VERSION "HNNBNNNYNNNNNNNNNNNNNNNNNNNNNNNNNNNNNNNNNN/4/%%%/4/'%**4NNN///"

NS_ :

BS_:

BU_: BAP_Tester BedienDisp_vo BedienSG_hi CGS DDA Gateway Gateway_PAG GurtMikrofon OTA_FC ZR_High ZR_LIMU ZR_MIB_TOP_ab_Gen3 ZR_Standard

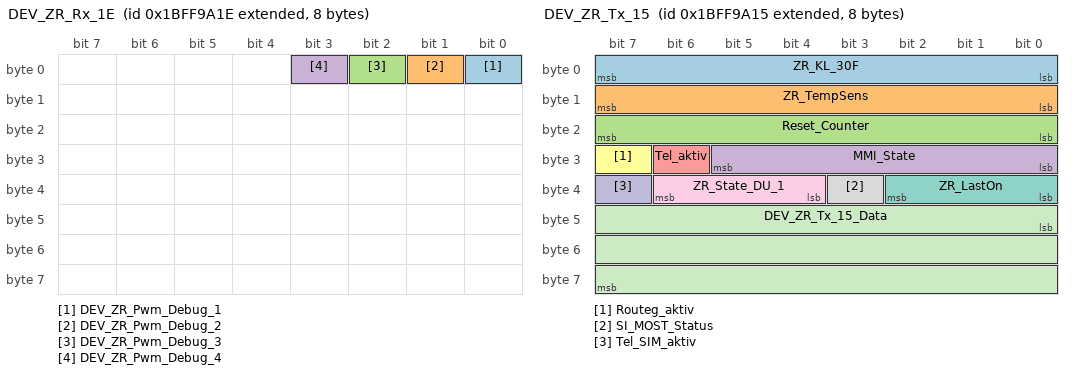
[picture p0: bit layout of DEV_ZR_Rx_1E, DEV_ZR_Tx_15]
BO_ 2617219614 DEV_ZR_Rx_1E: 8 Vector__XXX
 SG_ DEV_ZR_Pwm_Debug_1 : 0|1@1+ (1.0,0.0) [0.0|1] ""  ZR_High,ZR_MIB_TOP_ab_Gen3,ZR_Standard
 SG_ DEV_ZR_Pwm_Debug_2 : 1|1@1+ (1.0,0.0) [0.0|1] ""  ZR_High,ZR_MIB_TOP_ab_Gen3,ZR_Standard
 SG_ DEV_ZR_Pwm_Debug_3 : 2|1@1+ (1.0,0.0) [0.0|1] ""  ZR_High,ZR_MIB_TOP_ab_Gen3,ZR_Standard
 SG_ DEV_ZR_Pwm_Debug_4 : 3|1@1+ (1.0,0.0) [0.0|1] ""  ZR_High,ZR_MIB_TOP_ab_Gen3,ZR_Standard

BO_ 2617219604 DEV_ZR_Tx_14: 8 ZR_High
 SG_ DEV_ZR_Tx_14_Data : 0|64@1+ (1,0) [0|1] ""  Vector__XXX

BO_ 2617219605 DEV_ZR_Tx_15: 8 ZR_High
 SG_ ZR_KL_30F : 0|8@1+ (0.1,0) [0.0|25.3] "Unit_Volt"  Vector__XXX
 SG_ ZR_TempSens : 8|8@1+ (1,-55) [-55|127] "Unit_DegreCelsi"  Vector__XXX
 SG_ Reset_Counter : 16|8@1+ (1,0) [0|253] ""  Vector__XXX
 SG_ MMI_State : 24|6@1+ (1.0,0.0) [0.0|63] ""  Vector__XXX
 SG_ Tel_aktiv : 30|1@1+ (1.0,0.0) [0.0|1] ""  Vector__XXX
 SG_ Routeg_aktiv : 31|1@1+ (1.0,0.0) [0.0|1] ""  Vector__XXX
 SG_ ZR_LastOn : 32|3@1+ (1,0) [0|6] ""  Vector__XXX
 SG_ SI_MOST_Status : 35|1@1+ (1.0,0.0) [0.0|1] ""  Vector__XXX
 SG_ ZR_State_DU_1 : 36|3@1+ (1.0,0.0) [0.0|7] ""  Vector__XXX
 SG_ Tel_SIM_aktiv : 39|1@1+ (1.0,0.0) [0.0|1] ""  Vector__XXX
 SG_ DEV_ZR_Tx_15_Data : 40|24@1+ (1,0) [0|1] ""  Vector__XXX

BO_ 2549880610 DIA_SCON1_Req: 8 Gateway
 SG_ DIA_SCON1_Req_Data : 0|64@1+ (1.0,0.0) [0.0|18446744073709551615] ""  ZR_High,ZR_MIB_TOP_ab_Gen3

BO_ 2550011682 DIA_SCON1_Resp: 8 ZR_High
 SG_ DIA_SCON1_Resp_Data : 0|64@1+ (1.0,0.0) [0.0|18446744073709551615] ""  Gateway,Gateway_PAG

BO_ 2549880611 DIA_SCON2_Req: 8 Gateway
 SG_ DIA_SCON2_Req_Data : 0|64@1+ (1.0,0.0) [0.0|18446744073709551615] ""  ZR_High,ZR_MIB_TOP_ab_Gen3

BO_ 2550011683 DIA_SCON2_Resp: 8 ZR_High
 SG_ DIA_SCON2_Resp_Data : 0|64@1+ (1.0,0.0) [0.0|18446744073709551615] ""  Gateway,Gateway_PAG

BO_ 2549880473 DIA_SD3_Req: 8 Gateway
 SG_ DIA_SD3_Req_Data : 0|64@1+ (1.0,0.0) [0.0|18446744073709551615] ""  ZR_High,ZR_MIB_TOP_ab_Gen3

BO_ 2550011545 DIA_SD3_Resp: 8 ZR_High
 SG_ DIA_SD3_Resp_Data : 0|64@1+ (1.0,0.0) [0.0|18446744073709551615] ""  Gateway,Gateway_PAG

BO_ 2549880474 DIA_SD4_Req: 8 Gateway
 SG_ DIA_SD4_Req_Data : 0|64@1+ (1.0,0.0) [0.0|18446744073709551615] ""  ZR_High,ZR_MIB_TOP_ab_Gen3

BO_ 2550011546 DIA_SD4_Resp: 8 ZR_High
 SG_ DIA_SD4_Resp_Data : 0|64@1+ (1.0,0.0) [0.0|18446744073709551615] ""  Gateway,Gateway_PAG

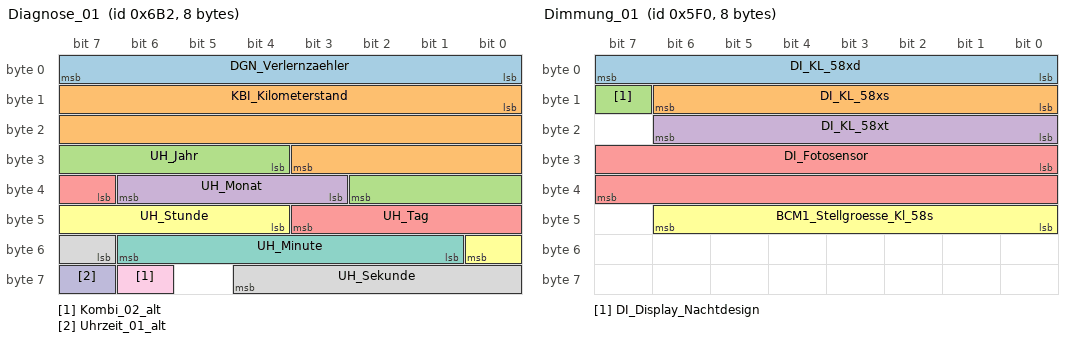
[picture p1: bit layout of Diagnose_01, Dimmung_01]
BO_ 1714 Diagnose_01: 8 Gateway
 SG_ DGN_Verlernzaehler : 0|8@1+ (1,0) [0|254] ""  BedienDisp_vo,BedienSG_hi,DDA,GurtMikrofon,OTA_FC,ZR_High,ZR_LIMU,ZR_MIB_TOP_ab_Gen3,ZR_Standard
 SG_ KBI_Kilometerstand : 8|20@1+ (1,0) [0|1048573] "Unit_KiloMeter"  BedienDisp_vo,BedienSG_hi,DDA,GurtMikrofon,OTA_FC,ZR_High,ZR_LIMU,ZR_MIB_TOP_ab_Gen3,ZR_Standard
 SG_ UH_Jahr : 28|7@1+ (1,2000) [2000|2127] "Unit_Year"  BedienDisp_vo,BedienSG_hi,DDA,GurtMikrofon,OTA_FC,ZR_High,ZR_LIMU,ZR_MIB_TOP_ab_Gen3,ZR_Standard
 SG_ UH_Monat : 35|4@1+ (1,0) [1|12] "Unit_Month"  BedienDisp_vo,BedienSG_hi,DDA,GurtMikrofon,OTA_FC,ZR_High,ZR_LIMU,ZR_MIB_TOP_ab_Gen3,ZR_Standard
 SG_ UH_Tag : 39|5@1+ (1,0) [1|31] "Unit_Day"  BedienDisp_vo,BedienSG_hi,DDA,GurtMikrofon,OTA_FC,ZR_High,ZR_LIMU,ZR_MIB_TOP_ab_Gen3,ZR_Standard
 SG_ UH_Stunde : 44|5@1+ (1,0) [0|23] "Unit_Hours"  BedienDisp_vo,BedienSG_hi,DDA,GurtMikrofon,OTA_FC,ZR_High,ZR_LIMU,ZR_MIB_TOP_ab_Gen3,ZR_Standard
 SG_ UH_Minute : 49|6@1+ (1,0) [0|59] "Unit_Minut"  BedienDisp_vo,BedienSG_hi,DDA,GurtMikrofon,OTA_FC,ZR_High,ZR_LIMU,ZR_MIB_TOP_ab_Gen3,ZR_Standard
 SG_ UH_Sekunde : 55|6@1+ (1,0) [0|59] "Unit_Secon"  BedienDisp_vo,BedienSG_hi,DDA,GurtMikrofon,OTA_FC,ZR_High,ZR_LIMU,ZR_MIB_TOP_ab_Gen3,ZR_Standard
 SG_ Kombi_02_alt : 62|1@1+ (1.0,0.0) [0.0|1] ""  OTA_FC,ZR_High,ZR_LIMU,ZR_MIB_TOP_ab_Gen3
 SG_ Uhrzeit_01_alt : 63|1@1+ (1.0,0.0) [0.0|1] ""  BedienDisp_vo,OTA_FC,ZR_High,ZR_LIMU,ZR_MIB_TOP_ab_Gen3

BO_ 1520 Dimmung_01: 8 Gateway
 SG_ DI_KL_58xd : 0|8@1+ (1,0) [0|253] ""  BedienDisp_vo,BedienSG_hi,ZR_High,ZR_LIMU,ZR_MIB_TOP_ab_Gen3,ZR_Standard
 SG_ DI_KL_58xs : 8|7@1+ (1,0) [0|100] "Unit_PerCent"  BedienDisp_vo,BedienSG_hi,ZR_High,ZR_LIMU,ZR_MIB_TOP_ab_Gen3,ZR_Standard
 SG_ DI_Display_Nachtdesign : 15|1@1+ (1.0,0.0) [0.0|1] ""  BedienSG_hi,ZR_High,ZR_LIMU,ZR_MIB_TOP_ab_Gen3,ZR_Standard
 SG_ DI_KL_58xt : 16|7@1+ (1,0) [0|100] "Unit_PerCent"  BedienDisp_vo,BedienSG_hi,ZR_High,ZR_LIMU,ZR_MIB_TOP_ab_Gen3,ZR_Standard
 SG_ DI_Fotosensor : 24|16@1+ (1,0) [0|65535] ""  BedienSG_hi,ZR_High,ZR_LIMU,ZR_MIB_TOP_ab_Gen3,ZR_Standard
 SG_ BCM1_Stellgroesse_Kl_58s : 40|7@1+ (1,0) [0|100] ""  ZR_High,ZR_LIMU,ZR_MIB_TOP_ab_Gen3,ZR_Standard

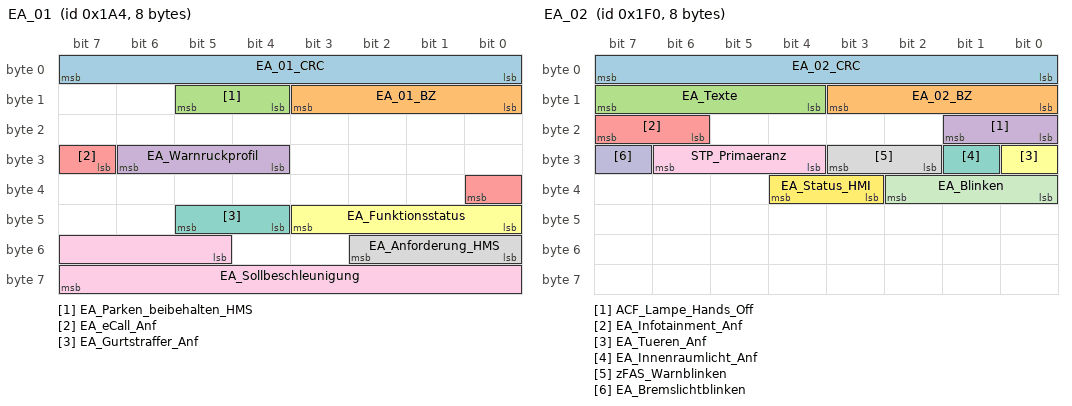
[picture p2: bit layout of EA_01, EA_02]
BO_ 420 EA_01: 8 Gateway
 SG_ EA_01_CRC : 0|8@1+ (1,0) [0|255] ""  Vector__XXX
 SG_ EA_01_BZ : 8|4@1+ (1,0) [0|15] ""  Vector__XXX
 SG_ EA_Parken_beibehalten_HMS : 12|2@1+ (1.0,0.0) [0.0|3] ""  Vector__XXX
 SG_ EA_Warnruckprofil : 28|3@1+ (1.0,0.0) [0.0|7] ""  Vector__XXX
 SG_ EA_eCall_Anf : 31|2@1+ (1.0,0.0) [0.0|3] ""  ZR_High
 SG_ EA_Funktionsstatus : 40|4@1+ (1.0,0.0) [0.0|15] ""  ZR_High
 SG_ EA_Gurtstraffer_Anf : 44|2@1+ (1.0,0.0) [0.0|3] ""  Vector__XXX
 SG_ EA_Anforderung_HMS : 48|3@1+ (1.0,0.0) [0.0|7] ""  Vector__XXX
 SG_ EA_Sollbeschleunigung : 53|11@1+ (0.005,-7.22) [-7.220|3.005] "Unit_MeterPerSeconSquar"  Vector__XXX

BO_ 496 EA_02: 8 Gateway
 SG_ EA_02_CRC : 0|8@1+ (1,0) [0|255] ""  Vector__XXX
 SG_ EA_02_BZ : 8|4@1+ (1,0) [0|15] ""  Vector__XXX
 SG_ EA_Texte : 12|4@1+ (1.0,0.0) [0.0|15] ""  ZR_High
 SG_ ACF_Lampe_Hands_Off : 16|2@1+ (1.0,0.0) [0.0|3] ""  Vector__XXX
 SG_ EA_Infotainment_Anf : 22|2@1+ (1.0,0.0) [0.0|3] ""  ZR_High,ZR_LIMU,ZR_MIB_TOP_ab_Gen3,ZR_Standard
 SG_ EA_Tueren_Anf : 24|1@1+ (1.0,0.0) [0.0|1] ""  ZR_High
 SG_ EA_Innenraumlicht_Anf : 25|1@1+ (1.0,0.0) [0.0|1] ""  ZR_High
 SG_ zFAS_Warnblinken : 26|2@1+ (1.0,0.0) [0.0|3] ""  ZR_High
 SG_ STP_Primaeranz : 28|3@1+ (1.0,0.0) [0.0|7] ""  Vector__XXX
 SG_ EA_Bremslichtblinken : 31|1@1+ (1.0,0.0) [0.0|1] ""  Vector__XXX
 SG_ EA_Blinken : 32|3@1+ (1.0,0.0) [0.0|7] ""  Vector__XXX
 SG_ EA_Status_HMI : 35|2@1+ (1.0,0.0) [0.0|3] ""  Vector__XXX

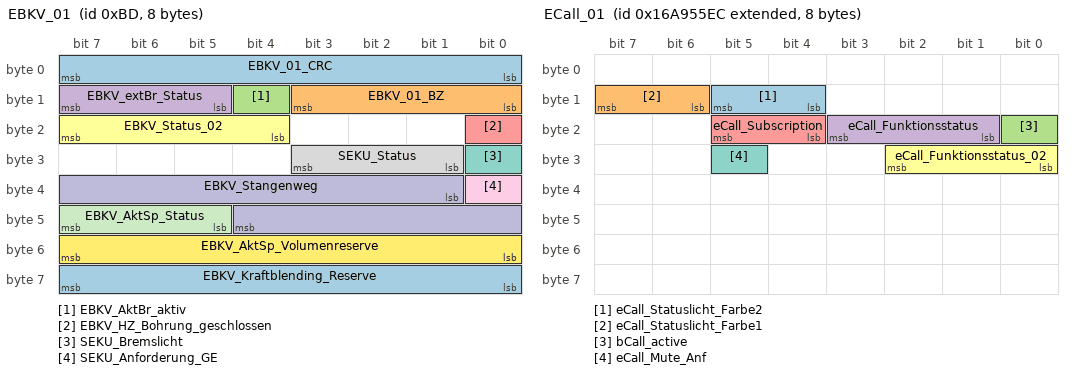
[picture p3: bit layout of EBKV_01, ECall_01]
BO_ 189 EBKV_01: 8 Gateway
 SG_ EBKV_01_CRC : 0|8@1+ (1,0) [0|255] ""  Vector__XXX
 SG_ EBKV_01_BZ : 8|4@1+ (1,0) [0|15] ""  Vector__XXX
 SG_ EBKV_AktBr_aktiv : 12|1@1+ (1.0,0.0) [0.0|1] ""  Vector__XXX
 SG_ EBKV_extBr_Status : 13|3@1+ (1.0,0.0) [0.0|7] ""  Vector__XXX
 SG_ EBKV_HZ_Bohrung_geschlossen : 16|1@1+ (1.0,0.0) [0.0|1] ""  Vector__XXX
 SG_ EBKV_Status_02 : 20|4@1+ (1.0,0.0) [0.0|15] ""  Vector__XXX
 SG_ SEKU_Bremslicht : 24|1@1+ (1.0,0.0) [0.0|1] ""  Vector__XXX
 SG_ SEKU_Status : 25|3@1+ (1.0,0.0) [0.0|7] ""  Vector__XXX
 SG_ SEKU_Anforderung_GE : 32|1@1+ (1.0,0.0) [0.0|1] ""  Vector__XXX
 SG_ EBKV_Stangenweg : 33|12@1+ (0.015625,-5) [-5.000000|47.000000] "Unit_MilliMeter"  ZR_MIB_TOP_ab_Gen3
 SG_ EBKV_AktSp_Status : 45|3@1+ (1.0,0.0) [0.0|7] ""  Vector__XXX
 SG_ EBKV_AktSp_Volumenreserve : 48|8@1+ (0.02,0) [0.00|5.00] "Unit_MilliLiter"  Vector__XXX
 SG_ EBKV_Kraftblending_Reserve : 56|8@1+ (0.5,0) [0.0|125.0] "Unit_Bar"  Vector__XXX

BO_ 2527679980 ECall_01: 8 Gateway
 SG_ eCall_Statuslicht_Farbe2 : 12|2@1+ (1.0,0.0) [0.0|3] ""  ZR_High
 SG_ eCall_Statuslicht_Farbe1 : 14|2@1+ (1.0,0.0) [0.0|3] ""  ZR_High
 SG_ bCall_active : 16|1@1+ (1.0,0.0) [0.0|1] ""  OTA_FC,ZR_High
 SG_ eCall_Funktionsstatus : 17|3@1+ (1.0,0.0) [0.0|7] ""  ZR_High
 SG_ eCall_Subscription : 20|2@1+ (1.0,0.0) [0.0|3] ""  Vector__XXX
 SG_ eCall_Funktionsstatus_02 : 24|3@1+ (1.0,0.0) [0.0|7] ""  ZR_High
 SG_ eCall_Mute_Anf : 29|1@1+ (1.0,0.0) [0.0|1] ""  Vector__XXX

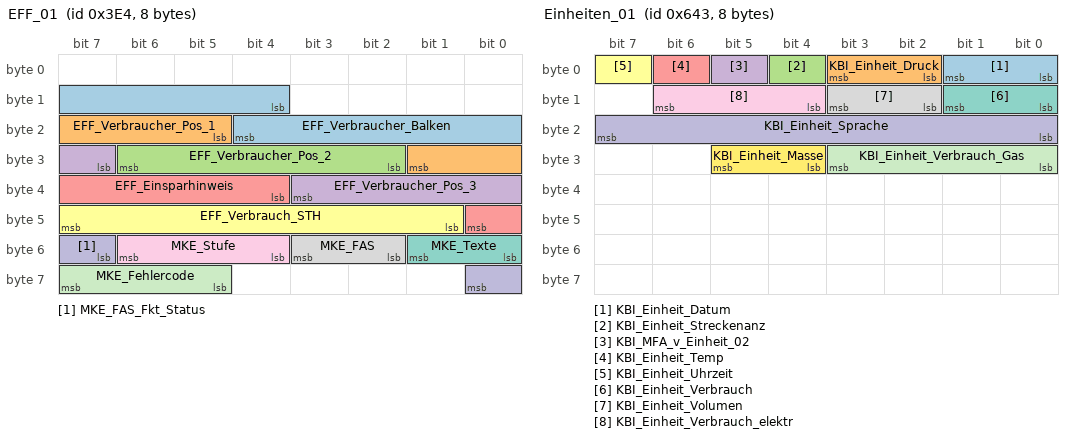
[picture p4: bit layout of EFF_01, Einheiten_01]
BO_ 996 EFF_01: 8 Gateway
 SG_ EFF_Verbraucher_Balken : 12|9@1+ (0.01,0) [0.00|5.09] "Unit_LiterPerHour"  Vector__XXX
 SG_ EFF_Verbraucher_Pos_1 : 21|5@1+ (1.0,0.0) [0.0|31] ""  Vector__XXX
 SG_ EFF_Verbraucher_Pos_2 : 26|5@1+ (1.0,0.0) [0.0|31] ""  Vector__XXX
 SG_ EFF_Verbraucher_Pos_3 : 31|5@1+ (1.0,0.0) [0.0|31] ""  Vector__XXX
 SG_ EFF_Einsparhinweis : 36|5@1+ (1.0,0.0) [0.0|31] ""  Vector__XXX
 SG_ EFF_Verbrauch_STH : 41|7@1+ (0.01,0) [0.00|1.26] "Unit_LiterPerHour"  ZR_High
 SG_ MKE_Texte : 48|2@1+ (1.0,0.0) [0.0|3] ""  ZR_High
 SG_ MKE_FAS : 50|2@1+ (1.0,0.0) [0.0|3] ""  ZR_High
 SG_ MKE_Stufe : 52|3@1+ (1.0,0.0) [0.0|7] ""  ZR_High
 SG_ MKE_FAS_Fkt_Status : 55|2@1+ (1.0,0.0) [0.0|3] ""  ZR_High
 SG_ MKE_Fehlercode : 61|3@1+ (1.0,0.0) [0.0|7] ""  Vector__XXX

BO_ 1603 Einheiten_01: 8 Gateway
 SG_ KBI_Einheit_Datum : 0|2@1+ (1.0,0.0) [0.0|3] ""  BedienSG_hi,OTA_FC,ZR_High,ZR_Standard
 SG_ KBI_Einheit_Druck : 2|2@1+ (1.0,0.0) [0.0|3] ""  BedienSG_hi,OTA_FC,ZR_High,ZR_Standard
 SG_ KBI_Einheit_Streckenanz : 4|1@1+ (1.0,0.0) [0.0|1] ""  BedienSG_hi,OTA_FC,ZR_High,ZR_Standard
 SG_ KBI_MFA_v_Einheit_02 : 5|1@1+ (1.0,0.0) [0.0|1] ""  OTA_FC,ZR_High,ZR_Standard
 SG_ KBI_Einheit_Temp : 6|1@1+ (1.0,0.0) [0.0|1] ""  BedienDisp_vo,BedienSG_hi,OTA_FC,ZR_High,ZR_Standard
 SG_ KBI_Einheit_Uhrzeit : 7|1@1+ (1.0,0.0) [0.0|1] ""  BedienSG_hi,OTA_FC,ZR_High,ZR_Standard
 SG_ KBI_Einheit_Verbrauch : 8|2@1+ (1.0,0.0) [0.0|3] ""  BedienSG_hi,OTA_FC,ZR_High,ZR_Standard
 SG_ KBI_Einheit_Volumen : 10|2@1+ (1.0,0.0) [0.0|3] ""  BedienSG_hi,OTA_FC,ZR_High,ZR_Standard
 SG_ KBI_Einheit_Verbrauch_elektr : 12|3@1+ (1.0,0.0) [0.0|7] ""  OTA_FC
 SG_ KBI_Einheit_Sprache : 16|8@1+ (1,0) [0|255] ""  BedienSG_hi,OTA_FC,ZR_High,ZR_Standard
 SG_ KBI_Einheit_Verbrauch_Gas : 24|4@1+ (1.0,0.0) [0.0|15] ""  Vector__XXX
 SG_ KBI_Einheit_Masse : 28|2@1+ (1.0,0.0) [0.0|3] ""  OTA_FC

BO_ 1622 ELV_01: 8 Gateway
 SG_ ELV_01_CRC : 0|8@1+ (1,0) [0|255] ""  Vector__XXX
 SG_ ELV_01_BZ : 8|4@1+ (1,0) [0|15] ""  Vector__XXX
 SG_ ELV_Anf_Klemme_S : 12|1@1+ (1.0,0.0) [0.0|1] ""  Vector__XXX
 SG_ ELV_Anf_Klemme_15 : 13|1@1+ (1.0,0.0) [0.0|1] ""  Vector__XXX
 SG_ ELV_Anf_Klemme_50 : 14|1@1+ (1.0,0.0) [0.0|1] ""  Vector__XXX
 SG_ ELV_01_Sendestatus : 15|1@1+ (1.0,0.0) [0.0|1] ""  Vector__XXX
 SG_ ELV_Verriegelt : 16|1@1+ (1.0,0.0) [0.0|1] ""  ZR_High
 SG_ ELV_Entriegelt : 17|1@1+ (1.0,0.0) [0.0|1] ""  ZR_High
 SG_ ELV_ZAT_betaetigt : 18|1@1+ (1.0,0.0) [0.0|1] ""  Vector__XXX
 SG_ ELV_Lebenszustand : 19|1@1+ (1.0,0.0) [0.0|1] ""  Vector__XXX
 SG_ ELV_Anlernmodus : 20|1@1+ (1.0,0.0) [0.0|1] ""  Vector__XXX
 SG_ ELV_Klemmenfreigabe : 22|1@1+ (1.0,0.0) [0.0|1] ""  Vector__XXX
 SG_ ELV_Abbruch_Anf_Klemmenfreigabe : 23|1@1+ (1.0,0.0) [0.0|1] ""  Vector__XXX
 SG_ ELV_LED_Rot : 24|1@1+ (1.0,0.0) [0.0|1] ""  ZR_High
 SG_ ELV_LED_Gelb : 25|1@1+ (1.0,0.0) [0.0|1] ""  Vector__XXX
 SG_ ELV_Txt_Panikabschaltung : 27|1@1+ (1.0,0.0) [0.0|1] ""  Vector__XXX
 SG_ ELV_Txt_Lkg_Bewegen : 28|1@1+ (1.0,0.0) [0.0|1] ""  ZR_High
 SG_ ELV_Txt_Werkstatt : 29|1@1+ (1.0,0.0) [0.0|1] ""  ZR_High
 SG_ ELV_Txt_Defekt : 30|1@1+ (1.0,0.0) [0.0|1] ""  ZR_High
 SG_ ELV_Txt_P_Gang : 31|1@1+ (1.0,0.0) [0.0|1] ""  Vector__XXX
 SG_ ELV_Txt_PN_Gang : 32|1@1+ (1.0,0.0) [0.0|1] ""  Vector__XXX
 SG_ ELV_Txt_Kupplung : 33|1@1+ (1.0,0.0) [0.0|1] ""  Vector__XXX
 SG_ ELV_Txt_Bremse : 34|1@1+ (1.0,0.0) [0.0|1] ""  Vector__XXX
 SG_ ELV_P_verriegelt : 35|1@1+ (1.0,0.0) [0.0|1] ""  Vector__XXX

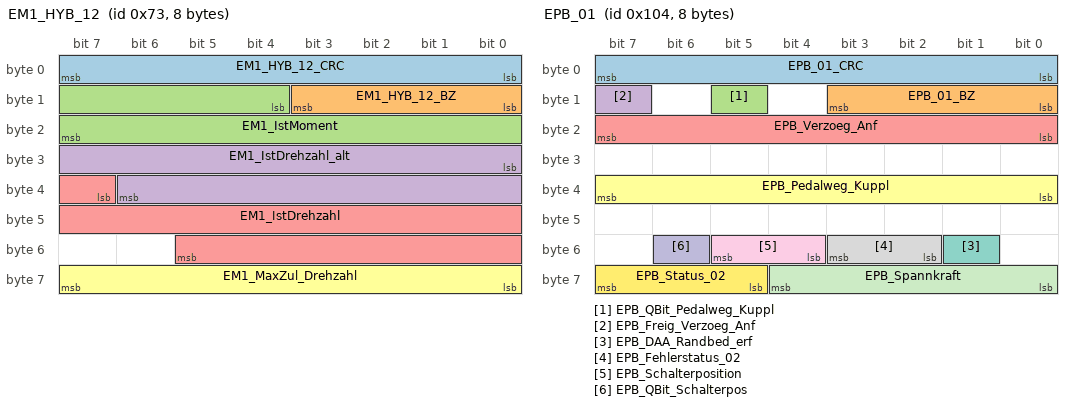
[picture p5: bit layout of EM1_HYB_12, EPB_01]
BO_ 115 EM1_HYB_12: 8 Gateway
 SG_ EM1_HYB_12_CRC : 0|8@1+ (1,0) [0|255] ""  Vector__XXX
 SG_ EM1_HYB_12_BZ : 8|4@1+ (1,0) [0|15] ""  Vector__XXX
 SG_ EM1_IstMoment : 12|12@1+ (0.5,-1023) [-1023.0|1023.5] "Unit_NewtoMeter"  ZR_MIB_TOP_ab_Gen3
 SG_ EM1_IstDrehzahl_alt : 24|15@1+ (1,-10000) [-10000|22765] "Unit_MinutInver"  Vector__XXX
 SG_ EM1_IstDrehzahl : 39|15@1+ (1,-10000) [-10000|22765] "Unit_MinutInver"  ZR_MIB_TOP_ab_Gen3
 SG_ EM1_MaxZul_Drehzahl : 56|8@1+ (80,0) [0|20240] "Unit_RevPerMinute"  Vector__XXX

BO_ 260 EPB_01: 8 Gateway
 SG_ EPB_01_CRC : 0|8@1+ (1,0) [0|255] ""  Vector__XXX
 SG_ EPB_01_BZ : 8|4@1+ (1,0) [0|15] ""  Vector__XXX
 SG_ EPB_QBit_Pedalweg_Kuppl : 13|1@1+ (1.0,0.0) [0.0|1] ""  Vector__XXX
 SG_ EPB_Freig_Verzoeg_Anf : 15|1@1+ (1.0,0.0) [0.0|1] ""  Vector__XXX
 SG_ EPB_Verzoeg_Anf : 16|8@1+ (0.048,-7.968) [-7.968|4.224] "Unit_MeterPerSeconSquar"  Vector__XXX
 SG_ EPB_Pedalweg_Kuppl : 32|8@1+ (0.4,0) [8.0|92.0] "Unit_PerCent"  Vector__XXX
 SG_ EPB_DAA_Randbed_erf : 49|1@1+ (1.0,0.0) [0.0|1] ""  Vector__XXX
 SG_ EPB_Fehlerstatus_02 : 50|2@1+ (1.0,0.0) [0.0|3] ""  Vector__XXX
 SG_ EPB_Schalterposition : 52|2@1+ (1.0,0.0) [0.0|3] ""  OTA_FC
 SG_ EPB_QBit_Schalterpos : 54|1@1+ (1.0,0.0) [0.0|1] ""  Vector__XXX
 SG_ EPB_Spannkraft : 56|5@1+ (1,0) [0|29] "Unit_KiloNewto"  Vector__XXX
 SG_ EPB_Status_02 : 61|3@1+ (1.0,0.0) [0.0|7] ""  OTA_FC,ZR_High,ZR_LIMU,ZR_MIB_TOP_ab_Gen3,ZR_Standard

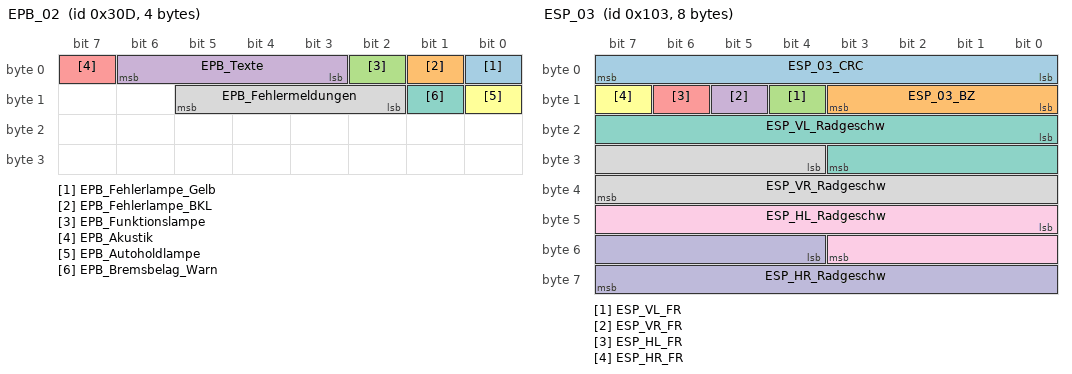
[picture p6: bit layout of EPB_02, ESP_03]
BO_ 781 EPB_02: 4 Gateway
 SG_ EPB_Fehlerlampe_Gelb : 0|1@1+ (1.0,0.0) [0.0|1] ""  Vector__XXX
 SG_ EPB_Fehlerlampe_BKL : 1|1@1+ (1.0,0.0) [0.0|1] ""  Vector__XXX
 SG_ EPB_Funktionslampe : 2|1@1+ (1.0,0.0) [0.0|1] ""  ZR_High
 SG_ EPB_Texte : 3|4@1+ (1.0,0.0) [0.0|15] ""  ZR_High
 SG_ EPB_Akustik : 7|1@1+ (1.0,0.0) [0.0|1] ""  Vector__XXX
 SG_ EPB_Autoholdlampe : 8|1@1+ (1.0,0.0) [0.0|1] ""  ZR_High
 SG_ EPB_Bremsbelag_Warn : 9|1@1+ (1.0,0.0) [0.0|1] ""  Vector__XXX
 SG_ EPB_Fehlermeldungen : 10|4@1+ (1.0,0.0) [0.0|15] ""  ZR_High

BO_ 259 ESP_03: 8 Gateway
 SG_ ESP_03_CRC : 0|8@1+ (1,0) [0|255] ""  Vector__XXX
 SG_ ESP_03_BZ : 8|4@1+ (1,0) [0|15] ""  Vector__XXX
 SG_ ESP_VL_FR : 12|1@1+ (1.0,0.0) [0.0|1] ""  OTA_FC
 SG_ ESP_VR_FR : 13|1@1+ (1.0,0.0) [0.0|1] ""  OTA_FC
 SG_ ESP_HL_FR : 14|1@1+ (1.0,0.0) [0.0|1] ""  OTA_FC
 SG_ ESP_HR_FR : 15|1@1+ (1.0,0.0) [0.0|1] ""  OTA_FC
 SG_ ESP_VL_Radgeschw : 16|12@1+ (0.1,0) [0.0|409.2] "Unit_KiloMeterPerHour"  OTA_FC,ZR_High,ZR_LIMU,ZR_MIB_TOP_ab_Gen3
 SG_ ESP_VR_Radgeschw : 28|12@1+ (0.1,0) [0.0|409.2] "Unit_KiloMeterPerHour"  OTA_FC,ZR_High,ZR_LIMU,ZR_MIB_TOP_ab_Gen3
 SG_ ESP_HL_Radgeschw : 40|12@1+ (0.1,0) [0.0|409.2] "Unit_KiloMeterPerHour"  OTA_FC,ZR_High,ZR_LIMU,ZR_MIB_TOP_ab_Gen3
 SG_ ESP_HR_Radgeschw : 52|12@1+ (0.1,0) [0.0|409.2] "Unit_KiloMeterPerHour"  OTA_FC,ZR_High,ZR_LIMU,ZR_MIB_TOP_ab_Gen3

BO_ 262 ESP_05: 8 Gateway
 SG_ ESP_05_CRC : 0|8@1+ (1,0) [0|255] ""  Vector__XXX
 SG_ ESP_05_BZ : 8|4@1+ (1,0) [0|15] ""  Vector__XXX
 SG_ ESP_QBit_Bremsdruck : 12|1@1+ (1.0,0.0) [0.0|1] ""  ZR_High,ZR_LIMU,ZR_MIB_TOP_ab_Gen3,ZR_Standard
 SG_ ESP_QBit_Fahrer_bremst : 13|1@1+ (1.0,0.0) [0.0|1] ""  Vector__XXX
 SG_ ESP_Schwelle_Unterdruck : 14|2@1+ (1.0,0.0) [0.0|3] ""  Vector__XXX
 SG_ ESP_Bremsdruck : 16|10@1+ (0.3,-30) [-30.0|276.6] "Unit_Bar"  OTA_FC,ZR_High,ZR_LIMU,ZR_MIB_TOP_ab_Gen3,ZR_Standard
 SG_ ESP_Fahrer_bremst : 26|1@1+ (1.0,0.0) [0.0|1] ""  Vector__XXX
 SG_ ESP_Lenkeingriff_ADS : 28|1@1+ (1.0,0.0) [0.0|1] ""  ZR_High
 SG_ ECD_Fehler : 32|1@1+ (1.0,0.0) [0.0|1] ""  Vector__XXX
 SG_ ECD_nicht_verfuegbar : 33|1@1+ (1.0,0.0) [0.0|1] ""  Vector__XXX
 SG_ ESP_Status_Bremsentemp : 34|1@1+ (1.0,0.0) [0.0|1] ""  Vector__XXX
 SG_ ESP_Autohold_Standby : 35|1@1+ (1.0,0.0) [0.0|1] ""  Vector__XXX
 SG_ ESP_HDC_Standby : 36|1@1+ (1.0,0.0) [0.0|1] ""  Vector__XXX
 SG_ ESP_HBA_aktiv : 37|1@1+ (1.0,0.0) [0.0|1] ""  Vector__XXX
 SG_ ESP_Prefill_ausgeloest : 38|1@1+ (1.0,0.0) [0.0|1] ""  Vector__XXX
 SG_ ESP_Rueckwaertsfahrt_erkannt : 39|1@1+ (1.0,0.0) [0.0|1] ""  Vector__XXX
 SG_ ESP_Status_Anfahrhilfe : 40|1@1+ (1.0,0.0) [0.0|1] ""  ZR_High
 SG_ ESP_HDC_aktiv : 41|1@1+ (1.0,0.0) [0.0|1] ""  ZR_High
 SG_ ESP_StartStopp_Info : 42|2@1+ (1.0,0.0) [0.0|3] ""  Vector__XXX
 SG_ ESP_Eingr_HL : 44|1@1+ (1.0,0.0) [0.0|1] ""  ZR_High,ZR_LIMU,ZR_MIB_TOP_ab_Gen3
 SG_ ESP_Eingr_HR : 45|1@1+ (1.0,0.0) [0.0|1] ""  ZR_High,ZR_LIMU,ZR_MIB_TOP_ab_Gen3
 SG_ ESP_Eingr_VL : 46|1@1+ (1.0,0.0) [0.0|1] ""  ZR_High,ZR_LIMU,ZR_MIB_TOP_ab_Gen3
 SG_ ESP_Eingr_VR : 47|1@1+ (1.0,0.0) [0.0|1] ""  ZR_High,ZR_LIMU,ZR_MIB_TOP_ab_Gen3
 SG_ ESP_BKV_Unterdruck : 48|8@1+ (4,0) [4|1012] "Unit_MilliBar"  Vector__XXX
 SG_ ESP_Autohold_aktiv : 56|1@1+ (1.0,0.0) [0.0|1] ""  ZR_High
 SG_ ESP_FStatus_Anfahrhilfe : 57|1@1+ (1.0,0.0) [0.0|1] ""  Vector__XXX
 SG_ ESP_Verz_EPB_aktiv : 58|1@1+ (1.0,0.0) [0.0|1] ""  Vector__XXX
 SG_ ESC_Bremslicht : 59|1@1+ (1.0,0.0) [0.0|1] ""  Vector__XXX
 SG_ ESP_Verzoeg_EPB_verf : 60|1@1+ (1.0,0.0) [0.0|1] ""  Vector__XXX
 SG_ ESP_Status_Bremsdruck : 61|1@1+ (1.0,0.0) [0.0|1] ""  Vector__XXX
 SG_ ESP_Anforderung_EPB : 62|2@1+ (1.0,0.0) [0.0|3] ""  Vector__XXX

BO_ 914 ESP_07: 8 Gateway
 SG_ ESP_07_CRC : 0|8@1+ (1,0) [0|255] ""  Vector__XXX
 SG_ ESP_07_BZ : 8|4@1+ (1,0) [0|15] ""  Vector__XXX
 SG_ ESP_Allrad_Antrieb : 13|1@1+ (1.0,0.0) [0.0|1] ""  Vector__XXX
 SG_ ESP_Codierung_ADS : 14|2@1+ (1.0,0.0) [0.0|3] ""  Vector__XXX
 SG_ ESP_RTA_HL : 16|8@1+ (0.048828125,-6.20117) [-6.201170000|6.152345625] "Unit_PerCent"  Vector__XXX
 SG_ ESP_RTA_HR : 24|8@1+ (0.048828125,-6.20117) [-6.201170000|6.152345625] "Unit_PerCent"  Vector__XXX
 SG_ ESP_RTA_VR : 32|8@1+ (0.048828125,-6.20117) [-6.201170000|6.152345625] "Unit_PerCent"  Vector__XXX
 SG_ OBD_Fehler_Radsensor_HL : 40|4@1+ (1.0,0.0) [0.0|15] ""  Vector__XXX
 SG_ OBD_Fehler_Radsensor_HR : 44|4@1+ (1.0,0.0) [0.0|15] ""  Vector__XXX
 SG_ OBD_Fehler_Radsensor_VL : 48|4@1+ (1.0,0.0) [0.0|15] ""  Vector__XXX
 SG_ OBD_Fehler_Radsensor_VR : 52|4@1+ (1.0,0.0) [0.0|15] ""  Vector__XXX
 SG_ ESP_Qualifizierung_Antriebsart : 56|1@1+ (1.0,0.0) [0.0|1] ""  Vector__XXX
 SG_ ESP_Offroad_Modus : 57|1@1+ (1.0,0.0) [0.0|1] ""  Vector__XXX
 SG_ ESP_MKB_ausloesbar : 58|1@1+ (1.0,0.0) [0.0|1] ""  Vector__XXX
 SG_ ESP_Stat_FallBack_eBKV : 59|1@1+ (1.0,0.0) [0.0|1] ""  Vector__XXX
 SG_ ESC_cAQP_Trigger : 60|1@1+ (1.0,0.0) [0.0|1] ""  Vector__XXX
 SG_ ESP_OBD_Status : 61|1@1+ (1.0,0.0) [0.0|1] ""  Vector__XXX
 SG_ ESP_Rollenmodus_Deaktivieren : 62|1@1+ (1.0,0.0) [0.0|1] ""  ZR_High,ZR_LIMU,ZR_MIB_TOP_ab_Gen3
 SG_ ESP_nachtr_Stopp_Anf : 63|1@1+ (1.0,0.0) [0.0|1] ""  Vector__XXX

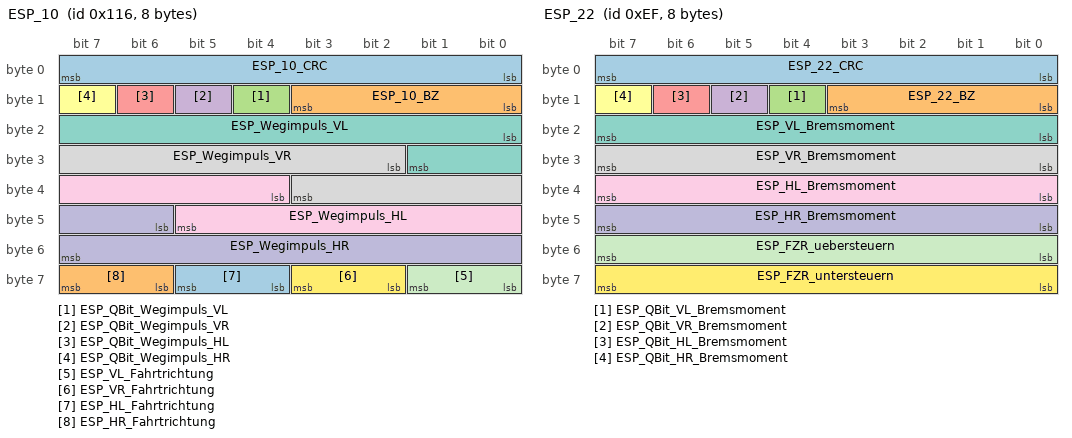
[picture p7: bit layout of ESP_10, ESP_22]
BO_ 278 ESP_10: 8 Gateway
 SG_ ESP_10_CRC : 0|8@1+ (1,0) [0|255] ""  Vector__XXX
 SG_ ESP_10_BZ : 8|4@1+ (1,0) [0|15] ""  Vector__XXX
 SG_ ESP_QBit_Wegimpuls_VL : 12|1@1+ (1.0,0.0) [0.0|1] ""  ZR_High,ZR_LIMU,ZR_MIB_TOP_ab_Gen3,ZR_Standard
 SG_ ESP_QBit_Wegimpuls_VR : 13|1@1+ (1.0,0.0) [0.0|1] ""  ZR_High,ZR_LIMU,ZR_MIB_TOP_ab_Gen3,ZR_Standard
 SG_ ESP_QBit_Wegimpuls_HL : 14|1@1+ (1.0,0.0) [0.0|1] ""  ZR_High,ZR_LIMU,ZR_MIB_TOP_ab_Gen3,ZR_Standard
 SG_ ESP_QBit_Wegimpuls_HR : 15|1@1+ (1.0,0.0) [0.0|1] ""  ZR_High,ZR_LIMU,ZR_MIB_TOP_ab_Gen3,ZR_Standard
 SG_ ESP_Wegimpuls_VL : 16|10@1+ (1,0) [0|1000] ""  ZR_High,ZR_LIMU,ZR_MIB_TOP_ab_Gen3,ZR_Standard
 SG_ ESP_Wegimpuls_VR : 26|10@1+ (1,0) [0|1000] ""  ZR_High,ZR_LIMU,ZR_MIB_TOP_ab_Gen3,ZR_Standard
 SG_ ESP_Wegimpuls_HL : 36|10@1+ (1,0) [0|1000] ""  ZR_High,ZR_LIMU,ZR_MIB_TOP_ab_Gen3,ZR_Standard
 SG_ ESP_Wegimpuls_HR : 46|10@1+ (1,0) [0|1000] ""  ZR_High,ZR_LIMU,ZR_MIB_TOP_ab_Gen3,ZR_Standard
 SG_ ESP_VL_Fahrtrichtung : 56|2@1+ (1.0,0.0) [0.0|3] ""  OTA_FC,ZR_High,ZR_LIMU,ZR_MIB_TOP_ab_Gen3,ZR_Standard
 SG_ ESP_VR_Fahrtrichtung : 58|2@1+ (1.0,0.0) [0.0|3] ""  OTA_FC,ZR_High,ZR_LIMU,ZR_MIB_TOP_ab_Gen3,ZR_Standard
 SG_ ESP_HL_Fahrtrichtung : 60|2@1+ (1.0,0.0) [0.0|3] ""  OTA_FC,ZR_High,ZR_LIMU,ZR_MIB_TOP_ab_Gen3,ZR_Standard
 SG_ ESP_HR_Fahrtrichtung : 62|2@1+ (1.0,0.0) [0.0|3] ""  OTA_FC,ZR_High,ZR_LIMU,ZR_MIB_TOP_ab_Gen3,ZR_Standard

BO_ 418 ESP_15: 8 Gateway
 SG_ ESP_15_CRC : 0|8@1+ (1,0) [0|255] ""  Vector__XXX
 SG_ ESP_15_BZ : 8|4@1+ (1,0) [0|15] ""  Vector__XXX
 SG_ HMS_P_beibehalten_GE : 12|2@1+ (1.0,0.0) [0.0|3] ""  Vector__XXX
 SG_ HMS_Konsistenz_GE : 14|1@1+ (1.0,0.0) [0.0|1] ""  Vector__XXX
 SG_ HMS_Konsistenz_IPA : 15|1@1+ (1.0,0.0) [0.0|1] ""  Vector__XXX
 SG_ HMS_Konsistenz_STA : 18|1@1+ (1.0,0.0) [0.0|1] ""  Vector__XXX
 SG_ HMS_Konsistenz_MO : 19|1@1+ (1.0,0.0) [0.0|1] ""  Vector__XXX
 SG_ HMS_halten_nicht_verfuegbar : 20|1@1+ (1.0,0.0) [0.0|1] ""  Vector__XXX
 SG_ NL_PRIM_STP_01_Status : 21|3@1+ (1.0,0.0) [0.0|7] ""  Vector__XXX
 SG_ VMM_Warnblinken : 24|1@1+ (1.0,0.0) [0.0|1] ""  Vector__XXX
 SG_ VZM_Status : 26|3@1+ (1.0,0.0) [0.0|7] ""  Vector__XXX
 SG_ HMS_Notstopp_Status : 29|3@1+ (1.0,0.0) [0.0|7] ""  Vector__XXX
 SG_ HMS_parken_nicht_verfuegbar : 32|1@1+ (1.0,0.0) [0.0|1] ""  Vector__XXX
 SG_ HMS_Anforderung_GE : 33|3@1+ (1.0,0.0) [0.0|7] ""  Vector__XXX
 SG_ HMS_Systemstatus : 36|4@1+ (1.0,0.0) [0.0|15] ""  DDA,ZR_High
 SG_ HMS_Stillstand : 40|3@1+ (1.0,0.0) [0.0|7] ""  Vector__XXX
 SG_ HMS_aktives_System : 43|5@1+ (1.0,0.0) [0.0|31] ""  Vector__XXX
 SG_ HMS_Konsistenz_HVLM : 48|1@1+ (1.0,0.0) [0.0|1] ""  Vector__XXX
 SG_ HMS_Konsistenz_ACC : 49|1@1+ (1.0,0.0) [0.0|1] ""  Vector__XXX
 SG_ HMS_Fehlerstatus : 50|3@1+ (1.0,0.0) [0.0|7] ""  Vector__XXX
 SG_ ESP_Index_Haltemoment : 53|1@1+ (1.0,0.0) [0.0|1] ""  Vector__XXX
 SG_ ESP_Haltemoment : 54|10@1+ (10,0) [0|10210] "Unit_NewtoMeter"  Vector__XXX

BO_ 1629 ESP_20: 8 Gateway
 SG_ ESP_20_CRC : 0|8@1+ (1,0) [0|255] ""  Vector__XXX
 SG_ ESP_20_BZ : 8|4@1+ (1,0) [0|15] ""  Vector__XXX
 SG_ BR_Systemart : 12|2@1+ (1.0,0.0) [0.0|3] ""  Vector__XXX
 SG_ ESP_SpannungsAnf_02 : 14|2@1+ (1.0,0.0) [0.0|3] ""  Vector__XXX
 SG_ ESP_Zaehnezahl : 16|8@1+ (1,0) [0|255] ""  ZR_High,ZR_LIMU,ZR_MIB_TOP_ab_Gen3,ZR_Standard
 SG_ ESP_Charisma_FahrPr : 24|4@1+ (1.0,0.0) [0.0|15] ""  Vector__XXX
 SG_ ESP_Charisma_Status : 28|2@1+ (1.0,0.0) [0.0|3] ""  Vector__XXX
 SG_ ESP_Wiederstart_Anz_01 : 30|1@1+ (1.0,0.0) [0.0|1] ""  ZR_High
 SG_ ESP_Wiederstart_Anz_02 : 31|1@1+ (1.0,0.0) [0.0|1] ""  Vector__XXX
 SG_ ESP_Wiederstart_Anz_03 : 32|1@1+ (1.0,0.0) [0.0|1] ""  Vector__XXX
 SG_ ESP_Wiederstart_Anz_04 : 33|1@1+ (1.0,0.0) [0.0|1] ""  ZR_High
 SG_ ESP_Stoppverbot_Anz_01 : 34|1@1+ (1.0,0.0) [0.0|1] ""  ZR_High
 SG_ ESP_Stoppverbot_Anz_02 : 35|1@1+ (1.0,0.0) [0.0|1] ""  Vector__XXX
 SG_ ESP_Stoppverbot_Anz_03 : 36|1@1+ (1.0,0.0) [0.0|1] ""  Vector__XXX
 SG_ ESP_Stoppverbot_Anz_04 : 37|1@1+ (1.0,0.0) [0.0|1] ""  Vector__XXX
 SG_ ESP_Stoppverbot_Anz_05 : 38|1@1+ (1.0,0.0) [0.0|1] ""  ZR_High
 SG_ ESP_Stoppverbot_Anz_06 : 39|1@1+ (1.0,0.0) [0.0|1] ""  ZR_High
 SG_ ESP_Stoppverbot_Anz_07 : 40|1@1+ (1.0,0.0) [0.0|1] ""  Vector__XXX
 SG_ ESP_Stoppverbot_Anz_Std : 41|1@1+ (1.0,0.0) [0.0|1] ""  Vector__XXX
 SG_ ESP_Dachrelingsensor : 42|2@1+ (1.0,0.0) [0.0|3] ""  ZR_High
 SG_ ESP_Stoppverbot_Anz_08 : 44|1@1+ (1.0,0.0) [0.0|1] ""  Vector__XXX
 SG_ HDC_Charisma_FahrPr : 45|4@1+ (1.0,0.0) [0.0|15] ""  Vector__XXX
 SG_ HDC_Charisma_Status : 49|2@1+ (1.0,0.0) [0.0|3] ""  Vector__XXX
 SG_ BR_QBit_Reifenumfang : 51|1@1+ (1.0,0.0) [0.0|1] ""  ZR_High
 SG_ BR_Reifenumfang : 52|12@1+ (1,0) [0|4095] "Unit_MilliMeter"  ZR_High

BO_ 253 ESP_21: 8 Gateway
 SG_ ESP_21_CRC : 0|8@1+ (1,0) [0|255] ""  Vector__XXX
 SG_ ESP_21_BZ : 8|4@1+ (1,0) [0|15] ""  Vector__XXX
 SG_ BR_Eingriffsmoment : 12|10@1+ (1,-509) [-509|509] ""  Vector__XXX
 SG_ MSR_verfuegbar : 22|1@1+ (1.0,0.0) [0.0|1] ""  Vector__XXX
 SG_ ESP_Diagnose : 23|1@1+ (1.0,0.0) [0.0|1] ""  ZR_High
 SG_ ESC_v_Signal_Qualifier_High_Low : 24|3@1+ (1.0,0.0) [0.0|7] ""  Vector__XXX
 SG_ ESP_Vorsteuerung : 28|1@1+ (1.0,0.0) [0.0|1] ""  OTA_FC
 SG_ OBD_Schlechtweg : 30|1@1+ (1.0,0.0) [0.0|1] ""  ZR_High
 SG_ OBD_QBit_Schlechtweg : 31|1@1+ (1.0,0.0) [0.0|1] ""  ZR_High
 SG_ ESP_v_Signal : 32|16@1+ (0.01,0) [0.00|655.32] "Unit_KiloMeterPerHour"  BedienSG_hi,DDA,OTA_FC,ZR_High,ZR_LIMU,ZR_MIB_TOP_ab_Gen3,ZR_Standard
 SG_ ASR_Tastung_passiv : 48|1@1+ (1.0,0.0) [0.0|1] ""  OTA_FC
 SG_ ESP_Tastung_passiv : 49|1@1+ (1.0,0.0) [0.0|1] ""  OTA_FC,ZR_High,ZR_LIMU,ZR_MIB_TOP_ab_Gen3
 SG_ ESP_Systemstatus : 50|1@1+ (1.0,0.0) [0.0|1] ""  OTA_FC
 SG_ ASR_Schalteingriff : 51|2@1+ (1.0,0.0) [0.0|3] ""  Vector__XXX
 SG_ ESP_QBit_v_Signal : 55|1@1+ (1.0,0.0) [0.0|1] ""  ZR_High,ZR_LIMU,ZR_MIB_TOP_ab_Gen3,ZR_Standard
 SG_ ABS_Bremsung : 56|1@1+ (1.0,0.0) [0.0|1] ""  OTA_FC,ZR_High,ZR_LIMU,ZR_MIB_TOP_ab_Gen3
 SG_ ASR_Anf : 57|1@1+ (1.0,0.0) [0.0|1] ""  ZR_High,ZR_MIB_TOP_ab_Gen3
 SG_ MSR_Anf : 58|1@1+ (1.0,0.0) [0.0|1] ""  OTA_FC,ZR_High
 SG_ EBV_Eingriff : 59|1@1+ (1.0,0.0) [0.0|1] ""  OTA_FC
 SG_ EDS_Eingriff : 60|1@1+ (1.0,0.0) [0.0|1] ""  OTA_FC
 SG_ ESP_Eingriff : 61|1@1+ (1.0,0.0) [0.0|1] ""  OTA_FC,ZR_High
 SG_ ESP_ASP : 62|1@1+ (1.0,0.0) [0.0|1] ""  ZR_High
 SG_ ESC_Neutralschaltung : 63|1@1+ (1.0,0.0) [0.0|1] ""  Vector__XXX

BO_ 239 ESP_22: 8 Gateway
 SG_ ESP_22_CRC : 0|8@1+ (1,0) [0|255] ""  Vector__XXX
 SG_ ESP_22_BZ : 8|4@1+ (1,0) [0|15] ""  Vector__XXX
 SG_ ESP_QBit_VL_Bremsmoment : 12|1@1+ (1.0,0.0) [0.0|1] ""  Vector__XXX
 SG_ ESP_QBit_VR_Bremsmoment : 13|1@1+ (1.0,0.0) [0.0|1] ""  Vector__XXX
 SG_ ESP_QBit_HL_Bremsmoment : 14|1@1+ (1.0,0.0) [0.0|1] ""  Vector__XXX
 SG_ ESP_QBit_HR_Bremsmoment : 15|1@1+ (1.0,0.0) [0.0|1] ""  Vector__XXX
 SG_ ESP_VL_Bremsmoment : 16|8@1+ (40,0) [0|10120] "Unit_NewtoMeter"  OTA_FC,ZR_MIB_TOP_ab_Gen3
 SG_ ESP_VR_Bremsmoment : 24|8@1+ (40,0) [0|10120] "Unit_NewtoMeter"  OTA_FC,ZR_MIB_TOP_ab_Gen3
 SG_ ESP_HL_Bremsmoment : 32|8@1+ (20,0) [0|5060] "Unit_NewtoMeter"  OTA_FC,ZR_MIB_TOP_ab_Gen3
 SG_ ESP_HR_Bremsmoment : 40|8@1+ (20,0) [0|5060] "Unit_NewtoMeter"  OTA_FC,ZR_MIB_TOP_ab_Gen3
 SG_ ESP_FZR_uebersteuern : 48|8@1+ (0.004,0) [0.000|1.000] ""  OTA_FC,ZR_High,ZR_LIMU,ZR_MIB_TOP_ab_Gen3
 SG_ ESP_FZR_untersteuern : 56|8@1+ (0.004,0) [0.000|1.000] ""  OTA_FC,ZR_High,ZR_LIMU,ZR_MIB_TOP_ab_Gen3

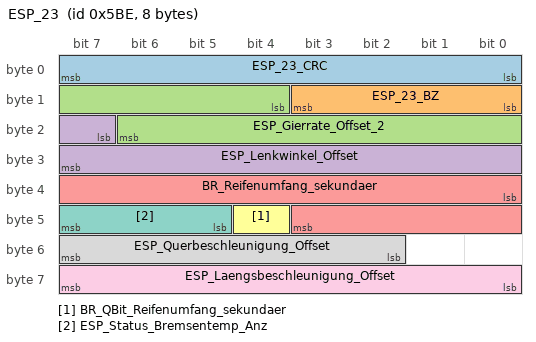
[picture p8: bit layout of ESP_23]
BO_ 1470 ESP_23: 8 Gateway
 SG_ ESP_23_CRC : 0|8@1+ (1,0) [0|255] ""  Vector__XXX
 SG_ ESP_23_BZ : 8|4@1+ (1,0) [0|15] ""  Vector__XXX
 SG_ ESP_Gierrate_Offset_2 : 12|11@1+ (0.01,-10.23) [-10.23|10.22] "Unit_DegreOfArcPerSecon"  Vector__XXX
 SG_ ESP_Lenkwinkel_Offset : 23|9@1+ (0.1,-25.5) [-25.5|25.4] "Unit_DegreOfArc"  Vector__XXX
 SG_ BR_Reifenumfang_sekundaer : 32|12@1+ (1,0) [0|4095] "Unit_MilliMeter"  Vector__XXX
 SG_ BR_QBit_Reifenumfang_sekundaer : 44|1@1+ (1.0,0.0) [0.0|1] ""  Vector__XXX
 SG_ ESP_Status_Bremsentemp_Anz : 45|3@1+ (1.0,0.0) [0.0|7] ""  ZR_High,ZR_LIMU,ZR_MIB_TOP_ab_Gen3
 SG_ ESP_Querbeschleunigung_Offset : 50|6@1+ (0.01,-0.3) [-0.30|0.31] "Unit_ForceOfGravi"  ZR_High
 SG_ ESP_Laengsbeschleunigung_Offset : 56|8@1+ (0.03125,-3.9375) [-3.93750|3.93750] "Unit_MeterPerSeconSquar"  ZR_High

BO_TX_BU_ 2617219604 :ZR_High,ZR_MIB_TOP_ab_Gen3,ZR_Standard;
BO_TX_BU_ 2617219605 :ZR_High,ZR_MIB_TOP_ab_Gen3,ZR_Standard;
BO_TX_BU_ 2549880610 :Gateway,Gateway_PAG;
BO_TX_BU_ 2550011682 :ZR_High,ZR_MIB_TOP_ab_Gen3;
BO_TX_BU_ 2549880611 :Gateway,Gateway_PAG;
BO_TX_BU_ 2550011683 :ZR_High,ZR_MIB_TOP_ab_Gen3;
BO_TX_BU_ 2549880473 :Gateway,Gateway_PAG;
BO_TX_BU_ 2550011545 :ZR_High,ZR_MIB_TOP_ab_Gen3;
BO_TX_BU_ 2549880474 :Gateway,Gateway_PAG;
BO_TX_BU_ 2550011546 :ZR_High,ZR_MIB_TOP_ab_Gen3;
BO_TX_BU_ 1714 :Gateway,Gateway_PAG;
BO_TX_BU_ 1520 :Gateway,Gateway_PAG;
BO_TX_BU_ 420 :Gateway,Gateway_PAG;
BO_TX_BU_ 496 :Gateway,Gateway_PAG;
BO_TX_BU_ 189 :Gateway,Gateway_PAG;
BO_TX_BU_ 2527679980 :Gateway,Gateway_PAG;
BO_TX_BU_ 996 :Gateway,Gateway_PAG;
BO_TX_BU_ 1603 :Gateway,Gateway_PAG;
BO_TX_BU_ 1622 :Gateway,Gateway_PAG;
BO_TX_BU_ 115 :Gateway,Gateway_PAG;
BO_TX_BU_ 260 :Gateway,Gateway_PAG;
BO_TX_BU_ 781 :Gateway,Gateway_PAG;
BO_TX_BU_ 259 :Gateway,Gateway_PAG;
BO_TX_BU_ 262 :Gateway,Gateway_PAG;
BO_TX_BU_ 914 :Gateway,Gateway_PAG;
BO_TX_BU_ 278 :Gateway,Gateway_PAG;
BO_TX_BU_ 418 :Gateway,Gateway_PAG;
BO_TX_BU_ 1629 :Gateway,Gateway_PAG;
BO_TX_BU_ 253 :Gateway,Gateway_PAG;
BO_TX_BU_ 239 :Gateway,Gateway_PAG;
BO_TX_BU_ 1470 :Gateway,Gateway_PAG;
CM_ BO_ 2549880610 "Drahtloses Bedienteil 1 für Multimediasystem Request Channel";
CM_ BO_ 2550011682 "Drahtloses Bedienteil 1 für Multimediasystem Response Channel";
CM_ BO_ 2549880611 "Drahtloses Bedienteil 2 für Multimediasystem Request Channel";
CM_ BO_ 2550011683 "Drahtloses Bedienteil 2 für Multimediasystem Response Channel";
CM_ BO_ 2549880473 "Anzeingeeinheit 3 für Multimediasystem Request Channel";
CM_ BO_ 2550011545 "Anzeingeeinheit 3 für Multimediasystem Response Channel";
CM_ BO_ 2549880474 "Anzeingeeinheit 4 für Multimediasystem Request Channel";
CM_ BO_ 2550011546 "Anzeingeeinheit 4 für Multimediasystem Response Channel";
CM_ BO_ 1520 "ab MQB nach abgestimmten FLH Dimmung";
CM_ BO_ 1603 "ab MQB mit 8 Byte";
CM_ BO_ 260 "ab MQB mit CRC-8";
CM_ BO_ 259 "MLBevo - CRC-Absicherung";
CM_ BO_ 418 "MLBevo verlangsamte 100ms-Botschaft";
CM_ BO_ 1629 "neu im MQB";
CM_ BO_ 253 "Neue Momente im MQB
Struktur ab MQB mit CRC8 entstanden aus ESP_01";
CM_ BO_ 1470 "MSS (AU724/5, LBxxx) Botschaft zur Offsetkompentation";

CM_ SG_ 2617219614 DEV_ZR_Pwm_Debug_1 "Powermanagement Debug 1 aktivieren";
CM_ SG_ 2617219614 DEV_ZR_Pwm_Debug_2 "Powermanagement Debug 1 aktivieren";
CM_ SG_ 2617219614 DEV_ZR_Pwm_Debug_3 "Powermanagement Debug 1 aktivieren";
CM_ SG_ 2617219614 DEV_ZR_Pwm_Debug_4 "Powermanagement Debug 1 aktivieren";

CM_ SG_ 2617219605 MMI_State "Powerstate des Zentralrechners. MMI_Off wird im Zustand dead mode gesendet.";
CM_ SG_ 2617219605 Routeg_aktiv "Routenführung aktiv
";
CM_ SG_ 2617219605 SI_MOST_Status "Das Signal gibt den Zustand des MOST wieder.";
CM_ SG_ 2617219605 Tel_aktiv "Aktives Telefonat oder mute pin aktiv
";
CM_ SG_ 2617219605 Tel_SIM_aktiv "SimKarte eingelegt

";
CM_ SG_ 2617219605 ZR_KL_30F "Gemessene Versorgungsspannung des Zentralrechners.
";
CM_ SG_ 2617219605 ZR_LastOn "LastOn state des Zentralrechners";
CM_ SG_ 2617219605 ZR_State_DU_1 "Kontrollbit für Display, Hintergrundbeleuchtung aus, Hintergrundbeleuchtung an, Energiesparmodus.
";
CM_ SG_ 2617219605 ZR_TempSens "Aktueller Temperaturwert des Zentralrechners";

CM_ SG_ 1714 DGN_Verlernzaehler "wrap around 254 --> 0";
CM_ SG_ 1714 KBI_Kilometerstand "Fehler wird ausgegeben, falls Kilometerstand nicht restaurierbar
";
CM_ SG_ 1714 UH_Minute "0x3C- 0x3f = Werte ungültig";
CM_ SG_ 1714 UH_Monat "0x0D, 0xF =  Werte ungültig
0x0E = Relatives Datum (nur VW)";
CM_ SG_ 1714 UH_Sekunde "0x3C- 0x3f = Werte ungültig";
CM_ SG_ 1714 UH_Stunde "0x18 - 0x1F = Werte ungültig";
CM_ SG_ 1714 UH_Tag "0x0: reserviert bei VW";
CM_ SG_ 1714 Uhrzeit_01_alt "
";

CM_ SG_ 1520 BCM1_Stellgroesse_Kl_58s "Rohwert Dimmpoti";
CM_ SG_ 1520 DI_Display_Nachtdesign "Für Displays sind oft  automatische Umschaltungen von Tag-/Nachtdesign vorgesehen.
Es gibt jedoch Zustände, an denen auch tagsüber das Abblendlicht eingeschaltet ist.
z.B. Dauerfahrlicht, Geschwindigkeitsabhängiges 'Licht-An-Bei-Autobahn', 'Regenlicht',";
CM_ SG_ 1520 DI_Fotosensor "Helligkeitswert Fotosensor
Für die Dimmung relevanter Wert zur Sensierung der Umgebungshelligkeit
Im Detail beschrieben im 'Funktionslastenheft Dimmung MQB'.";
CM_ SG_ 1520 DI_KL_58xd "Klemme 58xd Display- und Funktionsbeleuchtung
Mit der Klemme 58xd wird die Helligkeit der Display- und der Funktionsbeleuchtungen der Schalter gesteuert.
Im Detail beschrieben im 'Funktionslastenheft Dimmung MQB'.";
CM_ SG_ 1520 DI_KL_58xs "Suchbeleuchtung Schalter
EIN-AUS-Schaltalgorithmus der allgemeinen Schaltersuchbeleuchtung. 
Im Detail beschrieben im 'Funktionslastenheft Dimmung MQB'.
";
CM_ SG_ 1520 DI_KL_58xt "Timergesteuerte Suchbeleuchtung
Der EIN-AUS-Schaltalgorithmus für die vor- und nachlaufende Schaltersuchbeleuchtungen beim Ein- & Aussteigen; z.B.: Start/Stop-Taster.
Im Detail beschrieben im 'Funktionslastenheft Dimmung MQB'.";

CM_ SG_ 420 EA_01_BZ "EA Botschaftszähler
Botschaft asynchron geroutet. Zählerwert kann springen.";
CM_ SG_ 420 EA_01_CRC "Ab MQB und MLBevo:
'Berechnung siehe Lastenheft 'End-to-End Kommunikationsabsicherung''";
CM_ SG_ 420 EA_Anforderung_HMS "Emergency Assist Anforderung an HMS";
CM_ SG_ 420 EA_eCall_Anf "Emergency Assist Anforderung eCall";
CM_ SG_ 420 EA_Funktionsstatus "Emergency Assist Funktionsstatus";
CM_ SG_ 420 EA_Gurtstraffer_Anf "Emergency Assist Anforderung reversibler Gurtstraffer";
CM_ SG_ 420 EA_Parken_beibehalten_HMS "Anforderung um automatisches lösen der Parkbremse zu verhindern";
CM_ SG_ 420 EA_Sollbeschleunigung "Emergency Assist Beschleunigungsanforderung";
CM_ SG_ 420 EA_Warnruckprofil "Emergency Assist Anforderung an ESP, welcher Ruck verwendet werden soll.";

CM_ SG_ 496 ACF_Lampe_Hands_Off "Anzeige, ob der Fahrer die Hände am Lenkrad hat.";
CM_ SG_ 496 EA_02_BZ "Botschaftszähler
Botschaft asynchron geroutet. Zählerwert kann springen.";
CM_ SG_ 496 EA_02_CRC "Für MLB:
'Berechnung siehe Lastenheft 'Kommunikationsabsicherung für Flexray und CAN''

Ab MQB und MLBevo:
'Berechnung siehe Lastenheft 'End-to-End Kommunikationsabsicherung'

Endwerte siehe Begleitdokument 'S-PDU Kennungsfolge'";
CM_ SG_ 496 EA_Blinken "Emergency Assist Anforderung Blinker";
CM_ SG_ 496 EA_Bremslichtblinken "Die Funktion Emergency Alert fordert ein Blinken der Bremsleuchten an.";
CM_ SG_ 496 EA_Infotainment_Anf "Emergency Assist Anforderung Absenkung Infotainment-Funktionen";
CM_ SG_ 496 EA_Innenraumlicht_Anf "Anforderung Innenraumbeleuchtung durch den Emergency Assist";
CM_ SG_ 496 EA_Status_HMI "Anzeige Emergency Assist-Statusleuchte im Fahrerinformationsdisplay";
CM_ SG_ 496 EA_Texte "Anzeige der EA Texte";
CM_ SG_ 496 EA_Tueren_Anf "Emergency Assist Anforderung Türen entriegeln";
CM_ SG_ 496 STP_Primaeranz "Primäranzeige des Staupiloten";
CM_ SG_ 496 zFAS_Warnblinken "Anforderung Warnblinken durch zFAS Funktionen.";

CM_ SG_ 189 EBKV_01_BZ "Botschaftszaehler
Botschaft asynchron geroutet. Zählerwert kann springen.";
CM_ SG_ 189 EBKV_01_CRC "Für MLB:
'Berechnung siehe Lastenheft 'Kommunikationsabsicherung für FlexRay und CAN''

Ab MQB und MLBevo:
'Berechnung siehe Lastenheft 'End-to-End Kommunikationsabsicherung''

Endwerte siehe Begleitdokument 'S-PDU Kennungsfolgen'";
CM_ SG_ 189 EBKV_AktBr_aktiv "Fahreranteil an Aktivbremsung";
CM_ SG_ 189 EBKV_AktSp_Status "Status des SmAct";
CM_ SG_ 189 EBKV_AktSp_Volumenreserve "Volumenmenge, die vom SmAct noch aufgenommen werden kann";
CM_ SG_ 189 EBKV_extBr_Status "beschreibt den eBKV-seitigen Status zur Realisierung einer externen Druckanforderung, gestellt durch das ESC";
CM_ SG_ 189 EBKV_HZ_Bohrung_geschlossen "Zustand der HZ-Schnüffelbohrung:
0: Kolben hat Schnüffelbohrung nicht überfahren - offen
1: Kolben hat Schnüffelbohrung überfahren - geschlossen ";
CM_ SG_ 189 EBKV_Kraftblending_Reserve "Maximale Druckdifferenz, die durch Pedalkraftblending noch simuliert werden kann";
CM_ SG_ 189 EBKV_Stangenweg "Ausgangsstangenweg des eBKV";
CM_ SG_ 189 EBKV_Status_02 "eBKV Status Signal für 2 und 3 Box Systeme";
CM_ SG_ 189 SEKU_Anforderung_GE "Das Sekundärbremssystem realisiert mit dieser Schnittstelle ein Sichern des Fahrzeugs. Nach einer Bremsung in den Stillstand über die direkte Verzögerungsschnittstelle wird hierüber die Getriebesperre angefordert.";
CM_ SG_ 189 SEKU_Bremslicht "Die Bremslichtansteuerung durch das Sekundärbremssystem erfolgt, wenn bei Ausfall des Primärbremssystems die Ist_Verzögerung für eine Dauer von  (ca.100 ms) die bewertete Verzögerungsschwelle unterschreitet (Einschaltschwelle Bremslicht).";
CM_ SG_ 189 SEKU_Status "Das Sekundärbremssystem übermittelt seinen Systemstatus an die PiloFa-Funktion sowie das Primärbremssystem.";

CM_ SG_ 2527679980 bCall_active "1: Breakdown call is active
0: BreakdownCall is inactive";
CM_ SG_ 2527679980 eCall_Funktionsstatus "HMI-Aufruf im Kombi (Broadcast)
Fehlerfälle die im Kombi angezeigt werden können";
CM_ SG_ 2527679980 eCall_Funktionsstatus_02 "Erweiterung des Funktionsstatus für andere Funktionen
ACN aktiv, MEC aktiv
MEC = manual emergency call = maueller Notruf
ACN = automatic emergency call = automatischer Notruf";
CM_ SG_ 2527679980 eCall_Mute_Anf "Signalisiert die Aufforderungen alle Soundquellen im Fahrzeug während eines aktiven Notrufs zu muten";
CM_ SG_ 2527679980 eCall_Statuslicht_Farbe1 "Steuerung Statuslicht (Farbe1) für Funktionsrückmeldungen Emergency Call / SOS Hilferuf,
z.B. LED-Anzeige im Dachmodul.";
CM_ SG_ 2527679980 eCall_Statuslicht_Farbe2 "Steuerung Statuslicht (Farbe2) für Funktionsrückmeldungen Emergency Call / SOS Hilferuf,
z.B. LED-Anzeige im Dachmodul.";
CM_ SG_ 2527679980 eCall_Subscription "Anzeige 'Service Unsubscribed' im Kombi - Aktualisierte Namensgebung";

CM_ SG_ 996 EFF_Einsparhinweis "Anforderung der Anzeige von veschiedenen Life-Tipps";
CM_ SG_ 996 EFF_Verbrauch_STH "Verbrauchsanteil der Standheizung im Komfortverbrauch (siehe EFF_Verbraucher_Balken)";
CM_ SG_ 996 EFF_Verbraucher_Balken "Anzeige der Zusatzverbraucher (Anzeige 0-5,09 l/h in 0,01 l/h - Schritten) für BCmE (Bordcomputer mit Effizienzprogramm)";
CM_ SG_ 996 EFF_Verbraucher_Pos_1 "Name des Zusatzverbraucher an Listenposition '1' der Top-Verbraucher für die Balkenanzeige 'Zusatzverbraucher'";
CM_ SG_ 996 EFF_Verbraucher_Pos_2 "Name des Zusatzverbraucher an Listenposition '2' der Top-Verbraucher für die Balkenanzeige 'Zusatzverbraucher'";
CM_ SG_ 996 EFF_Verbraucher_Pos_3 "Name des Zusatzverbraucher an Listenposition '3' der Top-Verbraucher für die Balkenanzeige 'Zusatzverbraucher'";
CM_ SG_ 996 MKE_FAS "Sicherheitshinweis für FAS.";
CM_ SG_ 996 MKE_FAS_Fkt_Status "Statussignal für FAS-Profilemaster.";
CM_ SG_ 996 MKE_Fehlercode "Fehlercode der Funktion Müdigkeitserkennung.";
CM_ SG_ 996 MKE_Stufe "Das Signal bildet die Müdigkeitsstufe im Kombi ab:
0 - deaktiviert
1 - nicht_verfügbar
2 - Stufe_1
3 - Stufe_2
4 - Stufe_3
5 - Stufe_4
6 - reserviert
7 - reserviert";
CM_ SG_ 996 MKE_Texte "Systemhinweis und Sicherheitshinweis für Anzeige im Kombi";

CM_ SG_ 1603 KBI_Einheit_Datum "Anzeigevariante des Datums";
CM_ SG_ 1603 KBI_Einheit_Druck "Einheit des Druckes";
CM_ SG_ 1603 KBI_Einheit_Masse "Einheit der Masse (Verwendung z.B. ASTA)";
CM_ SG_ 1603 KBI_Einheit_Sprache "Siehe BAP-Datenfestlegung UnitMaster";
CM_ SG_ 1603 KBI_Einheit_Streckenanz "Einheit der Streckenanzeige";
CM_ SG_ 1603 KBI_Einheit_Temp "Einheit der Temperatur";
CM_ SG_ 1603 KBI_Einheit_Uhrzeit "Anzeigevariante der Uhrzeit";
CM_ SG_ 1603 KBI_Einheit_Verbrauch "Einheit der Verbrauchs";
CM_ SG_ 1603 KBI_Einheit_Verbrauch_elektr "Einheit elektrischer Verbrauch";
CM_ SG_ 1603 KBI_Einheit_Verbrauch_Gas "Unterscheidung zwischen M3/h und kg/h für Komfortverbrauchsberechnung.";
CM_ SG_ 1603 KBI_Einheit_Volumen "Einheit des Volumens";
CM_ SG_ 1603 KBI_MFA_v_Einheit_02 "Einheit der Geschwindigkeit, die vom Fahrer im Car-Menü gewählt wurde. Veränderliche Grösse, im Gegensatz zur Einheit des Tachokranzes.

Redundant in der Einheiten_01 Botschaft definiert, um Konsistenz zur BAP-Festlegung zu haben.";

CM_ SG_ 1622 ELV_01_BZ "4bit Botschaftszaehler, wird mit jeder Sendebotschaft inkrementiert";
CM_ SG_ 1622 ELV_01_CRC "Ab MQB und MLBevo:
'Berechnung siehe Lastenheft 'End-to-End Kommunikationsabsicherung''

Endwerte siehe Begleitdokument 'S-PDU Kennungsfolgen'";
CM_ SG_ 1622 ELV_01_Sendestatus "Zeigt an, ob die ELV für einen begrenzten Zeitraum mit verkürzter Zykluszeit (50ms) sendet. Das ist bis zur KL15ein notwendig, um eine Motorstartverzögerung zu vermeiden.";
CM_ SG_ 1622 ELV_Abbruch_Anf_Klemmenfreigabe "Klemmenanforderung des Kessy-SG wird von der ELV verworfen und muss vom Kessy zurückgenommen werden.";
CM_ SG_ 1622 ELV_Anf_Klemme_15 "Signal wird zur Plausibilisierung parrallel zum Klemmensignal auf dem CAN übertragen
Anforderung Klemme_15";
CM_ SG_ 1622 ELV_Anf_Klemme_50 "Signal wird zur Plausibilisierung parrallel zum Klemmensignal auf dem CAN übertragen
Anforderung Klemme_50";
CM_ SG_ 1622 ELV_Anf_Klemme_S "Signal wird zur Plausibilisierung parallel zum Klemmensignal auf dem CAN übertragen
Anforderung Klemme_S";
CM_ SG_ 1622 ELV_Anlernmodus "Im Anlernmodus (1) ist zum Einschalten der KLS u.KL15 keine Authentifizierung der WFS notwendig. KL50 ist nicht einschaltbar.
Auslieferungszustand ist (1)";
CM_ SG_ 1622 ELV_Entriegelt "ELV im Zustand entriegelt
";
CM_ SG_ 1622 ELV_Klemmenfreigabe "Freigabe/Quittierung der ELV für das Einschalten der Klemme 15 und Klemme S";
CM_ SG_ 1622 ELV_Lebenszustand "Auslieferungszustand ist (0)
Lebenszustand";
CM_ SG_ 1622 ELV_LED_Gelb "Warnlampe Gelb";
CM_ SG_ 1622 ELV_LED_Rot "Warnlampe Rot";
CM_ SG_ 1622 ELV_P_verriegelt "Position P-verriegelt vom Gangwahlhebel";
CM_ SG_ 1622 ELV_Txt_Bremse "Text: 'Bremspedal betätigen!'";
CM_ SG_ 1622 ELV_Txt_Defekt "Text: 'Lenkungsverriegelung defekt!'";
CM_ SG_ 1622 ELV_Txt_Kupplung "Text: 'Kupplungspedal betätigen!'";
CM_ SG_ 1622 ELV_Txt_Lkg_Bewegen "Text: 'Lenkrad bewegen!'";
CM_ SG_ 1622 ELV_Txt_P_Gang "Text: 'Wählhebel in Position P bringen!'";
CM_ SG_ 1622 ELV_Txt_Panikabschaltung "Text: 'Notabschaltung''";
CM_ SG_ 1622 ELV_Txt_PN_Gang "Text: 'Wählhebel in Position P/N bringen!'";
CM_ SG_ 1622 ELV_Txt_Werkstatt "Text: 'Lenkungsverriegelung! Werkstatt!'";
CM_ SG_ 1622 ELV_Verriegelt "ELV im Zustand verriegelt
";
CM_ SG_ 1622 ELV_ZAT_betaetigt "Zündanlass-Taster (ZAT) betätigt";

CM_ SG_ 115 EM1_HYB_12_BZ "Botschaft asynchron geroutet. Zählerwert kann springen.";
CM_ SG_ 115 EM1_HYB_12_CRC "Für MLB:
'Berechnung siehe Lastenheft 'Kommunikationsabsicherung für FlexRay und CAN''

Ab MQB und MLBevo:
'Berechnung siehe Lastenheft 'End-to-End Kommunikationsabsicherung''

Endwerte siehe Begleitdokument 'S-PDU Kennungsfolgen'";
CM_ SG_ 115 EM1_IstDrehzahl "Momentanwert: E-Maschinen Drehzahl";
CM_ SG_ 115 EM1_IstDrehzahl_alt "Momentanwert: E-Maschinen Drehzahl vor 2,5ms zur Aussetzerdiagnose";
CM_ SG_ 115 EM1_IstMoment "Momentanwert: E-Maschinen Moment";
CM_ SG_ 115 EM1_MaxZul_Drehzahl "EM1_MaxZul_Drehzahl stellt die maximale Drehzahlgrenze für LE bzw. EM dar die im Freilauf zulässig ist. Für Drehzahlen größer dieser Grenze wird die LE zum Komponentenschutz unabhängig von der Kommandierung in den AKS umschalten.";

CM_ SG_ 260 EPB_01_BZ "Botschaft asynchron geroutet. Zählerwert kann springen.";
CM_ SG_ 260 EPB_01_CRC "Für MLB:
'Berechnung siehe Lastenheft 'Kommunikationsabsicherung für FlexRay und CAN''

Ab MQB und MLBevo:
'Berechnung siehe Lastenheft 'End-to-End Kommunikationsabsicherung''

Endwerte siehe Begleitdokument 'S-PDU Kennungsfolgen'";
CM_ SG_ 260 EPB_DAA_Randbed_erf "Die Randbedingungen zum automatischen Öffnen der EPB (Funktion DAA) sind erfüllt und ein Betätigen des Fahrpedals führt zum Öffnen der EPB.";
CM_ SG_ 260 EPB_Fehlerstatus_02 "Anpassung der Texte an die  aktuellen Zustände für weitergehende Funktionen (Stillstandsmanager)";
CM_ SG_ 260 EPB_Freig_Verzoeg_Anf "Verzögerungsanforderung	";
CM_ SG_ 260 EPB_Pedalweg_Kuppl "Signal entspricht Tastverhältnis des PWM. Gesamtweg Kupplungspedal 10% bis 90%, damit zu erwartende Werte 25 bis 225. 25 bei Kupplungspedal nicht getreten, 225 bei Kupplungspedal voll durchgetreten.
2% Toleranz wird im Wertebereich ermöglicht (8%-92%).
";
CM_ SG_ 260 EPB_Schalterposition "Spiegelt die Schalterstellung wieder.

0x3 = Schalterfehler ";
CM_ SG_ 260 EPB_Spannkraft "Erzeugte Spannkraft. Bezieht sich auf die Aktuatoren.

MQB: Spannkraftwerte entsprechen nicht den tatsächlichen Spannkräften. Genauere Informationen bitte in der Fachabteilung erfragen! ";
CM_ SG_ 260 EPB_Status_02 "Erweiterung der Zustände um ein genaueres Bild des aktuellen Zustandes zu erhalten für weitergehende Funktionen ( Stillstandsmanager)
";
CM_ SG_ 260 EPB_Verzoeg_Anf "Steuerungsanforderung an andere Systeme (z.B. ESP), um während der Fahrt, durch den Handbremsschalter ausgelöst, zu bremsen (ECD-Funktion)";

CM_ SG_ 781 EPB_Akustik "Bit wird gesetzt, wenn bei v > 0 eine Fahreran-forderung schließen vorhanden ist (ECD angefordert). PQ46-Kombi sendet Warnton (600Hz) solange dieses Bit gesetzt ist.
Anzeige eines Warntextes
";
CM_ SG_ 781 EPB_Autoholdlampe "Autoholdlampe im Kombi, grünes P
";
CM_ SG_ 781 EPB_Bremsbelag_Warn "Mindestens ein Bremsbelag an der Hinterachse am Fahrzeug ist unter Minimum";
CM_ SG_ 781 EPB_Fehlerlampe_BKL "Die BKL dient als rote Fehlerlampe für die EPB. Sie wird vom EPB-SG aktiv ausgeschaltet.";
CM_ SG_ 781 EPB_Fehlerlampe_Gelb "Fehlerlampe für nicht liegenbleiberreleavante Fehler";
CM_ SG_ 781 EPB_Fehlermeldungen "Über das Signal werden bestimmte Fehlertexte und -lampen im Kombi angefordert.";
CM_ SG_ 781 EPB_Funktionslampe "Bit wird nur gesetzt, wenn volle Spannkraft auf beiden Seiten erreicht. PQ46: Bit wird gesetzt, wenn BKL direkt vom EPB-SG als Funktionslampe angesteuert wird.

Bei Audi: Rote Lampe (rotes P) im Kombiinstrument
";
CM_ SG_ 781 EPB_Texte "EPB-Texte für Kombi
9 bei Audi aktuell nicht bedient.
10 bei Audi hinzugefügt für RSe
11 bei PAG Duo Servo Parkbremse aktuell nicht bedient 
12 bei PAG Duo Servo Parkbremse aktuell nicht bedient 
13 nur bei ParkPilot/IPA verwendet";

CM_ SG_ 259 ESP_03_BZ "Botschaft asynchron geroutet. Zählerwert kann springen.";
CM_ SG_ 259 ESP_03_CRC "Ab MQB und MLBevo:
'Berechnung siehe Lastenheft 'End-to-End Kommunikationsabsicherung''

Endwerte siehe Begleitdokument 'S-PDU Kennungsfolgen'";
CM_ SG_ 259 ESP_HL_FR "Fahrtrichtungserkennung Rad Hinten Links
";
CM_ SG_ 259 ESP_HL_Radgeschw "Radgeschwindigkeit hinten links";
CM_ SG_ 259 ESP_HR_FR "Fahrtrichtungserkennung Rad Hinten Rechts
";
CM_ SG_ 259 ESP_HR_Radgeschw "Radgeschwindigkeit hinten rechts";
CM_ SG_ 259 ESP_VL_FR "Fahrtrichtungserkennung Rad Vorne Links
";
CM_ SG_ 259 ESP_VL_Radgeschw "Radgeschwindigkeit vorne links";
CM_ SG_ 259 ESP_VR_FR "Fahrtrichtungserkennung Rad Vorne Rechts

";
CM_ SG_ 259 ESP_VR_Radgeschw "Radgeschwindigkeit vorne rechts";

CM_ SG_ 262 ECD_Fehler "ESP kann die Verzögerungsregelung/Bremsenregelung aufgrund eines internen Fehlers nicht ausführen, mit Fehlereintrag im ESP.
";
CM_ SG_ 262 ECD_nicht_verfuegbar "ESP kann die Verzögerungsregelung/Bremsenregelung temporär nicht ausführen (z.B. Netzwerkmanagement-Betriebe - KL15 Aus; v<18km/h; ESP in Diagnose, ...), ohne Fehlereintrag im ESP.

";
CM_ SG_ 262 ESC_Bremslicht "Die Bremslichtansteuerung erfolgt, wenn die Ist_Verzögerung für eine Dauer von  (ca.100 ms) die bewertete Verzögerungsschwelle unterschreitet (Einschaltschwelle Bremslicht),  Bremsdruck vorhanden aufgrund ECD , EMP, HMS oder HDC. Bei AWV2 wird von Beginn ";
CM_ SG_ 262 ESP_05_BZ "Botschaft asynchron geroutet. Zählerwert kann springen.";
CM_ SG_ 262 ESP_05_CRC "Für MLB:
'Berechnung siehe Lastenheft 'Kommunikationsabsicherung für FlexRay und CAN''

Ab MQB und MLBevo:
'Berechnung siehe Lastenheft 'End-to-End Kommunikationsabsicherung''

Endwerte siehe Begleitdokument 'S-PDU Kennungsfolgen'";
CM_ SG_ 262 ESP_Anforderung_EPB "ESP fordert von der EPB Öffnen bzw. Schliessen an. Notwendig wegen Autohold-Funktion.";
CM_ SG_ 262 ESP_Autohold_aktiv "Rückmeldung an EPB, dass Autohold aktiv ist.";
CM_ SG_ 262 ESP_Autohold_Standby "Rückmeldung an EPB, dass der Fahrer die Funktion Autohold mindestens einmal angefordert hat. Im Fall eines ESP-Ausfalles oder einer Übernahmeaufforderung erfolgt die EPB-Zuschaltung nur nach Setzen dieses Bits. Bit wird gesetzt nach Betätigung des Autohol";
CM_ SG_ 262 ESP_BKV_Unterdruck "Der maximale Wert wird auf 1012 mbar begrenzt.
Dieses Signal wird im AU64x nicht unterstützt.

Hinweis: Auch bei nicht verbautem BKV-Unterdrucksensor könnte während der Initialisierung der Initialisierungswert gesendet werden.";
CM_ SG_ 262 ESP_Bremsdruck "Rohwert des Bremsdrucks
Für Fahrzeuge mit elektrischem Bremskraftverstärker gilt: Aus dem Signal ESP_Bremsdruck lässt sich kein Fahrerbremswunsch ableiten. Das Signal bildet lediglich den hydraulischen Anteil der Fahrzeugverzögerung ab. Der Rohwert des S";
CM_ SG_ 262 ESP_Eingr_HL "wird von QSP und Neigungsanzeige verwendet

Flag wird vom ESP gesetzt, sobald aufgrund eines ESP-Eingriffs am Rad aktiv Druck aufgebaut wird.
Frühestens mit öffnen des Ventils und spätestens bei einem Bremsmoment von 100Nm. Flag bleibt solange gesetzt ";
CM_ SG_ 262 ESP_Eingr_HR "wird von QSP und Neigungsanzeige verwendet

Flag wird vom ESP gesetzt, sobald aufgrund eines ESP-Eingriffs am Rad aktiv Druck aufgebaut wird.
Frühestens mit öffnen des Ventils und spätestens bei einem Bremsmoment von 100Nm. Flag bleibt solange gesetzt ";
CM_ SG_ 262 ESP_Eingr_VL "wird von QSP und Neigungsanzeige verwendet

Flag wird vom ESP gesetzt, sobald aufgrund eines ESP-Eingriffs am Rad aktiv Druck aufgebaut wird.
Frühestens mit öffnen des Ventils und spätestens bei einem Bremsmoment von 100Nm. Flag bleibt solange gesetzt ";
CM_ SG_ 262 ESP_Eingr_VR "wird von QSP und Neigungsanzeige verwendet

Flag wird vom ESP gesetzt, sobald aufgrund eines ESP-Eingriffs am Rad aktiv Druck aufgebaut wird.
Frühestens mit öffnen des Ventils und spätestens bei einem Bremsmoment von 100Nm. Flag bleibt solange gesetzt ";
CM_ SG_ 262 ESP_Fahrer_bremst "Bit wird gesetzt beim Überschreiten der Bremsdruckschwelle

Weiterführende Informationen im Lastenheft spezifiziert und in der entsprechenden Fachabteilung zu erfragen.
";
CM_ SG_ 262 ESP_FStatus_Anfahrhilfe "Bei gesetztem Bit steht die Funktion Berganfahrassistent (Hillhold) nicht zur Verfügung";
CM_ SG_ 262 ESP_HBA_aktiv "Verwendung/Bedienung ab D4
Signal gibt an, ob der hydraulische Bremsassistent im Regler aktiviert wurde

Im MQB wird das Signal nicht unterstützt!

";
CM_ SG_ 262 ESP_HDC_aktiv "MQB und AU57x Allroad: Mit diesem Statusbit wird eine gerade aktive Regelung des Bergabfahrassistenten (Hill Descent Control) signalisiert.";
CM_ SG_ 262 ESP_HDC_Standby "Verwendung/Bedienung im MQB und AU57x Allroad:
Flag wird vom ESP gesetzt, wenn über den HDC-Taster die HDC-Funktion eingeschalten wurde";
CM_ SG_ 262 ESP_Lenkeingriff_ADS "Im Falle eines fahrzeugstabilisierenden Lenkeingriffs des ADS-Systems soll ACC/GRA deaktiviert werden.

Im MQB wird dieses Signal nicht unterstützt!";
CM_ SG_ 262 ESP_Prefill_ausgeloest "MLB: Verwendung/Bedienung ab D4
zeigt, ob die Funktion Prefill (aufgrund Fahrpedalgradient) ausgelöst wird; zeigt keinen Funktionszustand bezüglich Fehlerstilllegung

MQB: Wird gesetzt bei jeder Art von aktivem Prefill";
CM_ SG_ 262 ESP_QBit_Bremsdruck "QBit des Bremsdrucks. Gesetzt bei Ersatzwert, Init oder Fehler.";
CM_ SG_ 262 ESP_QBit_Fahrer_bremst "Gültigkeit der Bremsdruckschwelleninformation des Signals ESP_Fahrer_bremst vom ESP SG
0x1 = Druckschwelleninformation kann noch nicht oder aufgrund eines Fehlers nicht ausgegeben werden
";
CM_ SG_ 262 ESP_Rueckwaertsfahrt_erkannt "nur bei AU57x und AU416 sowie Audi B8PA
Info, ob Rückwärtsfahrt über internen Algorithmus sicher erkannt

Im MQB wird das Signal nicht unterstützt!";
CM_ SG_ 262 ESP_Schwelle_Unterdruck "Verwendung im MQB für HBV-Projekte oder wenn für St/St ein Unterdrucksensor verbaut ist";
CM_ SG_ 262 ESP_StartStopp_Info "Stopp-Freigabe und Start-Anforderung an den Start-Stopp-Koordinator";
CM_ SG_ 262 ESP_Status_Anfahrhilfe "Funktionsstatus des Berganfahrassistenten
MQB: Auswertung im Getriebe zwecks Standabkopplung";
CM_ SG_ 262 ESP_Status_Bremsdruck "MLB: Bei gesetztem Bit liegt p > ca. 2 bar an, hervorgerufen durch Fahrer, ASR, FZR, ECD, Bremsregler ... bei Abfall des Bits ist p < X bar, bei aktivem ECD-Eingriff Ende des Eingriffs 

Weiterführende Informationen im Lastenheft spezifiziert und in der";
CM_ SG_ 262 ESP_Status_Bremsentemp "ECD-Bremsscheibentemperaturmodell. Rückmeldung für Sender einer ECD Verzögerungsanforderung, ohne Fehlereintrag im ESP";
CM_ SG_ 262 ESP_Verz_EPB_aktiv "Bei gesetztem Bit wird die Verzögerungsanforderung von EPB umgesetzt.";
CM_ SG_ 262 ESP_Verzoeg_EPB_verf "Bei gesetztem Bit ist der Verzögerungsregeler für EPB verfügbar.";

CM_ SG_ 914 ESC_cAQP_Trigger "Trigger zur statistischen Auswertung durch die Connected Car Funktion Aquaplaning Praediktion (AQP).

Ansprechpartner: Timo Maise (PAG- EEC2)";
CM_ SG_ 914 ESP_07_BZ "Botschaft asynchron geroutet. Zählerwert kann springen.";
CM_ SG_ 914 ESP_07_CRC "Für MLB:
'Berechnung siehe Lastenheft 'Kommunikationsabsicherung für FlexRay und CAN''

Ab MQB und MLBevo:
'Berechnung siehe Lastenheft 'End-to-End Kommunikationsabsicherung''

Endwerte siehe Begleitdokument 'S-PDU Kennungsfolgen'";
CM_ SG_ 914 ESP_Allrad_Antrieb "Im MQB wird das Signal nicht unterstützt!";
CM_ SG_ 914 ESP_Codierung_ADS "ESP gibt für Empfänger im Fahrzeug aus, ob ADS verbaut/nicht verbaut ist.

Im MQB wird das Signal nicht unterstützt!
";
CM_ SG_ 914 ESP_MKB_ausloesbar "ESP hat Funktion Multi-Kollisions-Bremsung freigeschaltet";
CM_ SG_ 914 ESP_nachtr_Stopp_Anf "Dieses Signal dient dem Motor als Trigger, dass ein nachträglicher Motorstopp eingeleitet werden kann, wenn es die Bedingungen des StSt Koordinators dies zulassen. ";
CM_ SG_ 914 ESP_OBD_Status "Dieses Bit steuert die MIL-Lampe an (Motorsteuergerät reicht diese Info an Kombi weiter).";
CM_ SG_ 914 ESP_Offroad_Modus "Nur VW526: Bei Offroad-Fahrzeugen kann über einen Schalter ein Offroadmodus gewählt werden, dieser wird hier angezeigt. Bei Offroad Plus- Fahrzeugen wird hier der Offroadmodus indirekt durch das Verteilergetriebe vorgegeben (ALR_Offroad = 1) und eingespie";
CM_ SG_ 914 ESP_Qualifizierung_Antriebsart "Signal for Bentley BY83x: ESP_wheel_drive_selector

Bit qualifiziert für neue Projekte (ab D4 ff.) das Signal 'ESP_Quattro_Antrieb', d.h. ist 'ESP_Qualifizierung_Antriebsart'
auf 0x1 gesetzt, ändert sich die bisherige Bedeutung des Signals 'ESP_Quattro";
CM_ SG_ 914 ESP_Rollenmodus_Deaktivieren "Zwang zum Abbruch des Rollenmodus mit anschließender ESP-Vollfunktion.
MQB: Zwang zum Abbruch des Rollenmodus in allen Funktionsteilnehmern (Empfänger) mit anschließender ESP-Vollfunktion (Sender).
Signal wird vom ESP dauerhaft mit gültigen Werten bedat";
CM_ SG_ 914 ESP_RTA_HL "Physikalischer Wertebereich +/-5%. Der Reifentoleranzabgleich bezieht sich auf das linke Vorderrad.

physikalischer Wert = ( (Hex-Wert - 0x7F) / 2048 )*100%

Im MQB wird das Signal nicht unterstützt!";
CM_ SG_ 914 ESP_RTA_HR "Physikalischer Wertebereich +/-5%. Der Reifentoleranzabgleich bezieht sich auf das linke Vorderrad.

physikalischer Wert = ( (Hex-Wert - 0x7F) / 2048 )*100%

Im MQB wird das Signal nicht unterstützt!";
CM_ SG_ 914 ESP_RTA_VR "Physikalischer Wertebereich +/-5%. Der Reifentoleranzabgleich bezieht sich auf das linke Vorderrad.

physikalischer Wert = ( (Hex-Wert - 0x7F) / 2048 )*100%

Im MQB wird das Signal nicht unterstützt!";
CM_ SG_ 914 ESP_Stat_FallBack_eBKV "Das Signal zeigt dem eBKV an, ob seine Rückfallebene im ESP verfügbar ist.";
CM_ SG_ 914 OBD_Fehler_Radsensor_HL "Für Motor-SG (gesetzliche Vorgabe)";
CM_ SG_ 914 OBD_Fehler_Radsensor_HR "Für Motor-SG (gesetzliche Vorgabe)";
CM_ SG_ 914 OBD_Fehler_Radsensor_VL "Für Motor-SG (gesetzliche Vorgabe)";
CM_ SG_ 914 OBD_Fehler_Radsensor_VR "Für Motor-SG (gesetzliche Vorgabe)";

CM_ SG_ 278 ESP_10_BZ "Botschaftszähler

Wird im Projekt D4 und D4Hybrid nicht verwendet!  Wird im D4 PA verwendet
Botschaft asynchron geroutet. Zählerwert kann springen.";
CM_ SG_ 278 ESP_10_CRC "Für MLB:
'Berechnung siehe Lastenheft 'Kommunikationsabsicherung für FlexRay und CAN''

Ab MQB und MLBevo:
'Berechnung siehe Lastenheft 'End-to-End Kommunikationsabsicherung''

Endwerte siehe Begleitdokument 'S-PDU Kennungsfolgen'

Wird im Projekt";
CM_ SG_ 278 ESP_HL_Fahrtrichtung "Drehrichtung Rad HL

Weiterführende Informationen im Lastenheft spezifiziert und in der entsprechenden Fachabteilung zu erfragen.

Wird im Projekt D4 und D4Hybrid nicht verwendet!  Wird im D4 PA verwendet";
CM_ SG_ 278 ESP_HR_Fahrtrichtung "Drehrichtung Rad HR

Weiterführende Informationen im Lastenheft spezifiziert und in der entsprechenden Fachabteilung zu erfragen.

Wird im Projekt D4 und D4Hybrid nicht verwendet!  Wird im D4 PA verwendet";
CM_ SG_ 278 ESP_QBit_Wegimpuls_HL "Qualifizierungsbit Wegimpulszähler HL

Wird im Projekt D4 und D4Hybrid nicht verwendet!  Wird im D4 PA verwendet";
CM_ SG_ 278 ESP_QBit_Wegimpuls_HR "Qualifizierungsbit Wegimpulszähler HR

Wird im Projekt D4 und D4Hybrid nicht verwendet!  Wird im D4 PA verwendet";
CM_ SG_ 278 ESP_QBit_Wegimpuls_VL "Qualifizierungsbit Wegimpulszähler VL

Wird im Projekt D4 und D4Hybrid nicht verwendet!  Wird im D4 PA verwendet";
CM_ SG_ 278 ESP_QBit_Wegimpuls_VR "Qualifizierungsbit Wegimpulszähler VR

Wird im Projekt D4 und D4Hybrid nicht verwendet!  Wird im D4 PA verwendet";
CM_ SG_ 278 ESP_VL_Fahrtrichtung "Drehrichtung Rad VL

Weiterführende Informationen im Lastenheft spezifiziert und in der entsprechenden Fachabteilung zu erfragen.

Wird im Projekt D4 und D4Hybrid nicht verwendet!  Wird im D4 PA verwendet";
CM_ SG_ 278 ESP_VR_Fahrtrichtung "Drehrichtung Rad VR

Weiterführende Informationen im Lastenheft spezifiziert und in der entsprechenden Fachabteilung zu erfragen.

Wird im Projekt D4 und D4Hybrid nicht verwendet!  Wird im D4 PA verwendet";
CM_ SG_ 278 ESP_Wegimpuls_HL "Wegimpulszähler HL.
Anzahl der Wegimpulse Hinterrad links (steigende und fallende Flanke)
Zähler läuft grundsätzlich vorwärts, auch bei Rückwärtsfahrt.
Nach SG-Reset ist immer, ohne Ausnahme, 1mal der Init Wert 1021 zu senden.

Wird im Projekt D4 und";
CM_ SG_ 278 ESP_Wegimpuls_HR "Wegimpulszähler HR.
Anzahl der Wegimpulse Hinterrad rechts (steigende und fallende Flanke)
Zähler läuft grundsätzlich vorwärts, auch bei Rückwärtsfahrt.
Nach SG-Reset ist immer, ohne Ausnahme, 1mal der Init Wert 1021 zu senden.

Wird im Projekt D4 un";
CM_ SG_ 278 ESP_Wegimpuls_VL "Wegimpulszähler VL.
Anzahl der Wegimpulse Vorderrad links (steigende und fallende Flanke)
Zähler läuft grundsätzlich vorwärts, auch bei Rückwärtsfahrt.
Nach SG-Reset ist immer, ohne Ausnahme, 1mal der Init Wert 1021 zu senden.

Wird im Projekt D4 und";
CM_ SG_ 278 ESP_Wegimpuls_VR "Wegimpulszähler VR.
Anzahl der Wegimpulse Vorderrad rechts (steigende und fallende Flanke)
Zähler läuft grundsätzlich vorwärts, auch bei Rückwärtsfahrt.
Nach SG-Reset ist immer, ohne Ausnahme, 1mal der Init Wert 1021 zu senden.

Wird im Projekt D4 un";

CM_ SG_ 418 ESP_15_BZ "Botschaftszähler
Botschaft asynchron geroutet. Zählerwert kann springen.";
CM_ SG_ 418 ESP_15_CRC "Für MLB:
'Berechnung siehe Lastenheft 'Kommunikationsabsicherung für FlexRay und CAN''

Ab MQB und MLBevo:
'Berechnung siehe Lastenheft 'End-to-End Kommunikationsabsicherung''

Endwerte siehe Begleitdokument 'S-PDU Kennungsfolgen'

Wird im Projekt";
CM_ SG_ 418 ESP_Haltemoment "Zeigt in Abhängigkeit von ESP_Index_Haltemoment das notwendige Summen-Radmoment an (bergab: Bremsmoment; bergauf: Antriebsmoment), das mindestens notwendig ist um das Fahrzeug an der aktuellen Neigung zu halten.";
CM_ SG_ 418 ESP_Index_Haltemoment "Zeigt an, ob das Summen-Radmoment von ESP_Haltemoment ein Bremsmoment (bergab) oder ein Antriebsmoment (bergauf) darstellt.";
CM_ SG_ 418 HMS_aktives_System "Zeigt an, von welchem System die Anforderung gerade umgesetzt wird.";
CM_ SG_ 418 HMS_Anforderung_GE "Fordert vom Getriebe bestimmte Schaltstellungen an.";
CM_ SG_ 418 HMS_Fehlerstatus "Zeigt den Fehlerstatus des Haltemanagementsystems HMS an.
Details zu den Werten 3/4:
3=Systemeinschränkung, Parken EPB oder GSG nicht möglich
4=Systemstörung bzw. Parken EPB und GSG nicht möglich  ";
CM_ SG_ 418 HMS_halten_nicht_verfuegbar "Rueckmeldung HMS-Teilfunktion 'Halten' nicht verfuegbar.";
CM_ SG_ 418 HMS_Konsistenz_ACC "Zeigt an, ob die Kommunikation und die Anforderungen plausibel sind.";
CM_ SG_ 418 HMS_Konsistenz_GE "Zeigt an, ob die Kommunikation und die Anforderungen plausibel sind.";
CM_ SG_ 418 HMS_Konsistenz_HVLM "Zeigt an, ob die Kommunikation und die Anforderungen plausibel sind.";
CM_ SG_ 418 HMS_Konsistenz_IPA "Zeigt an, ob die Kommunikation und die Anforderungen plausibel sind.
";
CM_ SG_ 418 HMS_Konsistenz_MO "Zeigt an, ob die Kommunikation und die Anforderungen plausibel sind.";
CM_ SG_ 418 HMS_Konsistenz_STA "Zeigt an, ob die Kommunikation und die Anforderungen plausibel sind.";
CM_ SG_ 418 HMS_Notstopp_Status "Statusinformation des Notstoppsystems an die beteiligten Systeme.";
CM_ SG_ 418 HMS_P_beibehalten_GE "Fordert das Getriebe auf in Stellung 'P' zu bleiben.";
CM_ SG_ 418 HMS_parken_nicht_verfuegbar "Rueckmeldung HMS-Teilfunktionen 'Parken' nicht verfuegbar.";
CM_ SG_ 418 HMS_Stillstand "Das Signal zeigt, basierend auf den vier ESP-Raddrehzahlinformatioen, gefiltert und/oder entprellt mehrstufig den Fahrzeuggeschwindigkeitszustand an.";
CM_ SG_ 418 HMS_Systemstatus "Zeigt den aktuellen Systemstatus des HMS an.";
CM_ SG_ 418 NL_PRIM_STP_01_Status "Das Primär- Bremsregelsystem übermittelt seinen Systemstatus an zFAS und Sekundär- Bremsregelsystem. 

Der Staupilot ermittelt sich über den Status des Primär-und des Sekundärbremsregelsystems den Gesamtzustand des Notlaufreglers.";
CM_ SG_ 418 VMM_Warnblinken "Über dieses Signal wird ein Warnblinken von Funktionen des VMM (VehicleMotionManagers) angefordert.";
CM_ SG_ 418 VZM_Status "Zeigt die Verfuegbarkeit und den Zustand der VZM Funktionen im ESC an";

CM_ SG_ 1629 BR_QBit_Reifenumfang "Gesetzt bei Ersatzwert, Init oder Fehler.";
CM_ SG_ 1629 BR_Reifenumfang "Mittlerer Radumfang gerechnet in Millimeter.
Von der Bremse plausibilisierter Wert (Kopie von KBI_Reifenumfang wenn dieser plausibel) oder Ersatzwert aus Bremse wenn KBI_Reifenumfang unplausibel. Bitte das QBit beachten!

Im MEB wird das Signal KBI_Rei";
CM_ SG_ 1629 BR_Systemart "Identifikation des verbauten Bremssystems

Dient dem Kombi zur Plausibilisierung";
CM_ SG_ 1629 ESP_20_BZ "Botschaft asynchron geroutet. Zählerwert kann springen.";
CM_ SG_ 1629 ESP_20_CRC "Für MLB:
'Berechnung siehe Lastenheft 'Kommunikationsabsicherung für FlexRay und CAN''

Ab MQB und MLBevo:
'Berechnung siehe Lastenheft 'End-to-End Kommunikationsabsicherung''

Endwerte siehe Begleitdokument 'S-PDU Kennungsfolgen'";
CM_ SG_ 1629 ESP_Charisma_FahrPr "MLBevo: Aktuelles Fahrprogramm des Charisma-Teilnehmers (siehe Systemlastenheft Drive Select)
MQB: Istwert der Kennlinie (siehe Systemlastenheft MQB FPA)";
CM_ SG_ 1629 ESP_Charisma_Status "Systemstatus des Charismateilnehmers

Wert 0x3 ist nur für Fahrzeuge ab MQB relevant";
CM_ SG_ 1629 ESP_Dachrelingsensor "Erkennung auf Verbau des Dachrelingsensors und Dachquerträger.";
CM_ SG_ 1629 ESP_SpannungsAnf_02 "Forderung des ESP-SG's zur Spannungsanhebung.";
CM_ SG_ 1629 ESP_Stoppverbot_Anz_01 "Dieses Signal gibt die detaillierte Begründung für ein Stoppverbot vom Bremsensteuergerät an.";
CM_ SG_ 1629 ESP_Stoppverbot_Anz_02 "Dieses Signal gibt die detaillierte Begründung für ein Stoppverbot vom Bremsensteuergerät an.";
CM_ SG_ 1629 ESP_Stoppverbot_Anz_03 "Dieses Signal gibt die detaillierte Begründung für ein Stoppverbot vom Bremsensteuergerät an.";
CM_ SG_ 1629 ESP_Stoppverbot_Anz_04 "Dieses Signal gibt die detaillierte Begründung für ein Stoppverbot vom Bremsensteuergerät an.";
CM_ SG_ 1629 ESP_Stoppverbot_Anz_05 "Dieses Signal gibt die detaillierte Begründung für ein Stoppverbot vom Bremsensteuergerät an.";
CM_ SG_ 1629 ESP_Stoppverbot_Anz_06 "Dieses Signal gibt die detaillierte Begründung für ein Stoppverbot vom Bremsensteuergerät an.";
CM_ SG_ 1629 ESP_Stoppverbot_Anz_07 "Dieses Signal gibt die detaillierte Begründung für ein Stoppverbot vom Bremsensteuergerät an.";
CM_ SG_ 1629 ESP_Stoppverbot_Anz_08 "Dieses Signal gibt die detaillierte Begründung für ein Stoppverbot vom Bremsensteuergerät an.";
CM_ SG_ 1629 ESP_Stoppverbot_Anz_Std "Dieses Signal gibt die detaillierte Begründung für ein Stoppverbot vom Bremsensteuergerät an.";
CM_ SG_ 1629 ESP_Wiederstart_Anz_01 "Dieses Signal gibt die detaillierte Begründung für einen Wiederstart vom Bremsensteuergerät an. ";
CM_ SG_ 1629 ESP_Wiederstart_Anz_02 "Dieses Signal gibt die detaillierte Begründung für einen Wiederstart vom Bremsensteuergerät an. ";
CM_ SG_ 1629 ESP_Wiederstart_Anz_03 "Dieses Signal gibt die detaillierte Begründung für einen Wiederstart vom Bremsensteuergerät an. ";
CM_ SG_ 1629 ESP_Wiederstart_Anz_04 "Dieses Signal gibt die detaillierte Begründung für einen Wiederstart vom Bremsensteuergerät an.";
CM_ SG_ 1629 ESP_Zaehnezahl "Konstanter Wert der Zähnezahl des verwendeten Impulsrades wird ausgegeben, jeder Empfänger der Wegimpulse muss die Zähnezahl einlesen, um eine volle Umdrehung des Rades zu erkennen. 

Weiterführende Informationen im Lastenheft spezifiziert und in der en";
CM_ SG_ 1629 HDC_Charisma_FahrPr "MLBevo: Aktuelles Fahrprogramm des Charisma-Teilnehmers (siehe Systemlastenheft Drive Select)
MQB: Istwert der Kennlinie (siehe Systemlastenheft MQB FPA)";
CM_ SG_ 1629 HDC_Charisma_Status "Systemstatus des Charismateilnehmers

Wert 0x3 ist nur für Fahrzeuge ab MQB relevant";

CM_ SG_ 253 ABS_Bremsung "Antiblockiersystem, Bit zeigt auch Druckabbau an (z.B. ESP hat zuviel Druck aufgebaut oder ungebremste Regelung auf Bahnübergang)
Weiterführende Informationen im Lastenheft spezifiziert und in der entsprechenden Fachabteilung zu erfragen.";
CM_ SG_ 253 ASR_Anf "MLB: Die Momentenanforderung 'ASR_MSR_Moment_schnell' und 'ASR_Moment_langsam' sind auszuführen
MQB: Die Momentenanforderung 'BR_Eingriffsmoment' ist auszuführen";
CM_ SG_ 253 ASR_Schalteingriff "Wunsch an das Getriebe während einer ASR Regelung

MLB: Es wird nur 0x0 und 0x1 genutzt

";
CM_ SG_ 253 ASR_Tastung_passiv "ASR deaktiviert oder Schwellen geändert (projektabhängig)
Weiterführende Informationen im Lastenheft spezifiziert und in der entsprechenden Fachabteilung zu erfragen.
";
CM_ SG_ 253 BR_Eingriffsmoment "Einheitenloser Wert! Faktor in MO_Faktor_Momente_02 in Motor_Code_01 beachten!
Schnelle reduzierende (ASR) oder erhöhende (MSR) Momentanforderung an den Motor.";
CM_ SG_ 253 EBV_Eingriff "Elektronische Bremskraftverteilung, aktueller Eingriff (Druckhalten, Druckabbau)

Im MLB: kein ABS / ESP-Eingriff ???";
CM_ SG_ 253 EDS_Eingriff "Elektronische Differentialsperre";
CM_ SG_ 253 ESC_Neutralschaltung "Aufforderung seitens ABS an das Getriebe die Momentenübertragung zu unterbrechen";
CM_ SG_ 253 ESC_v_Signal_Qualifier_High_Low "Das Qualifizerungssignal ESC_v_Signal_Qualifier_High_Low gibt eine Information über die Güte der vom Bremsregelsystem ausgegebenen Geschwindigkeitsinformation 'mittlere Geschwindigkeit', wobei Vertrauensbereiche für das ausgegebene Geschwindigkeitssignal ";
CM_ SG_ 253 ESP_21_BZ "Botschaft asynchron geroutet. Zählerwert kann springen.";
CM_ SG_ 253 ESP_21_CRC "Für MLB:
'Berechnung siehe Lastenheft 'Kommunikationsabsicherung für FlexRay und CAN''

Ab MQB und MLBevo:
'Berechnung siehe Lastenheft 'End-to-End Kommunikationsabsicherung''

Endwerte siehe Begleitdokument 'S-PDU Kennungsfolgen'";
CM_ SG_ 253 ESP_ASP "MLB: Anhaenger-Stabilisierungs-Programm
MQB: Gespannstabilisierung";
CM_ SG_ 253 ESP_Diagnose "MLB: Nach Diagnoseende wird ein SW-Reset ausgelöst welcher einen Kommunikatiosausfall für max. 150ms verursacht. Dies ist bei SG mit verschärfter Timeoutüberwachung (nicht nach Konzern-LH) zu beachten.

MQB: Weiterführende Informationen im Lastenheft sp";
CM_ SG_ 253 ESP_Eingriff "Eingriff des Fahrdynamikreglers";
CM_ SG_ 253 ESP_QBit_v_Signal "Geschwindigkeit wird vom ABS/ASR oder ESP aus Ersatzwerten errechnet, wenn Bit gesetzt ist. Güte des Signals ist verändert.";
CM_ SG_ 253 ESP_Systemstatus "Fehler steht für Stillegung ESP mit Fehlereintrag.

MLB: Flag wird bei Unterspannung im Stand bis einmalig 6km/h (AU48x) oder 10 km/h (AU641, AU57x) überschritten nicht gesetzt (Ausblendung Startvorgang)
Im AU64x, AU57x gilt ESP D4 Funktionsanforderung";
CM_ SG_ 253 ESP_Tastung_passiv "ESP deaktiviert oder Schwellen geändert (projektabhängig)
Weiterführende Informationen im Lastenheft spezifiziert und in der entsprechenden Fachabteilung zu erfragen.";
CM_ SG_ 253 ESP_v_Signal "Geschwindigkeitssignal vom ABS/ASR oder ESP. Mittelwert der angetriebenen Räder.
Bei MSR oder ABS Eingriffen wird die ABS-Referenzgeschwindigkeit für >= 200ms eingespiegelt (Zeit wird mit Aktiv-Flanke der Funktionsbits getriggert)

MQB: Bei Frontantrie";
CM_ SG_ 253 ESP_Vorsteuerung "zur Unterscheidung zwischen ESP-Vorsteuermaßnahmen und ESP-Regeleingriffen";
CM_ SG_ 253 MSR_Anf "MLB: Die Momentenanforderung 'ASR_MSR_Moment_schnell' ist auszuführen.
MQB: Die Momentenanforderung 'BR_Eingriffsmoment' ist auszuführen";
CM_ SG_ 253 MSR_verfuegbar "Anzeige Verfügbarkeit der MSR Funktion 
0 = verfuegbar (MSR_Vollsystem oder MSR_Backup)
1 = nicht_verfuegbar (Init und Fehler)";
CM_ SG_ 253 OBD_Schlechtweg "Für Ausblendung der Zündaussetzererkennung im Motorsteuergerät (Otto). Bit wird gesetzt, wenn Rad-Drehbeschleunigung im ESP > Grenzwert ist. Vorteil gegenüber Radgeschwindigkeiten, dass ESP alle 2 ms dynamisch die Rad-Drehbeschleunigung errechnet und dem ";

CM_ SG_ 239 ESP_22_BZ "Botschaft asynchron geroutet. Zählerwert kann springen.";
CM_ SG_ 239 ESP_22_CRC "Für MLB:
'Berechnung siehe Lastenheft 'Kommunikationsabsicherung für FlexRay und CAN''

Ab MQB und MLBevo:
'Berechnung siehe Lastenheft 'End-to-End Kommunikationsabsicherung''

Endwerte siehe Begleitdokument 'S-PDU Kennungsfolgen'";
CM_ SG_ 239 ESP_FZR_uebersteuern "Fahrzeug erkennt uebersteuern";
CM_ SG_ 239 ESP_FZR_untersteuern "Fahrzeug erkennt untersteuern";
CM_ SG_ 239 ESP_HL_Bremsmoment "Bremsmoment HL
Ausgabe nach LAH: Ausgabe der internen Radbremsmomente / Radbremsdrücke / durch das ESP";
CM_ SG_ 239 ESP_HR_Bremsmoment "Bremsmoment HR
Ausgabe nach LAH: Ausgabe der internen Radbremsmomente / Radbremsdrücke / durch das ESP";
CM_ SG_ 239 ESP_QBit_HL_Bremsmoment "QBit Bremsmoment HL
Ausgabe nach LAH: Ausgabe der internen Radbremsmomente / Radbremsdrücke / durch das ESP.
Ersatzwert = Eingeschränkte Genauigkeit des zugehörigen Bremsmoments (ESP-Regelung: aktiver Druckauf/abbau)";
CM_ SG_ 239 ESP_QBit_HR_Bremsmoment "QBit Bremsmoment HR
Ausgabe nach LAH: Ausgabe der internen Radbremsmomente / Radbremsdrücke / durch das ESP.
Ersatzwert = Eingeschränkte Genauigkeit des zugehörigen Bremsmoments (ESP-Regelung: aktiver Druckauf/abbau)";
CM_ SG_ 239 ESP_QBit_VL_Bremsmoment "QBit Bremsmoment VL
Ausgabe nach LAH: Ausgabe der internen Radbremsmomente / Radbremsdrücke / durch das ESP.
Ersatzwert = Eingeschränkte Genauigkeit des zugehörigen Bremsmoments (ESP-Regelung: aktiver Druckauf/abbau)";
CM_ SG_ 239 ESP_QBit_VR_Bremsmoment "QBit Bremsmoment VR
Ausgabe nach LAH: Ausgabe der internen Radbremsmomente / Radbremsdrücke / durch das ESP.
Ersatzwert = Eingeschränkte Genauigkeit des zugehörigen Bremsmoments (ESP-Regelung: aktiver Druckauf/abbau)";
CM_ SG_ 239 ESP_VL_Bremsmoment "Bremsmoment VL
Ausgabe nach LAH: Ausgabe der internen Radbremsmomente / Radbremsdrücke / durch das ESP";
CM_ SG_ 239 ESP_VR_Bremsmoment "Bremsmoment VR
Ausgabe nach LAH: Ausgabe der internen Radbremsmomente / Radbremsdrücke / durch das ESP";

CM_ SG_ 1470 BR_QBit_Reifenumfang_sekundaer "QBit des Signals BR_Reifenumfang_sekundaer. 
Gesetzt bei Ersatzwert, Init oder Fehler.";
CM_ SG_ 1470 BR_Reifenumfang_sekundaer "Radumfang der Sekundärchse gerechnet in Millimeter.
Von der Bremse plausibilisierter Wert (Kopie von KBI_Reifenumfang_sekundaer wenn dieser plausibel) 
oder Ersatzwert aus Bremse wenn KBI_Reifenumfang_sekundaer unplausibel. Bitte das QBit beachten!
";
CM_ SG_ 1470 ESP_23_CRC "Für MLB:
'Berechnung siehe Lastenheft 'Kommunikationsabsicherung für FlexRay und CAN''

Ab MQB und MLBevo:
'Berechnung siehe Lastenheft 'End-to-End Kommunikationsabsicherung''

Endwerte siehe Begleitdokument 'S-PDU Kennungsfolgen'";
CM_ SG_ 1470 ESP_Gierrate_Offset_2 "Gierratenoffset berechnet durch ESP-Modell. 

nur für MLBevo gilt:
Der Offsetwert entspricht der Abweichung nach Anti-DIN-Vorzeichenlogik.
Gierrate_korrigiert = Gierrate_Rohwert + Gierratenoffset";
CM_ SG_ 1470 ESP_Laengsbeschleunigung_Offset "Offset der Längsbeschleunigung
Längsbeschleunigung = Rohwert - Offset

nur für MLBevo gilt:
Laengsbeschleunigungsoffset berechnet durch ESP-Modell. 
Laengsbeschleunigung_korrigiert = Laengsbeschleunigung_Rohwert - Laengsbeschleunigungsoffset";
CM_ SG_ 1470 ESP_Lenkwinkel_Offset "Lenkwinkelsoffset berechnet durch ESP-Modell!

nur für MLBevo gilt:
Der Offsetwert entspricht der Abweichung nach Anti-DIN-Vorzeichenlogik.
Lenkwinkel_korrigiert = Lenkwinkel_Rohwert + Lenkwinkeloffset";
CM_ SG_ 1470 ESP_Querbeschleunigung_Offset "Offset der Querbeschleunigung
Querbeschleunigung = Rohwert - Offset

nur für MLBevo gilt:
Querbeschleunigungsoffset berechnet durch ESP-Modell. 
Der Offsetwert entspricht der Abweichung nach Anti-DIN-Vorzeichenlogik.
Querbeschleunigung_korrigiert = ";
CM_ SG_ 1470 ESP_Status_Bremsentemp_Anz "Anzeigesignal für Bremsentemperatur";
BA_DEF_REL_ BU_SG_REL_  "GenSigTimeoutTime" INT 0 65535;
BA_DEF_ BO_  "DiagRequest" ENUM "No", "Yes";
BA_DEF_ BO_  "DiagResponse" ENUM "No", "Yes";
BA_DEF_ BO_  "DiagState" ENUM "No", "Yes";
BA_DEF_ BO_  "GenMsgChkConstant" HEX 0 4095;
BA_DEF_ BO_  "GenMsgCycleTime" INT 0 65535;
BA_DEF_ BO_  "GenMsgCycleTimeFast" INT 0 65535;
BA_DEF_ BO_  "GenMsgDelayTime" INT 0 100000;
BA_DEF_ BO_  "GenMsgILSupport" ENUM "No", "Yes";
BA_DEF_ BO_  "GenMsgNrOfRepetition" INT 0 100;
BA_DEF_ BO_  "GenMsgPDUConstants" STRING;
BA_DEF_ BO_  "GenMsgSendType" ENUM "Cyclic", "not_used", "not_used", "not_used", "not_used", "not_used", "not_used", "IfActive", "NoMsgSendType";
BA_DEF_ BO_  "GenMsgStartDelayTime" INT 0 100000;
BA_DEF_ BO_  "NmMessage" ENUM "No", "Yes";
BA_DEF_ BO_  "NmhMessage" ENUM "No", "Yes";
BA_DEF_ BO_  "MsgType" ENUM "Application", "NM ", "NMH", "TP2.0", "ISO-TP ", "BAP", "EID", "KS", "XCP_PRE_CONFIGURED", "XCP_RUNTIME_CONFIGURED";
BA_DEF_ BO_  "VAGTP20_API" HEX 0 255;
BA_DEF_ BO_  "VAGTP20_DynConnection" ENUM "No", "Yes";
BA_DEF_ BO_  "VAGTP20_DynSetup" ENUM "No", "Yes";
BA_DEF_ BO_  "VAGTP20_StatConnection" ENUM "No", "Yes";
BA_DEF_ SG_  "GenSigActiveRepetitions" INT -2147483648 2147483647;
BA_DEF_ SG_  "GenSigInactiveValue" INT -2147483648 2147483647;
BA_DEF_ SG_  "GenSigSendType" ENUM "Cyclic", "OnWrite", "OnWriteWithRepetition", "OnChange", "OnChangeWithRepetition", "IfActive", "IfActiveWithRepetition", "NoSigSendType", "OnChangeAndIfActive", "OnChangeAndIfActiveWithRepetition";
BA_DEF_ SG_  "GenSigStartValue" INT -2147483648 2147483647;
BA_DEF_ SG_  "NWM-WakeupAllowed" ENUM "No", "Yes";
BA_DEF_ SG_  "GenSigFuncType" ENUM "NoFunction", "MsgCounter", "CRC-8", "XOR", "XOR-2", "DatedBit", "SW-Kl15", "CHK", "Constant", "Protocol", "CRC-8-SAE_J1850", "CRC-32", "DataLength", "DataID", "MsgCounter16", "SOK-Signatur", "Cluster";
BA_DEF_ SG_  "GenSigSwitchedByIgnition" ENUM "No", "Yes";
BA_DEF_ SG_  "Fehlerwert" HEX 0 2147483647;
BA_DEF_ SG_  "GenSigMissingSourceValue" HEX 0 2147483647;
BA_DEF_DEF_REL_  "GenSigTimeoutTime" 0;
BA_DEF_DEF_  "DiagRequest" "No";
BA_DEF_DEF_  "DiagResponse" "No";
BA_DEF_DEF_  "DiagState" "No";
BA_DEF_DEF_  "GenMsgChkConstant" 0;
BA_DEF_DEF_  "GenMsgCycleTime" 0;
BA_DEF_DEF_  "GenMsgCycleTimeFast" 0;
BA_DEF_DEF_  "GenMsgDelayTime" 0;
BA_DEF_DEF_  "GenMsgILSupport" "No";
BA_DEF_DEF_  "GenMsgNrOfRepetition" 0;
BA_DEF_DEF_  "GenMsgPDUConstants" "";
BA_DEF_DEF_  "GenMsgSendType" "NoMsgSendType";
BA_DEF_DEF_  "GenMsgStartDelayTime" 0;
BA_DEF_DEF_  "NmMessage" "No";
BA_DEF_DEF_  "NmhMessage" "No";
BA_DEF_DEF_  "MsgType" "Application";
BA_DEF_DEF_  "VAGTP20_API" 0;
BA_DEF_DEF_  "VAGTP20_DynConnection" "No";
BA_DEF_DEF_  "VAGTP20_DynSetup" "No";
BA_DEF_DEF_  "VAGTP20_StatConnection" "No";
BA_DEF_DEF_  "GenSigActiveRepetitions" 0;
BA_DEF_DEF_  "GenSigInactiveValue" 0;
BA_DEF_DEF_  "GenSigSendType" "NoSigSendType";
BA_DEF_DEF_  "GenSigStartValue" 0;
BA_DEF_DEF_  "NWM-WakeupAllowed" "No";
BA_DEF_DEF_  "GenSigFuncType" "NoFunction";
BA_DEF_DEF_  "GenSigSwitchedByIgnition" "Yes";
BA_DEF_DEF_  "Fehlerwert" 0;
BA_DEF_DEF_  "GenSigMissingSourceValue" 0;
BA_ "MsgType" BO_ 2617219614 6;
BA_ "MsgType" BO_ 2617219604 6;
BA_ "GenMsgCycleTime" BO_ 2617219605 1000;
BA_ "GenMsgDelayTime" BO_ 2617219605 40;
BA_ "MsgType" BO_ 2617219605 6;
BA_ "DiagRequest" BO_ 2549880610 1;
BA_ "MsgType" BO_ 2549880610 4;
BA_ "DiagResponse" BO_ 2550011682 1;
BA_ "MsgType" BO_ 2550011682 4;
BA_ "DiagRequest" BO_ 2549880611 1;
BA_ "MsgType" BO_ 2549880611 4;
BA_ "DiagResponse" BO_ 2550011683 1;
BA_ "MsgType" BO_ 2550011683 4;
BA_ "DiagRequest" BO_ 2549880473 1;
BA_ "MsgType" BO_ 2549880473 4;
BA_ "DiagResponse" BO_ 2550011545 1;
BA_ "MsgType" BO_ 2550011545 4;
BA_ "DiagRequest" BO_ 2549880474 1;
BA_ "MsgType" BO_ 2549880474 4;
BA_ "DiagResponse" BO_ 2550011546 1;
BA_ "MsgType" BO_ 2550011546 4;
BA_ "GenMsgCycleTime" BO_ 1714 1000;
BA_ "GenMsgILSupport" BO_ 1714 1;
BA_ "GenMsgSendType" BO_ 1714 0;
BA_ "GenMsgStartDelayTime" BO_ 1714 55;
BA_ "GenMsgCycleTime" BO_ 1520 200;
BA_ "GenMsgDelayTime" BO_ 1520 50;
BA_ "GenMsgILSupport" BO_ 1520 1;
BA_ "GenMsgSendType" BO_ 1520 0;
BA_ "GenMsgCycleTime" BO_ 420 500;
BA_ "GenMsgILSupport" BO_ 420 1;
BA_ "GenMsgPDUConstants" BO_ 420 "0x69,0xbb,0x54,0xe6,0x4e,0x46,0x8d,0x7b,0xea,0x87,0xe9,0xb3,0x63,0xce,0xf8,0xbf";
BA_ "GenMsgSendType" BO_ 420 0;
BA_ "GenMsgStartDelayTime" BO_ 420 130;
BA_ "GenMsgCycleTime" BO_ 496 50;
BA_ "GenMsgDelayTime" BO_ 496 20;
BA_ "GenMsgILSupport" BO_ 496 1;
BA_ "GenMsgPDUConstants" BO_ 496 "0x2f,0x3c,0x22,0x60,0x18,0xeb,0x63,0x76,0xc5,0x91,0x0f,0x27,0x34,0x04,0x7f,0x02";
BA_ "GenMsgSendType" BO_ 496 0;
BA_ "GenMsgCycleTime" BO_ 189 100;
BA_ "GenMsgILSupport" BO_ 189 1;
BA_ "GenMsgPDUConstants" BO_ 189 "0x2e,0x26,0xad,0xb2,0xbf,0x0b,0x63,0x06,0x87,0x11,0x8d,0x25,0xe6,0x77,0x69,0x24";
BA_ "GenMsgSendType" BO_ 189 0;
BA_ "GenMsgCycleTime" BO_ 2527679980 500;
BA_ "GenMsgDelayTime" BO_ 2527679980 50;
BA_ "GenMsgILSupport" BO_ 2527679980 1;
BA_ "GenMsgSendType" BO_ 2527679980 0;
BA_ "GenMsgStartDelayTime" BO_ 2527679980 50;
BA_ "GenMsgCycleTime" BO_ 996 1000;
BA_ "GenMsgDelayTime" BO_ 996 50;
BA_ "GenMsgILSupport" BO_ 996 1;
BA_ "GenMsgSendType" BO_ 996 0;
BA_ "GenMsgStartDelayTime" BO_ 996 60;
BA_ "GenMsgCycleTime" BO_ 1603 1000;
BA_ "GenMsgDelayTime" BO_ 1603 100;
BA_ "GenMsgILSupport" BO_ 1603 1;
BA_ "GenMsgSendType" BO_ 1603 0;
BA_ "GenMsgCycleTime" BO_ 1622 1000;
BA_ "GenMsgCycleTimeFast" BO_ 1622 50;
BA_ "GenMsgDelayTime" BO_ 1622 50;
BA_ "GenMsgILSupport" BO_ 1622 1;
BA_ "GenMsgPDUConstants" BO_ 1622 "0xab,0x2f,0xd3,0x39,0x6f,0x37,0xfa,0x59,0xa4,0x70,0xce,0x11,0x54,0x82,0x62,0x56";
BA_ "GenMsgSendType" BO_ 1622 0;
BA_ "GenMsgCycleTime" BO_ 115 50;
BA_ "GenMsgILSupport" BO_ 115 1;
BA_ "GenMsgPDUConstants" BO_ 115 "0xdb,0x71,0x31,0xf9,0x26,0x43,0x6d,0x22,0x52,0xe4,0xe8,0xa9,0x73,0x1c,0xc5,0x67";
BA_ "GenMsgSendType" BO_ 115 0;
BA_ "GenMsgChkConstant" BO_ 260 5;
BA_ "GenMsgCycleTime" BO_ 260 500;
BA_ "GenMsgDelayTime" BO_ 260 40;
BA_ "GenMsgILSupport" BO_ 260 1;
BA_ "GenMsgPDUConstants" BO_ 260 "0x05,0x05,0x05,0x05,0x05,0x05,0x05,0x05,0x05,0x05,0x05,0x05,0x05,0x05,0x05,0x05";
BA_ "GenMsgSendType" BO_ 260 0;
BA_ "GenMsgStartDelayTime" BO_ 260 65;
BA_ "GenMsgCycleTime" BO_ 781 200;
BA_ "GenMsgDelayTime" BO_ 781 20;
BA_ "GenMsgILSupport" BO_ 781 1;
BA_ "GenMsgSendType" BO_ 781 0;
BA_ "GenMsgStartDelayTime" BO_ 781 30;
BA_ "GenMsgChkConstant" BO_ 259 2;
BA_ "GenMsgCycleTime" BO_ 259 100;
BA_ "GenMsgILSupport" BO_ 259 1;
BA_ "GenMsgPDUConstants" BO_ 259 "0x02,0x02,0x02,0x02,0x02,0x02,0x02,0x02,0x02,0x02,0x02,0x02,0x02,0x02,0x02,0x02";
BA_ "GenMsgSendType" BO_ 259 0;
BA_ "GenMsgChkConstant" BO_ 262 7;
BA_ "GenMsgCycleTime" BO_ 262 50;
BA_ "GenMsgDelayTime" BO_ 262 20;
BA_ "GenMsgILSupport" BO_ 262 1;
BA_ "GenMsgPDUConstants" BO_ 262 "0x07,0x07,0x07,0x07,0x07,0x07,0x07,0x07,0x07,0x07,0x07,0x07,0x07,0x07,0x07,0x07";
BA_ "GenMsgSendType" BO_ 262 0;
BA_ "GenMsgStartDelayTime" BO_ 262 40;
BA_ "GenMsgChkConstant" BO_ 914 145;
BA_ "GenMsgCycleTime" BO_ 914 1000;
BA_ "GenMsgDelayTime" BO_ 914 80;
BA_ "GenMsgILSupport" BO_ 914 1;
BA_ "GenMsgPDUConstants" BO_ 914 "0x91,0x91,0x91,0x91,0x91,0x91,0x91,0x91,0x91,0x91,0x91,0x91,0x91,0x91,0x91,0x91";
BA_ "GenMsgSendType" BO_ 914 0;
BA_ "GenMsgChkConstant" BO_ 278 172;
BA_ "GenMsgCycleTime" BO_ 278 50;
BA_ "GenMsgILSupport" BO_ 278 1;
BA_ "GenMsgPDUConstants" BO_ 278 "0xac,0xac,0xac,0xac,0xac,0xac,0xac,0xac,0xac,0xac,0xac,0xac,0xac,0xac,0xac,0xac";
BA_ "GenMsgSendType" BO_ 278 0;
BA_ "GenMsgCycleTime" BO_ 418 1000;
BA_ "GenMsgDelayTime" BO_ 418 20;
BA_ "GenMsgILSupport" BO_ 418 1;
BA_ "GenMsgPDUConstants" BO_ 418 "0xcb,0x47,0xd7,0xd2,0x56,0x3e,0x20,0xea,0x6e,0x6d,0x8c,0x1b,0xdf,0x49,0xaa,0xab";
BA_ "GenMsgSendType" BO_ 418 0;
BA_ "GenMsgCycleTime" BO_ 1629 160;
BA_ "GenMsgILSupport" BO_ 1629 1;
BA_ "GenMsgPDUConstants" BO_ 1629 "0xac,0xb3,0xab,0xeb,0x7a,0xe1,0x3b,0xf7,0x73,0xba,0x7c,0x9e,0x06,0x5f,0x02,0xd9";
BA_ "GenMsgSendType" BO_ 1629 0;
BA_ "GenMsgCycleTime" BO_ 253 100;
BA_ "GenMsgILSupport" BO_ 253 1;
BA_ "GenMsgPDUConstants" BO_ 253 "0xb4,0xef,0xf8,0x49,0x1e,0xe5,0xc2,0xc0,0x97,0x19,0x3c,0xc9,0xf1,0x98,0xd6,0x61";
BA_ "GenMsgSendType" BO_ 253 0;
BA_ "GenMsgChkConstant" BO_ 239 6;
BA_ "GenMsgCycleTime" BO_ 239 50;
BA_ "GenMsgILSupport" BO_ 239 1;
BA_ "GenMsgPDUConstants" BO_ 239 "0x06,0x06,0x06,0x06,0x06,0x06,0x06,0x06,0x06,0x06,0x06,0x06,0x06,0x06,0x06,0x06";
BA_ "GenMsgSendType" BO_ 239 0;
BA_ "GenMsgCycleTime" BO_ 1470 320;
BA_ "GenMsgILSupport" BO_ 1470 1;
BA_ "GenMsgPDUConstants" BO_ 1470 "0xc9,0x21,0x6f,0x63,0xd2,0x42,0x6a,0x77,0x4a,0x3d,0xb0,0x62,0x9f,0x38,0xcd,0x5c";
BA_ "GenMsgSendType" BO_ 1470 0;
BA_ "GenSigSwitchedByIgnition" SG_ 2617219614 DEV_ZR_Pwm_Debug_1 0;
BA_ "GenSigSwitchedByIgnition" SG_ 2617219614 DEV_ZR_Pwm_Debug_2 0;
BA_ "GenSigSwitchedByIgnition" SG_ 2617219614 DEV_ZR_Pwm_Debug_3 0;
BA_ "GenSigSwitchedByIgnition" SG_ 2617219614 DEV_ZR_Pwm_Debug_4 0;
BA_ "GenSigSwitchedByIgnition" SG_ 2617219604 DEV_ZR_Tx_14_Data 0;
BA_ "GenSigSwitchedByIgnition" SG_ 2617219605 DEV_ZR_Tx_15_Data 0;
BA_ "GenSigSendType" SG_ 2617219605 MMI_State 3;
BA_ "GenSigSwitchedByIgnition" SG_ 2617219605 MMI_State 0;
BA_ "GenSigSendType" SG_ 2617219605 Reset_Counter 0;
BA_ "GenSigStartValue" SG_ 2617219605 Reset_Counter 254;
BA_ "GenSigSwitchedByIgnition" SG_ 2617219605 Reset_Counter 0;
BA_ "GenSigSendType" SG_ 2617219605 Routeg_aktiv 3;
BA_ "GenSigSwitchedByIgnition" SG_ 2617219605 Routeg_aktiv 0;
BA_ "GenSigSendType" SG_ 2617219605 SI_MOST_Status 3;
BA_ "GenSigSwitchedByIgnition" SG_ 2617219605 SI_MOST_Status 0;
BA_ "GenSigSendType" SG_ 2617219605 Tel_aktiv 3;
BA_ "GenSigSwitchedByIgnition" SG_ 2617219605 Tel_aktiv 0;
BA_ "GenSigSwitchedByIgnition" SG_ 2617219605 Tel_SIM_aktiv 0;
BA_ "GenSigSendType" SG_ 2617219605 ZR_KL_30F 0;
BA_ "GenSigStartValue" SG_ 2617219605 ZR_KL_30F 254;
BA_ "GenSigSwitchedByIgnition" SG_ 2617219605 ZR_KL_30F 0;
BA_ "Fehlerwert" SG_ 2617219605 ZR_KL_30F 255;
BA_ "GenSigSendType" SG_ 2617219605 ZR_LastOn 3;
BA_ "GenSigStartValue" SG_ 2617219605 ZR_LastOn 7;
BA_ "GenSigSwitchedByIgnition" SG_ 2617219605 ZR_LastOn 0;
BA_ "GenSigSendType" SG_ 2617219605 ZR_State_DU_1 3;
BA_ "GenSigSwitchedByIgnition" SG_ 2617219605 ZR_State_DU_1 0;
BA_ "GenSigSendType" SG_ 2617219605 ZR_TempSens 0;
BA_ "GenSigStartValue" SG_ 2617219605 ZR_TempSens 254;
BA_ "GenSigSwitchedByIgnition" SG_ 2617219605 ZR_TempSens 0;
BA_ "Fehlerwert" SG_ 2617219605 ZR_TempSens 255;
BA_ "GenSigSendType" SG_ 2549880610 DIA_SCON1_Req_Data 3;
BA_ "GenSigFuncType" SG_ 2549880610 DIA_SCON1_Req_Data 9;
BA_ "GenSigSwitchedByIgnition" SG_ 2549880610 DIA_SCON1_Req_Data 0;
BA_ "GenSigSendType" SG_ 2550011682 DIA_SCON1_Resp_Data 3;
BA_ "GenSigFuncType" SG_ 2550011682 DIA_SCON1_Resp_Data 9;
BA_ "GenSigSwitchedByIgnition" SG_ 2550011682 DIA_SCON1_Resp_Data 0;
BA_ "GenSigSendType" SG_ 2549880611 DIA_SCON2_Req_Data 3;
BA_ "GenSigFuncType" SG_ 2549880611 DIA_SCON2_Req_Data 9;
BA_ "GenSigSwitchedByIgnition" SG_ 2549880611 DIA_SCON2_Req_Data 0;
BA_ "GenSigSendType" SG_ 2550011683 DIA_SCON2_Resp_Data 3;
BA_ "GenSigFuncType" SG_ 2550011683 DIA_SCON2_Resp_Data 9;
BA_ "GenSigSwitchedByIgnition" SG_ 2550011683 DIA_SCON2_Resp_Data 0;
BA_ "GenSigSendType" SG_ 2549880473 DIA_SD3_Req_Data 3;
BA_ "GenSigFuncType" SG_ 2549880473 DIA_SD3_Req_Data 9;
BA_ "GenSigSwitchedByIgnition" SG_ 2549880473 DIA_SD3_Req_Data 0;
BA_ "GenSigSendType" SG_ 2550011545 DIA_SD3_Resp_Data 3;
BA_ "GenSigFuncType" SG_ 2550011545 DIA_SD3_Resp_Data 9;
BA_ "GenSigSwitchedByIgnition" SG_ 2550011545 DIA_SD3_Resp_Data 0;
BA_ "GenSigSendType" SG_ 2549880474 DIA_SD4_Req_Data 3;
BA_ "GenSigFuncType" SG_ 2549880474 DIA_SD4_Req_Data 9;
BA_ "GenSigSwitchedByIgnition" SG_ 2549880474 DIA_SD4_Req_Data 0;
BA_ "GenSigSendType" SG_ 2550011546 DIA_SD4_Resp_Data 3;
BA_ "GenSigFuncType" SG_ 2550011546 DIA_SD4_Resp_Data 9;
BA_ "GenSigSwitchedByIgnition" SG_ 2550011546 DIA_SD4_Resp_Data 0;
BA_ "GenSigSendType" SG_ 1714 DGN_Verlernzaehler 0;
BA_ "GenSigSwitchedByIgnition" SG_ 1714 DGN_Verlernzaehler 0;
BA_ "GenSigSendType" SG_ 1714 KBI_Kilometerstand 0;
BA_ "GenSigStartValue" SG_ 1714 KBI_Kilometerstand 1048574;
BA_ "GenSigSwitchedByIgnition" SG_ 1714 KBI_Kilometerstand 0;
BA_ "Fehlerwert" SG_ 1714 KBI_Kilometerstand 1048575;
BA_ "GenSigSendType" SG_ 1714 Kombi_02_alt 0;
BA_ "GenSigStartValue" SG_ 1714 Kombi_02_alt 1;
BA_ "GenSigFuncType" SG_ 1714 Kombi_02_alt 5;
BA_ "GenSigSwitchedByIgnition" SG_ 1714 Kombi_02_alt 0;
BA_ "GenSigSendType" SG_ 1714 UH_Jahr 0;
BA_ "GenSigSwitchedByIgnition" SG_ 1714 UH_Jahr 0;
BA_ "GenSigSendType" SG_ 1714 UH_Minute 0;
BA_ "GenSigSwitchedByIgnition" SG_ 1714 UH_Minute 0;
BA_ "GenSigSendType" SG_ 1714 UH_Monat 0;
BA_ "GenSigSwitchedByIgnition" SG_ 1714 UH_Monat 0;
BA_ "Fehlerwert" SG_ 1714 UH_Monat 15;
BA_ "GenSigSendType" SG_ 1714 UH_Sekunde 0;
BA_ "GenSigSwitchedByIgnition" SG_ 1714 UH_Sekunde 0;
BA_ "GenSigSendType" SG_ 1714 UH_Stunde 0;
BA_ "GenSigSwitchedByIgnition" SG_ 1714 UH_Stunde 0;
BA_ "GenSigSendType" SG_ 1714 UH_Tag 0;
BA_ "GenSigSwitchedByIgnition" SG_ 1714 UH_Tag 0;
BA_ "GenSigSendType" SG_ 1714 Uhrzeit_01_alt 0;
BA_ "GenSigStartValue" SG_ 1714 Uhrzeit_01_alt 1;
BA_ "GenSigFuncType" SG_ 1714 Uhrzeit_01_alt 5;
BA_ "GenSigSwitchedByIgnition" SG_ 1714 Uhrzeit_01_alt 0;
BA_ "GenSigSendType" SG_ 1520 BCM1_Stellgroesse_Kl_58s 3;
BA_ "GenSigStartValue" SG_ 1520 BCM1_Stellgroesse_Kl_58s 126;
BA_ "GenSigSwitchedByIgnition" SG_ 1520 BCM1_Stellgroesse_Kl_58s 0;
BA_ "Fehlerwert" SG_ 1520 BCM1_Stellgroesse_Kl_58s 127;
BA_ "GenSigSendType" SG_ 1520 DI_Display_Nachtdesign 3;
BA_ "GenSigSwitchedByIgnition" SG_ 1520 DI_Display_Nachtdesign 0;
BA_ "GenSigSendType" SG_ 1520 DI_Fotosensor 3;
BA_ "GenSigSwitchedByIgnition" SG_ 1520 DI_Fotosensor 0;
BA_ "GenSigSendType" SG_ 1520 DI_KL_58xd 3;
BA_ "GenSigStartValue" SG_ 1520 DI_KL_58xd 254;
BA_ "GenSigSwitchedByIgnition" SG_ 1520 DI_KL_58xd 0;
BA_ "Fehlerwert" SG_ 1520 DI_KL_58xd 255;
BA_ "GenSigSendType" SG_ 1520 DI_KL_58xs 3;
BA_ "GenSigStartValue" SG_ 1520 DI_KL_58xs 126;
BA_ "GenSigSwitchedByIgnition" SG_ 1520 DI_KL_58xs 0;
BA_ "Fehlerwert" SG_ 1520 DI_KL_58xs 127;
BA_ "GenSigSendType" SG_ 1520 DI_KL_58xt 3;
BA_ "GenSigStartValue" SG_ 1520 DI_KL_58xt 126;
BA_ "GenSigSwitchedByIgnition" SG_ 1520 DI_KL_58xt 0;
BA_ "Fehlerwert" SG_ 1520 DI_KL_58xt 127;
BA_ "GenSigSendType" SG_ 420 EA_01_BZ 0;
BA_ "GenSigFuncType" SG_ 420 EA_01_BZ 1;
BA_ "GenSigSendType" SG_ 420 EA_01_CRC 0;
BA_ "GenSigFuncType" SG_ 420 EA_01_CRC 2;
BA_ "GenSigSendType" SG_ 420 EA_Anforderung_HMS 0;
BA_ "GenSigSendType" SG_ 420 EA_eCall_Anf 0;
BA_ "GenSigSwitchedByIgnition" SG_ 420 EA_eCall_Anf 0;
BA_ "GenSigSendType" SG_ 420 EA_Funktionsstatus 0;
BA_ "GenSigSendType" SG_ 420 EA_Gurtstraffer_Anf 0;
BA_ "GenSigSendType" SG_ 420 EA_Parken_beibehalten_HMS 0;
BA_ "GenSigStartValue" SG_ 420 EA_Parken_beibehalten_HMS 2;
BA_ "Fehlerwert" SG_ 420 EA_Parken_beibehalten_HMS 3;
BA_ "GenSigSendType" SG_ 420 EA_Sollbeschleunigung 0;
BA_ "GenSigStartValue" SG_ 420 EA_Sollbeschleunigung 2046;
BA_ "Fehlerwert" SG_ 420 EA_Sollbeschleunigung 2047;
BA_ "GenSigSendType" SG_ 420 EA_Warnruckprofil 0;
BA_ "GenSigSendType" SG_ 496 ACF_Lampe_Hands_Off 3;
BA_ "GenSigSwitchedByIgnition" SG_ 496 ACF_Lampe_Hands_Off 0;
BA_ "GenSigSendType" SG_ 496 EA_02_BZ 0;
BA_ "GenSigFuncType" SG_ 496 EA_02_BZ 1;
BA_ "GenSigSendType" SG_ 496 EA_02_CRC 0;
BA_ "GenSigFuncType" SG_ 496 EA_02_CRC 2;
BA_ "GenSigSendType" SG_ 496 EA_Blinken 3;
BA_ "GenSigSendType" SG_ 496 EA_Bremslichtblinken 3;
BA_ "GenSigSendType" SG_ 496 EA_Infotainment_Anf 3;
BA_ "GenSigSendType" SG_ 496 EA_Innenraumlicht_Anf 3;
BA_ "GenSigSendType" SG_ 496 EA_Status_HMI 3;
BA_ "GenSigSendType" SG_ 496 EA_Texte 3;
BA_ "GenSigSendType" SG_ 496 EA_Tueren_Anf 3;
BA_ "GenSigSendType" SG_ 496 STP_Primaeranz 3;
BA_ "GenSigSendType" SG_ 496 zFAS_Warnblinken 3;
BA_ "GenSigSendType" SG_ 189 EBKV_01_BZ 0;
BA_ "GenSigFuncType" SG_ 189 EBKV_01_BZ 1;
BA_ "GenSigSwitchedByIgnition" SG_ 189 EBKV_01_BZ 0;
BA_ "GenSigSendType" SG_ 189 EBKV_01_CRC 0;
BA_ "GenSigFuncType" SG_ 189 EBKV_01_CRC 2;
BA_ "GenSigSwitchedByIgnition" SG_ 189 EBKV_01_CRC 0;
BA_ "GenSigSendType" SG_ 189 EBKV_AktBr_aktiv 0;
BA_ "GenSigSwitchedByIgnition" SG_ 189 EBKV_AktBr_aktiv 0;
BA_ "GenSigSendType" SG_ 189 EBKV_AktSp_Status 0;
BA_ "GenSigSwitchedByIgnition" SG_ 189 EBKV_AktSp_Status 0;
BA_ "GenSigSendType" SG_ 189 EBKV_AktSp_Volumenreserve 0;
BA_ "GenSigStartValue" SG_ 189 EBKV_AktSp_Volumenreserve 254;
BA_ "GenSigSwitchedByIgnition" SG_ 189 EBKV_AktSp_Volumenreserve 0;
BA_ "Fehlerwert" SG_ 189 EBKV_AktSp_Volumenreserve 255;
BA_ "GenSigSendType" SG_ 189 EBKV_extBr_Status 0;
BA_ "GenSigSwitchedByIgnition" SG_ 189 EBKV_extBr_Status 0;
BA_ "GenSigSendType" SG_ 189 EBKV_HZ_Bohrung_geschlossen 0;
BA_ "GenSigSwitchedByIgnition" SG_ 189 EBKV_HZ_Bohrung_geschlossen 0;
BA_ "GenSigSendType" SG_ 189 EBKV_Kraftblending_Reserve 0;
BA_ "GenSigStartValue" SG_ 189 EBKV_Kraftblending_Reserve 254;
BA_ "GenSigSwitchedByIgnition" SG_ 189 EBKV_Kraftblending_Reserve 0;
BA_ "Fehlerwert" SG_ 189 EBKV_Kraftblending_Reserve 255;
BA_ "GenSigSendType" SG_ 189 EBKV_Stangenweg 0;
BA_ "GenSigStartValue" SG_ 189 EBKV_Stangenweg 4094;
BA_ "GenSigSwitchedByIgnition" SG_ 189 EBKV_Stangenweg 0;
BA_ "Fehlerwert" SG_ 189 EBKV_Stangenweg 4095;
BA_ "GenSigSendType" SG_ 189 EBKV_Status_02 0;
BA_ "GenSigSwitchedByIgnition" SG_ 189 EBKV_Status_02 0;
BA_ "GenSigSendType" SG_ 189 SEKU_Anforderung_GE 0;
BA_ "GenSigSwitchedByIgnition" SG_ 189 SEKU_Anforderung_GE 0;
BA_ "GenSigSendType" SG_ 189 SEKU_Bremslicht 0;
BA_ "GenSigSwitchedByIgnition" SG_ 189 SEKU_Bremslicht 0;
BA_ "GenSigSendType" SG_ 189 SEKU_Status 0;
BA_ "GenSigSwitchedByIgnition" SG_ 189 SEKU_Status 0;
BA_ "GenSigSendType" SG_ 2527679980 bCall_active 3;
BA_ "GenSigSwitchedByIgnition" SG_ 2527679980 bCall_active 0;
BA_ "GenSigSendType" SG_ 2527679980 eCall_Funktionsstatus 3;
BA_ "GenSigSwitchedByIgnition" SG_ 2527679980 eCall_Funktionsstatus 0;
BA_ "GenSigSendType" SG_ 2527679980 eCall_Funktionsstatus_02 3;
BA_ "GenSigStartValue" SG_ 2527679980 eCall_Funktionsstatus_02 7;
BA_ "GenSigSwitchedByIgnition" SG_ 2527679980 eCall_Funktionsstatus_02 0;
BA_ "GenSigSendType" SG_ 2527679980 eCall_Mute_Anf 3;
BA_ "GenSigSwitchedByIgnition" SG_ 2527679980 eCall_Mute_Anf 0;
BA_ "GenSigSendType" SG_ 2527679980 eCall_Statuslicht_Farbe1 3;
BA_ "GenSigSwitchedByIgnition" SG_ 2527679980 eCall_Statuslicht_Farbe1 0;
BA_ "GenSigSendType" SG_ 2527679980 eCall_Statuslicht_Farbe2 3;
BA_ "GenSigSwitchedByIgnition" SG_ 2527679980 eCall_Statuslicht_Farbe2 0;
BA_ "GenSigSendType" SG_ 2527679980 eCall_Subscription 3;
BA_ "GenSigSwitchedByIgnition" SG_ 2527679980 eCall_Subscription 0;
BA_ "GenSigSendType" SG_ 996 EFF_Einsparhinweis 3;
BA_ "GenSigSwitchedByIgnition" SG_ 996 EFF_Einsparhinweis 0;
BA_ "GenSigSendType" SG_ 996 EFF_Verbrauch_STH 3;
BA_ "GenSigSwitchedByIgnition" SG_ 996 EFF_Verbrauch_STH 0;
BA_ "Fehlerwert" SG_ 996 EFF_Verbrauch_STH 127;
BA_ "GenSigSendType" SG_ 996 EFF_Verbraucher_Balken 3;
BA_ "GenSigStartValue" SG_ 996 EFF_Verbraucher_Balken 510;
BA_ "GenSigSwitchedByIgnition" SG_ 996 EFF_Verbraucher_Balken 0;
BA_ "Fehlerwert" SG_ 996 EFF_Verbraucher_Balken 511;
BA_ "GenSigSendType" SG_ 996 EFF_Verbraucher_Pos_1 3;
BA_ "GenSigSwitchedByIgnition" SG_ 996 EFF_Verbraucher_Pos_1 0;
BA_ "GenSigSendType" SG_ 996 EFF_Verbraucher_Pos_2 3;
BA_ "GenSigSwitchedByIgnition" SG_ 996 EFF_Verbraucher_Pos_2 0;
BA_ "GenSigSendType" SG_ 996 EFF_Verbraucher_Pos_3 3;
BA_ "GenSigSwitchedByIgnition" SG_ 996 EFF_Verbraucher_Pos_3 0;
BA_ "GenSigSendType" SG_ 996 MKE_FAS 3;
BA_ "GenSigSwitchedByIgnition" SG_ 996 MKE_FAS 0;
BA_ "GenSigSendType" SG_ 996 MKE_FAS_Fkt_Status 0;
BA_ "GenSigSwitchedByIgnition" SG_ 996 MKE_FAS_Fkt_Status 0;
BA_ "Fehlerwert" SG_ 996 MKE_FAS_Fkt_Status 3;
BA_ "GenSigSendType" SG_ 996 MKE_Fehlercode 3;
BA_ "GenSigSwitchedByIgnition" SG_ 996 MKE_Fehlercode 0;
BA_ "GenSigSendType" SG_ 996 MKE_Stufe 0;
BA_ "GenSigSwitchedByIgnition" SG_ 996 MKE_Stufe 0;
BA_ "GenSigSendType" SG_ 996 MKE_Texte 0;
BA_ "GenSigSwitchedByIgnition" SG_ 996 MKE_Texte 0;
BA_ "GenSigSendType" SG_ 1603 KBI_Einheit_Datum 3;
BA_ "GenSigSwitchedByIgnition" SG_ 1603 KBI_Einheit_Datum 0;
BA_ "GenSigSendType" SG_ 1603 KBI_Einheit_Druck 3;
BA_ "GenSigSwitchedByIgnition" SG_ 1603 KBI_Einheit_Druck 0;
BA_ "GenSigSendType" SG_ 1603 KBI_Einheit_Masse 3;
BA_ "GenSigSwitchedByIgnition" SG_ 1603 KBI_Einheit_Masse 0;
BA_ "GenSigSendType" SG_ 1603 KBI_Einheit_Sprache 3;
BA_ "GenSigSwitchedByIgnition" SG_ 1603 KBI_Einheit_Sprache 0;
BA_ "GenSigSendType" SG_ 1603 KBI_Einheit_Streckenanz 3;
BA_ "GenSigSwitchedByIgnition" SG_ 1603 KBI_Einheit_Streckenanz 0;
BA_ "GenSigSendType" SG_ 1603 KBI_Einheit_Temp 3;
BA_ "GenSigSwitchedByIgnition" SG_ 1603 KBI_Einheit_Temp 0;
BA_ "GenSigSendType" SG_ 1603 KBI_Einheit_Uhrzeit 3;
BA_ "GenSigSwitchedByIgnition" SG_ 1603 KBI_Einheit_Uhrzeit 0;
BA_ "GenSigSendType" SG_ 1603 KBI_Einheit_Verbrauch 3;
BA_ "GenSigSwitchedByIgnition" SG_ 1603 KBI_Einheit_Verbrauch 0;
BA_ "GenSigSendType" SG_ 1603 KBI_Einheit_Verbrauch_elektr 3;
BA_ "GenSigSwitchedByIgnition" SG_ 1603 KBI_Einheit_Verbrauch_elektr 0;
BA_ "GenSigSendType" SG_ 1603 KBI_Einheit_Verbrauch_Gas 3;
BA_ "GenSigSwitchedByIgnition" SG_ 1603 KBI_Einheit_Verbrauch_Gas 0;
BA_ "GenSigSendType" SG_ 1603 KBI_Einheit_Volumen 3;
BA_ "GenSigSwitchedByIgnition" SG_ 1603 KBI_Einheit_Volumen 0;
BA_ "GenSigSendType" SG_ 1603 KBI_MFA_v_Einheit_02 3;
BA_ "GenSigSwitchedByIgnition" SG_ 1603 KBI_MFA_v_Einheit_02 0;
BA_ "GenSigSendType" SG_ 1622 ELV_01_BZ 0;
BA_ "GenSigFuncType" SG_ 1622 ELV_01_BZ 1;
BA_ "GenSigSwitchedByIgnition" SG_ 1622 ELV_01_BZ 0;
BA_ "GenSigSendType" SG_ 1622 ELV_01_CRC 0;
BA_ "GenSigFuncType" SG_ 1622 ELV_01_CRC 2;
BA_ "GenSigSwitchedByIgnition" SG_ 1622 ELV_01_CRC 0;
BA_ "GenSigSendType" SG_ 1622 ELV_01_Sendestatus 5;
BA_ "GenSigSwitchedByIgnition" SG_ 1622 ELV_01_Sendestatus 0;
BA_ "GenSigSendType" SG_ 1622 ELV_Abbruch_Anf_Klemmenfreigabe 3;
BA_ "GenSigSwitchedByIgnition" SG_ 1622 ELV_Abbruch_Anf_Klemmenfreigabe 0;
BA_ "GenSigSendType" SG_ 1622 ELV_Anf_Klemme_15 3;
BA_ "GenSigSwitchedByIgnition" SG_ 1622 ELV_Anf_Klemme_15 0;
BA_ "GenSigSendType" SG_ 1622 ELV_Anf_Klemme_50 3;
BA_ "GenSigSwitchedByIgnition" SG_ 1622 ELV_Anf_Klemme_50 0;
BA_ "GenSigSendType" SG_ 1622 ELV_Anf_Klemme_S 3;
BA_ "GenSigSwitchedByIgnition" SG_ 1622 ELV_Anf_Klemme_S 0;
BA_ "GenSigSendType" SG_ 1622 ELV_Anlernmodus 3;
BA_ "GenSigSwitchedByIgnition" SG_ 1622 ELV_Anlernmodus 0;
BA_ "GenSigSendType" SG_ 1622 ELV_Entriegelt 3;
BA_ "GenSigSwitchedByIgnition" SG_ 1622 ELV_Entriegelt 0;
BA_ "GenSigSendType" SG_ 1622 ELV_Klemmenfreigabe 3;
BA_ "GenSigSwitchedByIgnition" SG_ 1622 ELV_Klemmenfreigabe 0;
BA_ "GenSigSendType" SG_ 1622 ELV_Lebenszustand 3;
BA_ "GenSigSwitchedByIgnition" SG_ 1622 ELV_Lebenszustand 0;
BA_ "GenSigSendType" SG_ 1622 ELV_LED_Gelb 3;
BA_ "GenSigSwitchedByIgnition" SG_ 1622 ELV_LED_Gelb 0;
BA_ "GenSigSendType" SG_ 1622 ELV_LED_Rot 3;
BA_ "GenSigSwitchedByIgnition" SG_ 1622 ELV_LED_Rot 0;
BA_ "GenSigSendType" SG_ 1622 ELV_P_verriegelt 3;
BA_ "GenSigSwitchedByIgnition" SG_ 1622 ELV_P_verriegelt 0;
BA_ "GenSigSendType" SG_ 1622 ELV_Txt_Bremse 3;
BA_ "GenSigSwitchedByIgnition" SG_ 1622 ELV_Txt_Bremse 0;
BA_ "GenSigSendType" SG_ 1622 ELV_Txt_Defekt 3;
BA_ "GenSigSwitchedByIgnition" SG_ 1622 ELV_Txt_Defekt 0;
BA_ "GenSigSendType" SG_ 1622 ELV_Txt_Kupplung 3;
BA_ "GenSigSwitchedByIgnition" SG_ 1622 ELV_Txt_Kupplung 0;
BA_ "GenSigSendType" SG_ 1622 ELV_Txt_Lkg_Bewegen 3;
BA_ "GenSigSwitchedByIgnition" SG_ 1622 ELV_Txt_Lkg_Bewegen 0;
BA_ "GenSigSendType" SG_ 1622 ELV_Txt_P_Gang 3;
BA_ "GenSigSwitchedByIgnition" SG_ 1622 ELV_Txt_P_Gang 0;
BA_ "GenSigSendType" SG_ 1622 ELV_Txt_Panikabschaltung 3;
BA_ "GenSigSwitchedByIgnition" SG_ 1622 ELV_Txt_Panikabschaltung 0;
BA_ "GenSigSendType" SG_ 1622 ELV_Txt_PN_Gang 3;
BA_ "GenSigSwitchedByIgnition" SG_ 1622 ELV_Txt_PN_Gang 0;
BA_ "GenSigSendType" SG_ 1622 ELV_Txt_Werkstatt 3;
BA_ "GenSigSwitchedByIgnition" SG_ 1622 ELV_Txt_Werkstatt 0;
BA_ "GenSigSendType" SG_ 1622 ELV_Verriegelt 3;
BA_ "GenSigSwitchedByIgnition" SG_ 1622 ELV_Verriegelt 0;
BA_ "GenSigSendType" SG_ 1622 ELV_ZAT_betaetigt 3;
BA_ "GenSigSwitchedByIgnition" SG_ 1622 ELV_ZAT_betaetigt 0;
BA_ "GenSigSendType" SG_ 115 EM1_HYB_12_BZ 0;
BA_ "GenSigFuncType" SG_ 115 EM1_HYB_12_BZ 1;
BA_ "GenSigSwitchedByIgnition" SG_ 115 EM1_HYB_12_BZ 0;
BA_ "GenSigSendType" SG_ 115 EM1_HYB_12_CRC 0;
BA_ "GenSigFuncType" SG_ 115 EM1_HYB_12_CRC 2;
BA_ "GenSigSwitchedByIgnition" SG_ 115 EM1_HYB_12_CRC 0;
BA_ "GenSigSendType" SG_ 115 EM1_IstDrehzahl 0;
BA_ "GenSigStartValue" SG_ 115 EM1_IstDrehzahl 32766;
BA_ "GenSigSwitchedByIgnition" SG_ 115 EM1_IstDrehzahl 0;
BA_ "Fehlerwert" SG_ 115 EM1_IstDrehzahl 32767;
BA_ "GenSigSendType" SG_ 115 EM1_IstDrehzahl_alt 0;
BA_ "GenSigStartValue" SG_ 115 EM1_IstDrehzahl_alt 32766;
BA_ "GenSigSwitchedByIgnition" SG_ 115 EM1_IstDrehzahl_alt 0;
BA_ "Fehlerwert" SG_ 115 EM1_IstDrehzahl_alt 32767;
BA_ "GenSigSendType" SG_ 115 EM1_IstMoment 0;
BA_ "GenSigStartValue" SG_ 115 EM1_IstMoment 4094;
BA_ "GenSigSwitchedByIgnition" SG_ 115 EM1_IstMoment 0;
BA_ "Fehlerwert" SG_ 115 EM1_IstMoment 4095;
BA_ "GenSigSendType" SG_ 115 EM1_MaxZul_Drehzahl 0;
BA_ "GenSigStartValue" SG_ 115 EM1_MaxZul_Drehzahl 254;
BA_ "GenSigSwitchedByIgnition" SG_ 115 EM1_MaxZul_Drehzahl 0;
BA_ "Fehlerwert" SG_ 115 EM1_MaxZul_Drehzahl 255;
BA_ "GenSigSendType" SG_ 260 EPB_01_BZ 0;
BA_ "GenSigFuncType" SG_ 260 EPB_01_BZ 1;
BA_ "GenSigSwitchedByIgnition" SG_ 260 EPB_01_BZ 0;
BA_ "GenSigSendType" SG_ 260 EPB_01_CRC 0;
BA_ "GenSigFuncType" SG_ 260 EPB_01_CRC 2;
BA_ "GenSigSwitchedByIgnition" SG_ 260 EPB_01_CRC 0;
BA_ "GenSigSendType" SG_ 260 EPB_DAA_Randbed_erf 0;
BA_ "GenSigSwitchedByIgnition" SG_ 260 EPB_DAA_Randbed_erf 0;
BA_ "GenSigSendType" SG_ 260 EPB_Fehlerstatus_02 3;
BA_ "GenSigSwitchedByIgnition" SG_ 260 EPB_Fehlerstatus_02 0;
BA_ "GenSigSendType" SG_ 260 EPB_Freig_Verzoeg_Anf 0;
BA_ "GenSigSwitchedByIgnition" SG_ 260 EPB_Freig_Verzoeg_Anf 0;
BA_ "GenSigSendType" SG_ 260 EPB_Pedalweg_Kuppl 3;
BA_ "GenSigSwitchedByIgnition" SG_ 260 EPB_Pedalweg_Kuppl 0;
BA_ "Fehlerwert" SG_ 260 EPB_Pedalweg_Kuppl 255;
BA_ "GenSigSendType" SG_ 260 EPB_QBit_Pedalweg_Kuppl 3;
BA_ "GenSigStartValue" SG_ 260 EPB_QBit_Pedalweg_Kuppl 1;
BA_ "GenSigSwitchedByIgnition" SG_ 260 EPB_QBit_Pedalweg_Kuppl 0;
BA_ "GenSigSendType" SG_ 260 EPB_QBit_Schalterpos 0;
BA_ "GenSigStartValue" SG_ 260 EPB_QBit_Schalterpos 1;
BA_ "GenSigSwitchedByIgnition" SG_ 260 EPB_QBit_Schalterpos 0;
BA_ "GenSigSendType" SG_ 260 EPB_Schalterposition 0;
BA_ "GenSigSwitchedByIgnition" SG_ 260 EPB_Schalterposition 0;
BA_ "Fehlerwert" SG_ 260 EPB_Schalterposition 3;
BA_ "GenSigSendType" SG_ 260 EPB_Spannkraft 0;
BA_ "GenSigStartValue" SG_ 260 EPB_Spannkraft 30;
BA_ "GenSigSwitchedByIgnition" SG_ 260 EPB_Spannkraft 0;
BA_ "Fehlerwert" SG_ 260 EPB_Spannkraft 31;
BA_ "GenSigSendType" SG_ 260 EPB_Status_02 3;
BA_ "GenSigStartValue" SG_ 260 EPB_Status_02 6;
BA_ "GenSigSwitchedByIgnition" SG_ 260 EPB_Status_02 0;
BA_ "GenSigSendType" SG_ 260 EPB_Verzoeg_Anf 0;
BA_ "GenSigStartValue" SG_ 260 EPB_Verzoeg_Anf 166;
BA_ "GenSigSwitchedByIgnition" SG_ 260 EPB_Verzoeg_Anf 0;
BA_ "GenSigSendType" SG_ 781 EPB_Akustik 0;
BA_ "GenSigSwitchedByIgnition" SG_ 781 EPB_Akustik 0;
BA_ "GenSigSendType" SG_ 781 EPB_Autoholdlampe 3;
BA_ "GenSigSwitchedByIgnition" SG_ 781 EPB_Autoholdlampe 0;
BA_ "GenSigSendType" SG_ 781 EPB_Bremsbelag_Warn 0;
BA_ "GenSigSwitchedByIgnition" SG_ 781 EPB_Bremsbelag_Warn 0;
BA_ "GenSigSendType" SG_ 781 EPB_Fehlerlampe_BKL 0;
BA_ "GenSigSwitchedByIgnition" SG_ 781 EPB_Fehlerlampe_BKL 0;
BA_ "GenSigSendType" SG_ 781 EPB_Fehlerlampe_Gelb 0;
BA_ "GenSigSwitchedByIgnition" SG_ 781 EPB_Fehlerlampe_Gelb 0;
BA_ "GenSigSendType" SG_ 781 EPB_Fehlermeldungen 3;
BA_ "GenSigSwitchedByIgnition" SG_ 781 EPB_Fehlermeldungen 0;
BA_ "GenSigSendType" SG_ 781 EPB_Funktionslampe 3;
BA_ "GenSigSwitchedByIgnition" SG_ 781 EPB_Funktionslampe 0;
BA_ "GenSigSendType" SG_ 781 EPB_Texte 3;
BA_ "GenSigSwitchedByIgnition" SG_ 781 EPB_Texte 0;
BA_ "GenSigSendType" SG_ 259 ESP_03_BZ 0;
BA_ "GenSigFuncType" SG_ 259 ESP_03_BZ 1;
BA_ "GenSigSwitchedByIgnition" SG_ 259 ESP_03_BZ 0;
BA_ "GenSigSendType" SG_ 259 ESP_03_CRC 0;
BA_ "GenSigFuncType" SG_ 259 ESP_03_CRC 2;
BA_ "GenSigSwitchedByIgnition" SG_ 259 ESP_03_CRC 0;
BA_ "GenSigSendType" SG_ 259 ESP_HL_FR 0;
BA_ "GenSigSwitchedByIgnition" SG_ 259 ESP_HL_FR 0;
BA_ "GenSigSendType" SG_ 259 ESP_HL_Radgeschw 0;
BA_ "GenSigStartValue" SG_ 259 ESP_HL_Radgeschw 4094;
BA_ "GenSigSwitchedByIgnition" SG_ 259 ESP_HL_Radgeschw 0;
BA_ "Fehlerwert" SG_ 259 ESP_HL_Radgeschw 4095;
BA_ "GenSigSendType" SG_ 259 ESP_HR_FR 0;
BA_ "GenSigSwitchedByIgnition" SG_ 259 ESP_HR_FR 0;
BA_ "GenSigSendType" SG_ 259 ESP_HR_Radgeschw 0;
BA_ "GenSigStartValue" SG_ 259 ESP_HR_Radgeschw 4094;
BA_ "GenSigSwitchedByIgnition" SG_ 259 ESP_HR_Radgeschw 0;
BA_ "Fehlerwert" SG_ 259 ESP_HR_Radgeschw 4095;
BA_ "GenSigSendType" SG_ 259 ESP_VL_FR 0;
BA_ "GenSigSwitchedByIgnition" SG_ 259 ESP_VL_FR 0;
BA_ "GenSigSendType" SG_ 259 ESP_VL_Radgeschw 0;
BA_ "GenSigStartValue" SG_ 259 ESP_VL_Radgeschw 4094;
BA_ "GenSigSwitchedByIgnition" SG_ 259 ESP_VL_Radgeschw 0;
BA_ "Fehlerwert" SG_ 259 ESP_VL_Radgeschw 4095;
BA_ "GenSigSendType" SG_ 259 ESP_VR_FR 0;
BA_ "GenSigSwitchedByIgnition" SG_ 259 ESP_VR_FR 0;
BA_ "GenSigSendType" SG_ 259 ESP_VR_Radgeschw 0;
BA_ "GenSigStartValue" SG_ 259 ESP_VR_Radgeschw 4094;
BA_ "GenSigSwitchedByIgnition" SG_ 259 ESP_VR_Radgeschw 0;
BA_ "Fehlerwert" SG_ 259 ESP_VR_Radgeschw 4095;
BA_ "GenSigSendType" SG_ 262 ECD_Fehler 0;
BA_ "GenSigSwitchedByIgnition" SG_ 262 ECD_Fehler 0;
BA_ "GenSigSendType" SG_ 262 ECD_nicht_verfuegbar 0;
BA_ "GenSigStartValue" SG_ 262 ECD_nicht_verfuegbar 1;
BA_ "GenSigSwitchedByIgnition" SG_ 262 ECD_nicht_verfuegbar 0;
BA_ "GenSigSendType" SG_ 262 ESC_Bremslicht 0;
BA_ "GenSigSwitchedByIgnition" SG_ 262 ESC_Bremslicht 0;
BA_ "GenSigSendType" SG_ 262 ESP_05_BZ 0;
BA_ "GenSigFuncType" SG_ 262 ESP_05_BZ 1;
BA_ "GenSigSwitchedByIgnition" SG_ 262 ESP_05_BZ 0;
BA_ "GenSigSendType" SG_ 262 ESP_05_CRC 0;
BA_ "GenSigFuncType" SG_ 262 ESP_05_CRC 2;
BA_ "GenSigSwitchedByIgnition" SG_ 262 ESP_05_CRC 0;
BA_ "GenSigSendType" SG_ 262 ESP_Anforderung_EPB 0;
BA_ "GenSigSwitchedByIgnition" SG_ 262 ESP_Anforderung_EPB 0;
BA_ "GenSigSendType" SG_ 262 ESP_Autohold_aktiv 0;
BA_ "GenSigSwitchedByIgnition" SG_ 262 ESP_Autohold_aktiv 0;
BA_ "GenSigSendType" SG_ 262 ESP_Autohold_Standby 0;
BA_ "GenSigSwitchedByIgnition" SG_ 262 ESP_Autohold_Standby 0;
BA_ "GenSigSendType" SG_ 262 ESP_BKV_Unterdruck 0;
BA_ "GenSigStartValue" SG_ 262 ESP_BKV_Unterdruck 254;
BA_ "GenSigSwitchedByIgnition" SG_ 262 ESP_BKV_Unterdruck 0;
BA_ "Fehlerwert" SG_ 262 ESP_BKV_Unterdruck 255;
BA_ "GenSigSendType" SG_ 262 ESP_Bremsdruck 0;
BA_ "GenSigStartValue" SG_ 262 ESP_Bremsdruck 100;
BA_ "GenSigSwitchedByIgnition" SG_ 262 ESP_Bremsdruck 0;
BA_ "Fehlerwert" SG_ 262 ESP_Bremsdruck 1023;
BA_ "GenSigSendType" SG_ 262 ESP_Eingr_HL 0;
BA_ "GenSigSwitchedByIgnition" SG_ 262 ESP_Eingr_HL 0;
BA_ "GenSigSendType" SG_ 262 ESP_Eingr_HR 0;
BA_ "GenSigSwitchedByIgnition" SG_ 262 ESP_Eingr_HR 0;
BA_ "GenSigSendType" SG_ 262 ESP_Eingr_VL 0;
BA_ "GenSigSwitchedByIgnition" SG_ 262 ESP_Eingr_VL 0;
BA_ "GenSigSendType" SG_ 262 ESP_Eingr_VR 0;
BA_ "GenSigSwitchedByIgnition" SG_ 262 ESP_Eingr_VR 0;
BA_ "GenSigSendType" SG_ 262 ESP_Fahrer_bremst 0;
BA_ "GenSigSwitchedByIgnition" SG_ 262 ESP_Fahrer_bremst 0;
BA_ "GenSigSendType" SG_ 262 ESP_FStatus_Anfahrhilfe 0;
BA_ "GenSigSwitchedByIgnition" SG_ 262 ESP_FStatus_Anfahrhilfe 0;
BA_ "Fehlerwert" SG_ 262 ESP_FStatus_Anfahrhilfe 1;
BA_ "GenSigSendType" SG_ 262 ESP_HBA_aktiv 0;
BA_ "GenSigSwitchedByIgnition" SG_ 262 ESP_HBA_aktiv 0;
BA_ "GenSigSendType" SG_ 262 ESP_HDC_aktiv 0;
BA_ "GenSigSwitchedByIgnition" SG_ 262 ESP_HDC_aktiv 0;
BA_ "GenSigSendType" SG_ 262 ESP_HDC_Standby 3;
BA_ "GenSigSwitchedByIgnition" SG_ 262 ESP_HDC_Standby 0;
BA_ "GenSigSendType" SG_ 262 ESP_Lenkeingriff_ADS 0;
BA_ "GenSigSwitchedByIgnition" SG_ 262 ESP_Lenkeingriff_ADS 0;
BA_ "GenSigSendType" SG_ 262 ESP_Prefill_ausgeloest 0;
BA_ "GenSigSwitchedByIgnition" SG_ 262 ESP_Prefill_ausgeloest 0;
BA_ "GenSigSendType" SG_ 262 ESP_QBit_Bremsdruck 0;
BA_ "GenSigStartValue" SG_ 262 ESP_QBit_Bremsdruck 1;
BA_ "GenSigSwitchedByIgnition" SG_ 262 ESP_QBit_Bremsdruck 0;
BA_ "GenSigSendType" SG_ 262 ESP_QBit_Fahrer_bremst 0;
BA_ "GenSigStartValue" SG_ 262 ESP_QBit_Fahrer_bremst 1;
BA_ "GenSigSwitchedByIgnition" SG_ 262 ESP_QBit_Fahrer_bremst 0;
BA_ "GenSigSendType" SG_ 262 ESP_Rueckwaertsfahrt_erkannt 0;
BA_ "GenSigSwitchedByIgnition" SG_ 262 ESP_Rueckwaertsfahrt_erkannt 0;
BA_ "GenSigSendType" SG_ 262 ESP_Schwelle_Unterdruck 0;
BA_ "GenSigSwitchedByIgnition" SG_ 262 ESP_Schwelle_Unterdruck 0;
BA_ "GenSigSendType" SG_ 262 ESP_StartStopp_Info 0;
BA_ "GenSigSwitchedByIgnition" SG_ 262 ESP_StartStopp_Info 0;
BA_ "GenSigSendType" SG_ 262 ESP_Status_Anfahrhilfe 0;
BA_ "GenSigSwitchedByIgnition" SG_ 262 ESP_Status_Anfahrhilfe 0;
BA_ "GenSigSendType" SG_ 262 ESP_Status_Bremsdruck 0;
BA_ "GenSigSwitchedByIgnition" SG_ 262 ESP_Status_Bremsdruck 0;
BA_ "GenSigSendType" SG_ 262 ESP_Status_Bremsentemp 0;
BA_ "GenSigSwitchedByIgnition" SG_ 262 ESP_Status_Bremsentemp 0;
BA_ "GenSigSendType" SG_ 262 ESP_Verz_EPB_aktiv 0;
BA_ "GenSigSwitchedByIgnition" SG_ 262 ESP_Verz_EPB_aktiv 0;
BA_ "GenSigSendType" SG_ 262 ESP_Verzoeg_EPB_verf 0;
BA_ "GenSigSwitchedByIgnition" SG_ 262 ESP_Verzoeg_EPB_verf 0;
BA_ "GenSigSendType" SG_ 914 ESC_cAQP_Trigger 0;
BA_ "GenSigSendType" SG_ 914 ESP_07_BZ 0;
BA_ "GenSigFuncType" SG_ 914 ESP_07_BZ 1;
BA_ "GenSigSwitchedByIgnition" SG_ 914 ESP_07_BZ 0;
BA_ "GenSigSendType" SG_ 914 ESP_07_CRC 0;
BA_ "GenSigFuncType" SG_ 914 ESP_07_CRC 2;
BA_ "GenSigSwitchedByIgnition" SG_ 914 ESP_07_CRC 0;
BA_ "GenSigSendType" SG_ 914 ESP_Allrad_Antrieb 0;
BA_ "GenSigFuncType" SG_ 914 ESP_Allrad_Antrieb 8;
BA_ "GenSigSwitchedByIgnition" SG_ 914 ESP_Allrad_Antrieb 0;
BA_ "GenSigSendType" SG_ 914 ESP_Codierung_ADS 0;
BA_ "GenSigFuncType" SG_ 914 ESP_Codierung_ADS 8;
BA_ "GenSigSwitchedByIgnition" SG_ 914 ESP_Codierung_ADS 0;
BA_ "GenSigSendType" SG_ 914 ESP_MKB_ausloesbar 0;
BA_ "GenSigSwitchedByIgnition" SG_ 914 ESP_MKB_ausloesbar 0;
BA_ "GenSigSendType" SG_ 914 ESP_nachtr_Stopp_Anf 0;
BA_ "GenSigSwitchedByIgnition" SG_ 914 ESP_nachtr_Stopp_Anf 0;
BA_ "GenSigSendType" SG_ 914 ESP_OBD_Status 0;
BA_ "GenSigSwitchedByIgnition" SG_ 914 ESP_OBD_Status 0;
BA_ "GenSigSendType" SG_ 914 ESP_Offroad_Modus 0;
BA_ "GenSigSwitchedByIgnition" SG_ 914 ESP_Offroad_Modus 0;
BA_ "GenSigSendType" SG_ 914 ESP_Qualifizierung_Antriebsart 0;
BA_ "GenSigFuncType" SG_ 914 ESP_Qualifizierung_Antriebsart 8;
BA_ "GenSigSwitchedByIgnition" SG_ 914 ESP_Qualifizierung_Antriebsart 0;
BA_ "GenSigSendType" SG_ 914 ESP_Rollenmodus_Deaktivieren 3;
BA_ "GenSigSwitchedByIgnition" SG_ 914 ESP_Rollenmodus_Deaktivieren 0;
BA_ "GenSigSendType" SG_ 914 ESP_RTA_HL 0;
BA_ "GenSigStartValue" SG_ 914 ESP_RTA_HL 254;
BA_ "GenSigSwitchedByIgnition" SG_ 914 ESP_RTA_HL 0;
BA_ "Fehlerwert" SG_ 914 ESP_RTA_HL 255;
BA_ "GenSigSendType" SG_ 914 ESP_RTA_HR 0;
BA_ "GenSigStartValue" SG_ 914 ESP_RTA_HR 254;
BA_ "GenSigSwitchedByIgnition" SG_ 914 ESP_RTA_HR 0;
BA_ "Fehlerwert" SG_ 914 ESP_RTA_HR 255;
BA_ "GenSigSendType" SG_ 914 ESP_RTA_VR 0;
BA_ "GenSigStartValue" SG_ 914 ESP_RTA_VR 254;
BA_ "GenSigSwitchedByIgnition" SG_ 914 ESP_RTA_VR 0;
BA_ "Fehlerwert" SG_ 914 ESP_RTA_VR 255;
BA_ "GenSigSendType" SG_ 914 ESP_Stat_FallBack_eBKV 0;
BA_ "GenSigSwitchedByIgnition" SG_ 914 ESP_Stat_FallBack_eBKV 0;
BA_ "GenSigSendType" SG_ 914 OBD_Fehler_Radsensor_HL 0;
BA_ "GenSigSwitchedByIgnition" SG_ 914 OBD_Fehler_Radsensor_HL 0;
BA_ "GenSigSendType" SG_ 914 OBD_Fehler_Radsensor_HR 0;
BA_ "GenSigSwitchedByIgnition" SG_ 914 OBD_Fehler_Radsensor_HR 0;
BA_ "GenSigSendType" SG_ 914 OBD_Fehler_Radsensor_VL 0;
BA_ "GenSigSwitchedByIgnition" SG_ 914 OBD_Fehler_Radsensor_VL 0;
BA_ "GenSigSendType" SG_ 914 OBD_Fehler_Radsensor_VR 0;
BA_ "GenSigSwitchedByIgnition" SG_ 914 OBD_Fehler_Radsensor_VR 0;
BA_ "GenSigSendType" SG_ 278 ESP_10_BZ 0;
BA_ "GenSigFuncType" SG_ 278 ESP_10_BZ 1;
BA_ "GenSigSwitchedByIgnition" SG_ 278 ESP_10_BZ 0;
BA_ "GenSigSendType" SG_ 278 ESP_10_CRC 0;
BA_ "GenSigFuncType" SG_ 278 ESP_10_CRC 2;
BA_ "GenSigSwitchedByIgnition" SG_ 278 ESP_10_CRC 0;
BA_ "GenSigSendType" SG_ 278 ESP_HL_Fahrtrichtung 0;
BA_ "GenSigStartValue" SG_ 278 ESP_HL_Fahrtrichtung 2;
BA_ "GenSigSwitchedByIgnition" SG_ 278 ESP_HL_Fahrtrichtung 0;
BA_ "GenSigSendType" SG_ 278 ESP_HR_Fahrtrichtung 0;
BA_ "GenSigStartValue" SG_ 278 ESP_HR_Fahrtrichtung 2;
BA_ "GenSigSwitchedByIgnition" SG_ 278 ESP_HR_Fahrtrichtung 0;
BA_ "GenSigSendType" SG_ 278 ESP_QBit_Wegimpuls_HL 0;
BA_ "GenSigStartValue" SG_ 278 ESP_QBit_Wegimpuls_HL 1;
BA_ "GenSigSwitchedByIgnition" SG_ 278 ESP_QBit_Wegimpuls_HL 0;
BA_ "GenSigSendType" SG_ 278 ESP_QBit_Wegimpuls_HR 0;
BA_ "GenSigStartValue" SG_ 278 ESP_QBit_Wegimpuls_HR 1;
BA_ "GenSigSwitchedByIgnition" SG_ 278 ESP_QBit_Wegimpuls_HR 0;
BA_ "GenSigSendType" SG_ 278 ESP_QBit_Wegimpuls_VL 0;
BA_ "GenSigStartValue" SG_ 278 ESP_QBit_Wegimpuls_VL 1;
BA_ "GenSigSwitchedByIgnition" SG_ 278 ESP_QBit_Wegimpuls_VL 0;
BA_ "GenSigSendType" SG_ 278 ESP_QBit_Wegimpuls_VR 0;
BA_ "GenSigStartValue" SG_ 278 ESP_QBit_Wegimpuls_VR 1;
BA_ "GenSigSwitchedByIgnition" SG_ 278 ESP_QBit_Wegimpuls_VR 0;
BA_ "GenSigSendType" SG_ 278 ESP_VL_Fahrtrichtung 0;
BA_ "GenSigStartValue" SG_ 278 ESP_VL_Fahrtrichtung 2;
BA_ "GenSigSwitchedByIgnition" SG_ 278 ESP_VL_Fahrtrichtung 0;
BA_ "GenSigSendType" SG_ 278 ESP_VR_Fahrtrichtung 0;
BA_ "GenSigStartValue" SG_ 278 ESP_VR_Fahrtrichtung 2;
BA_ "GenSigSwitchedByIgnition" SG_ 278 ESP_VR_Fahrtrichtung 0;
BA_ "GenSigSendType" SG_ 278 ESP_Wegimpuls_HL 0;
BA_ "GenSigStartValue" SG_ 278 ESP_Wegimpuls_HL 1021;
BA_ "GenSigSwitchedByIgnition" SG_ 278 ESP_Wegimpuls_HL 0;
BA_ "Fehlerwert" SG_ 278 ESP_Wegimpuls_HL 1023;
BA_ "GenSigSendType" SG_ 278 ESP_Wegimpuls_HR 0;
BA_ "GenSigStartValue" SG_ 278 ESP_Wegimpuls_HR 1021;
BA_ "GenSigSwitchedByIgnition" SG_ 278 ESP_Wegimpuls_HR 0;
BA_ "Fehlerwert" SG_ 278 ESP_Wegimpuls_HR 1023;
BA_ "GenSigSendType" SG_ 278 ESP_Wegimpuls_VL 0;
BA_ "GenSigStartValue" SG_ 278 ESP_Wegimpuls_VL 1021;
BA_ "GenSigSwitchedByIgnition" SG_ 278 ESP_Wegimpuls_VL 0;
BA_ "Fehlerwert" SG_ 278 ESP_Wegimpuls_VL 1023;
BA_ "GenSigSendType" SG_ 278 ESP_Wegimpuls_VR 0;
BA_ "GenSigStartValue" SG_ 278 ESP_Wegimpuls_VR 1021;
BA_ "GenSigSwitchedByIgnition" SG_ 278 ESP_Wegimpuls_VR 0;
BA_ "Fehlerwert" SG_ 278 ESP_Wegimpuls_VR 1023;
BA_ "GenSigSendType" SG_ 418 ESP_15_BZ 0;
BA_ "GenSigFuncType" SG_ 418 ESP_15_BZ 1;
BA_ "GenSigSwitchedByIgnition" SG_ 418 ESP_15_BZ 0;
BA_ "GenSigSendType" SG_ 418 ESP_15_CRC 0;
BA_ "GenSigFuncType" SG_ 418 ESP_15_CRC 2;
BA_ "GenSigSwitchedByIgnition" SG_ 418 ESP_15_CRC 0;
BA_ "GenSigSendType" SG_ 418 ESP_Haltemoment 0;
BA_ "GenSigStartValue" SG_ 418 ESP_Haltemoment 1022;
BA_ "GenSigSwitchedByIgnition" SG_ 418 ESP_Haltemoment 0;
BA_ "Fehlerwert" SG_ 418 ESP_Haltemoment 1023;
BA_ "GenSigSendType" SG_ 418 ESP_Index_Haltemoment 0;
BA_ "GenSigSwitchedByIgnition" SG_ 418 ESP_Index_Haltemoment 0;
BA_ "GenSigSendType" SG_ 418 HMS_aktives_System 3;
BA_ "GenSigSwitchedByIgnition" SG_ 418 HMS_aktives_System 0;
BA_ "GenSigSendType" SG_ 418 HMS_Anforderung_GE 0;
BA_ "GenSigSwitchedByIgnition" SG_ 418 HMS_Anforderung_GE 0;
BA_ "GenSigSendType" SG_ 418 HMS_Fehlerstatus 3;
BA_ "GenSigSwitchedByIgnition" SG_ 418 HMS_Fehlerstatus 0;
BA_ "GenSigSendType" SG_ 418 HMS_halten_nicht_verfuegbar 0;
BA_ "GenSigSwitchedByIgnition" SG_ 418 HMS_halten_nicht_verfuegbar 0;
BA_ "GenSigSendType" SG_ 418 HMS_Konsistenz_ACC 0;
BA_ "GenSigSwitchedByIgnition" SG_ 418 HMS_Konsistenz_ACC 0;
BA_ "GenSigSendType" SG_ 418 HMS_Konsistenz_GE 0;
BA_ "GenSigSwitchedByIgnition" SG_ 418 HMS_Konsistenz_GE 0;
BA_ "GenSigSendType" SG_ 418 HMS_Konsistenz_HVLM 3;
BA_ "GenSigSwitchedByIgnition" SG_ 418 HMS_Konsistenz_HVLM 0;
BA_ "GenSigSendType" SG_ 418 HMS_Konsistenz_IPA 3;
BA_ "GenSigSwitchedByIgnition" SG_ 418 HMS_Konsistenz_IPA 0;
BA_ "GenSigSendType" SG_ 418 HMS_Konsistenz_MO 0;
BA_ "GenSigSwitchedByIgnition" SG_ 418 HMS_Konsistenz_MO 0;
BA_ "GenSigSendType" SG_ 418 HMS_Konsistenz_STA 0;
BA_ "GenSigSwitchedByIgnition" SG_ 418 HMS_Konsistenz_STA 0;
BA_ "GenSigSendType" SG_ 418 HMS_Notstopp_Status 0;
BA_ "GenSigSwitchedByIgnition" SG_ 418 HMS_Notstopp_Status 0;
BA_ "GenSigSendType" SG_ 418 HMS_P_beibehalten_GE 0;
BA_ "GenSigStartValue" SG_ 418 HMS_P_beibehalten_GE 2;
BA_ "GenSigSwitchedByIgnition" SG_ 418 HMS_P_beibehalten_GE 0;
BA_ "Fehlerwert" SG_ 418 HMS_P_beibehalten_GE 3;
BA_ "GenSigSendType" SG_ 418 HMS_parken_nicht_verfuegbar 0;
BA_ "GenSigSwitchedByIgnition" SG_ 418 HMS_parken_nicht_verfuegbar 0;
BA_ "GenSigSendType" SG_ 418 HMS_Stillstand 3;
BA_ "GenSigStartValue" SG_ 418 HMS_Stillstand 6;
BA_ "GenSigSwitchedByIgnition" SG_ 418 HMS_Stillstand 0;
BA_ "Fehlerwert" SG_ 418 HMS_Stillstand 7;
BA_ "GenSigSendType" SG_ 418 HMS_Systemstatus 3;
BA_ "GenSigStartValue" SG_ 418 HMS_Systemstatus 14;
BA_ "GenSigSwitchedByIgnition" SG_ 418 HMS_Systemstatus 0;
BA_ "Fehlerwert" SG_ 418 HMS_Systemstatus 15;
BA_ "GenSigSendType" SG_ 418 NL_PRIM_STP_01_Status 0;
BA_ "GenSigSwitchedByIgnition" SG_ 418 NL_PRIM_STP_01_Status 0;
BA_ "GenSigSendType" SG_ 418 VMM_Warnblinken 3;
BA_ "GenSigSwitchedByIgnition" SG_ 418 VMM_Warnblinken 0;
BA_ "GenSigSendType" SG_ 418 VZM_Status 0;
BA_ "GenSigSwitchedByIgnition" SG_ 418 VZM_Status 0;
BA_ "Fehlerwert" SG_ 418 VZM_Status 4;
BA_ "GenSigSendType" SG_ 1629 BR_QBit_Reifenumfang 0;
BA_ "GenSigStartValue" SG_ 1629 BR_QBit_Reifenumfang 1;
BA_ "GenSigSwitchedByIgnition" SG_ 1629 BR_QBit_Reifenumfang 0;
BA_ "GenSigSendType" SG_ 1629 BR_Reifenumfang 0;
BA_ "GenSigSwitchedByIgnition" SG_ 1629 BR_Reifenumfang 0;
BA_ "GenSigSendType" SG_ 1629 BR_Systemart 0;
BA_ "GenSigFuncType" SG_ 1629 BR_Systemart 8;
BA_ "GenSigSwitchedByIgnition" SG_ 1629 BR_Systemart 0;
BA_ "GenSigSendType" SG_ 1629 ESP_20_BZ 0;
BA_ "GenSigFuncType" SG_ 1629 ESP_20_BZ 1;
BA_ "GenSigSwitchedByIgnition" SG_ 1629 ESP_20_BZ 0;
BA_ "GenSigSendType" SG_ 1629 ESP_20_CRC 0;
BA_ "GenSigFuncType" SG_ 1629 ESP_20_CRC 2;
BA_ "GenSigSwitchedByIgnition" SG_ 1629 ESP_20_CRC 0;
BA_ "GenSigSendType" SG_ 1629 ESP_Charisma_FahrPr 0;
BA_ "GenSigSwitchedByIgnition" SG_ 1629 ESP_Charisma_FahrPr 0;
BA_ "GenSigSendType" SG_ 1629 ESP_Charisma_Status 0;
BA_ "GenSigSwitchedByIgnition" SG_ 1629 ESP_Charisma_Status 0;
BA_ "GenSigSendType" SG_ 1629 ESP_Dachrelingsensor 0;
BA_ "GenSigSwitchedByIgnition" SG_ 1629 ESP_Dachrelingsensor 0;
BA_ "Fehlerwert" SG_ 1629 ESP_Dachrelingsensor 3;
BA_ "GenSigSendType" SG_ 1629 ESP_SpannungsAnf_02 0;
BA_ "GenSigSwitchedByIgnition" SG_ 1629 ESP_SpannungsAnf_02 0;
BA_ "GenSigSendType" SG_ 1629 ESP_Stoppverbot_Anz_01 0;
BA_ "GenSigSwitchedByIgnition" SG_ 1629 ESP_Stoppverbot_Anz_01 0;
BA_ "GenSigSendType" SG_ 1629 ESP_Stoppverbot_Anz_02 0;
BA_ "GenSigSwitchedByIgnition" SG_ 1629 ESP_Stoppverbot_Anz_02 0;
BA_ "GenSigSendType" SG_ 1629 ESP_Stoppverbot_Anz_03 0;
BA_ "GenSigSwitchedByIgnition" SG_ 1629 ESP_Stoppverbot_Anz_03 0;
BA_ "GenSigSendType" SG_ 1629 ESP_Stoppverbot_Anz_04 0;
BA_ "GenSigSwitchedByIgnition" SG_ 1629 ESP_Stoppverbot_Anz_04 0;
BA_ "GenSigSendType" SG_ 1629 ESP_Stoppverbot_Anz_05 0;
BA_ "GenSigSwitchedByIgnition" SG_ 1629 ESP_Stoppverbot_Anz_05 0;
BA_ "GenSigSendType" SG_ 1629 ESP_Stoppverbot_Anz_06 0;
BA_ "GenSigSwitchedByIgnition" SG_ 1629 ESP_Stoppverbot_Anz_06 0;
BA_ "GenSigSendType" SG_ 1629 ESP_Stoppverbot_Anz_07 0;
BA_ "GenSigSwitchedByIgnition" SG_ 1629 ESP_Stoppverbot_Anz_07 0;
BA_ "GenSigSendType" SG_ 1629 ESP_Stoppverbot_Anz_08 0;
BA_ "GenSigSwitchedByIgnition" SG_ 1629 ESP_Stoppverbot_Anz_08 0;
BA_ "GenSigSendType" SG_ 1629 ESP_Stoppverbot_Anz_Std 0;
BA_ "GenSigSwitchedByIgnition" SG_ 1629 ESP_Stoppverbot_Anz_Std 0;
BA_ "GenSigSendType" SG_ 1629 ESP_Wiederstart_Anz_01 0;
BA_ "GenSigSwitchedByIgnition" SG_ 1629 ESP_Wiederstart_Anz_01 0;
BA_ "GenSigSendType" SG_ 1629 ESP_Wiederstart_Anz_02 0;
BA_ "GenSigSwitchedByIgnition" SG_ 1629 ESP_Wiederstart_Anz_02 0;
BA_ "GenSigSendType" SG_ 1629 ESP_Wiederstart_Anz_03 0;
BA_ "GenSigSwitchedByIgnition" SG_ 1629 ESP_Wiederstart_Anz_03 0;
BA_ "GenSigSendType" SG_ 1629 ESP_Wiederstart_Anz_04 0;
BA_ "GenSigSwitchedByIgnition" SG_ 1629 ESP_Wiederstart_Anz_04 0;
BA_ "GenSigSendType" SG_ 1629 ESP_Zaehnezahl 0;
BA_ "GenSigFuncType" SG_ 1629 ESP_Zaehnezahl 8;
BA_ "GenSigSwitchedByIgnition" SG_ 1629 ESP_Zaehnezahl 0;
BA_ "GenSigSendType" SG_ 1629 HDC_Charisma_FahrPr 0;
BA_ "GenSigSwitchedByIgnition" SG_ 1629 HDC_Charisma_FahrPr 0;
BA_ "GenSigSendType" SG_ 1629 HDC_Charisma_Status 0;
BA_ "GenSigSwitchedByIgnition" SG_ 1629 HDC_Charisma_Status 0;
BA_ "GenSigSendType" SG_ 253 ABS_Bremsung 0;
BA_ "GenSigSwitchedByIgnition" SG_ 253 ABS_Bremsung 0;
BA_ "GenSigSendType" SG_ 253 ASR_Anf 0;
BA_ "GenSigSwitchedByIgnition" SG_ 253 ASR_Anf 0;
BA_ "GenSigSendType" SG_ 253 ASR_Schalteingriff 0;
BA_ "GenSigSwitchedByIgnition" SG_ 253 ASR_Schalteingriff 0;
BA_ "GenSigSendType" SG_ 253 ASR_Tastung_passiv 0;
BA_ "GenSigSwitchedByIgnition" SG_ 253 ASR_Tastung_passiv 0;
BA_ "GenSigSendType" SG_ 253 BR_Eingriffsmoment 0;
BA_ "GenSigStartValue" SG_ 253 BR_Eingriffsmoment 1022;
BA_ "GenSigSwitchedByIgnition" SG_ 253 BR_Eingriffsmoment 0;
BA_ "Fehlerwert" SG_ 253 BR_Eingriffsmoment 1023;
BA_ "GenSigSendType" SG_ 253 EBV_Eingriff 0;
BA_ "GenSigSwitchedByIgnition" SG_ 253 EBV_Eingriff 0;
BA_ "GenSigSendType" SG_ 253 EDS_Eingriff 0;
BA_ "GenSigSwitchedByIgnition" SG_ 253 EDS_Eingriff 0;
BA_ "GenSigSendType" SG_ 253 ESC_Neutralschaltung 0;
BA_ "GenSigSwitchedByIgnition" SG_ 253 ESC_Neutralschaltung 0;
BA_ "GenSigSendType" SG_ 253 ESC_v_Signal_Qualifier_High_Low 0;
BA_ "GenSigStartValue" SG_ 253 ESC_v_Signal_Qualifier_High_Low 6;
BA_ "GenSigSwitchedByIgnition" SG_ 253 ESC_v_Signal_Qualifier_High_Low 0;
BA_ "Fehlerwert" SG_ 253 ESC_v_Signal_Qualifier_High_Low 7;
BA_ "GenSigSendType" SG_ 253 ESP_21_BZ 0;
BA_ "GenSigFuncType" SG_ 253 ESP_21_BZ 1;
BA_ "GenSigSwitchedByIgnition" SG_ 253 ESP_21_BZ 0;
BA_ "GenSigSendType" SG_ 253 ESP_21_CRC 0;
BA_ "GenSigFuncType" SG_ 253 ESP_21_CRC 2;
BA_ "GenSigSwitchedByIgnition" SG_ 253 ESP_21_CRC 0;
BA_ "GenSigSendType" SG_ 253 ESP_ASP 0;
BA_ "GenSigSwitchedByIgnition" SG_ 253 ESP_ASP 0;
BA_ "GenSigSendType" SG_ 253 ESP_Diagnose 0;
BA_ "GenSigSwitchedByIgnition" SG_ 253 ESP_Diagnose 0;
BA_ "GenSigSendType" SG_ 253 ESP_Eingriff 0;
BA_ "GenSigSwitchedByIgnition" SG_ 253 ESP_Eingriff 0;
BA_ "GenSigSendType" SG_ 253 ESP_QBit_v_Signal 0;
BA_ "GenSigStartValue" SG_ 253 ESP_QBit_v_Signal 1;
BA_ "GenSigSwitchedByIgnition" SG_ 253 ESP_QBit_v_Signal 0;
BA_ "GenSigSendType" SG_ 253 ESP_Systemstatus 0;
BA_ "GenSigSwitchedByIgnition" SG_ 253 ESP_Systemstatus 0;
BA_ "GenSigSendType" SG_ 253 ESP_Tastung_passiv 0;
BA_ "GenSigSwitchedByIgnition" SG_ 253 ESP_Tastung_passiv 0;
BA_ "GenSigSendType" SG_ 253 ESP_v_Signal 0;
BA_ "GenSigStartValue" SG_ 253 ESP_v_Signal 65534;
BA_ "GenSigSwitchedByIgnition" SG_ 253 ESP_v_Signal 0;
BA_ "Fehlerwert" SG_ 253 ESP_v_Signal 65535;
BA_ "GenSigMissingSourceValue" SG_ 253 ESP_v_Signal 65534;
BA_ "GenSigSendType" SG_ 253 ESP_Vorsteuerung 0;
BA_ "GenSigSwitchedByIgnition" SG_ 253 ESP_Vorsteuerung 0;
BA_ "GenSigSendType" SG_ 253 MSR_Anf 0;
BA_ "GenSigSwitchedByIgnition" SG_ 253 MSR_Anf 0;
BA_ "GenSigSendType" SG_ 253 MSR_verfuegbar 0;
BA_ "GenSigStartValue" SG_ 253 MSR_verfuegbar 1;
BA_ "GenSigSwitchedByIgnition" SG_ 253 MSR_verfuegbar 0;
BA_ "GenSigSendType" SG_ 253 OBD_QBit_Schlechtweg 0;
BA_ "GenSigStartValue" SG_ 253 OBD_QBit_Schlechtweg 1;
BA_ "GenSigSwitchedByIgnition" SG_ 253 OBD_QBit_Schlechtweg 0;
BA_ "GenSigSendType" SG_ 253 OBD_Schlechtweg 0;
BA_ "GenSigSwitchedByIgnition" SG_ 253 OBD_Schlechtweg 0;
BA_ "GenSigSendType" SG_ 239 ESP_22_BZ 0;
BA_ "GenSigFuncType" SG_ 239 ESP_22_BZ 1;
BA_ "GenSigSwitchedByIgnition" SG_ 239 ESP_22_BZ 0;
BA_ "GenSigSendType" SG_ 239 ESP_22_CRC 0;
BA_ "GenSigFuncType" SG_ 239 ESP_22_CRC 2;
BA_ "GenSigSwitchedByIgnition" SG_ 239 ESP_22_CRC 0;
BA_ "GenSigSendType" SG_ 239 ESP_FZR_uebersteuern 0;
BA_ "GenSigStartValue" SG_ 239 ESP_FZR_uebersteuern 254;
BA_ "NWM-WakeupAllowed" SG_ 239 ESP_FZR_uebersteuern 1;
BA_ "GenSigSwitchedByIgnition" SG_ 239 ESP_FZR_uebersteuern 0;
BA_ "Fehlerwert" SG_ 239 ESP_FZR_uebersteuern 255;
BA_ "GenSigMissingSourceValue" SG_ 239 ESP_FZR_uebersteuern 254;
BA_ "GenSigSendType" SG_ 239 ESP_FZR_untersteuern 0;
BA_ "GenSigStartValue" SG_ 239 ESP_FZR_untersteuern 254;
BA_ "NWM-WakeupAllowed" SG_ 239 ESP_FZR_untersteuern 1;
BA_ "GenSigSwitchedByIgnition" SG_ 239 ESP_FZR_untersteuern 0;
BA_ "Fehlerwert" SG_ 239 ESP_FZR_untersteuern 255;
BA_ "GenSigMissingSourceValue" SG_ 239 ESP_FZR_untersteuern 254;
BA_ "GenSigSendType" SG_ 239 ESP_HL_Bremsmoment 0;
BA_ "GenSigStartValue" SG_ 239 ESP_HL_Bremsmoment 254;
BA_ "Fehlerwert" SG_ 239 ESP_HL_Bremsmoment 255;
BA_ "GenSigSendType" SG_ 239 ESP_HR_Bremsmoment 0;
BA_ "GenSigStartValue" SG_ 239 ESP_HR_Bremsmoment 254;
BA_ "Fehlerwert" SG_ 239 ESP_HR_Bremsmoment 255;
BA_ "GenSigSendType" SG_ 239 ESP_QBit_HL_Bremsmoment 0;
BA_ "GenSigStartValue" SG_ 239 ESP_QBit_HL_Bremsmoment 1;
BA_ "GenSigSendType" SG_ 239 ESP_QBit_HR_Bremsmoment 0;
BA_ "GenSigStartValue" SG_ 239 ESP_QBit_HR_Bremsmoment 1;
BA_ "GenSigSendType" SG_ 239 ESP_QBit_VL_Bremsmoment 0;
BA_ "GenSigStartValue" SG_ 239 ESP_QBit_VL_Bremsmoment 1;
BA_ "GenSigSendType" SG_ 239 ESP_QBit_VR_Bremsmoment 0;
BA_ "GenSigStartValue" SG_ 239 ESP_QBit_VR_Bremsmoment 1;
BA_ "GenSigSendType" SG_ 239 ESP_VL_Bremsmoment 0;
BA_ "GenSigStartValue" SG_ 239 ESP_VL_Bremsmoment 254;
BA_ "Fehlerwert" SG_ 239 ESP_VL_Bremsmoment 255;
BA_ "GenSigSendType" SG_ 239 ESP_VR_Bremsmoment 0;
BA_ "GenSigStartValue" SG_ 239 ESP_VR_Bremsmoment 254;
BA_ "Fehlerwert" SG_ 239 ESP_VR_Bremsmoment 255;
BA_ "GenSigSendType" SG_ 1470 BR_QBit_Reifenumfang_sekundaer 0;
BA_ "GenSigStartValue" SG_ 1470 BR_QBit_Reifenumfang_sekundaer 1;
BA_ "GenSigSwitchedByIgnition" SG_ 1470 BR_QBit_Reifenumfang_sekundaer 0;
BA_ "GenSigSendType" SG_ 1470 BR_Reifenumfang_sekundaer 0;
BA_ "GenSigSwitchedByIgnition" SG_ 1470 BR_Reifenumfang_sekundaer 0;
BA_ "GenSigSendType" SG_ 1470 ESP_23_BZ 0;
BA_ "GenSigFuncType" SG_ 1470 ESP_23_BZ 1;
BA_ "GenSigSwitchedByIgnition" SG_ 1470 ESP_23_BZ 0;
BA_ "GenSigSendType" SG_ 1470 ESP_23_CRC 0;
BA_ "GenSigFuncType" SG_ 1470 ESP_23_CRC 2;
BA_ "GenSigSwitchedByIgnition" SG_ 1470 ESP_23_CRC 0;
BA_ "GenSigSendType" SG_ 1470 ESP_Gierrate_Offset_2 0;
BA_ "GenSigStartValue" SG_ 1470 ESP_Gierrate_Offset_2 2046;
BA_ "GenSigSwitchedByIgnition" SG_ 1470 ESP_Gierrate_Offset_2 0;
BA_ "Fehlerwert" SG_ 1470 ESP_Gierrate_Offset_2 2047;
BA_ "GenSigSendType" SG_ 1470 ESP_Laengsbeschleunigung_Offset 0;
BA_ "GenSigStartValue" SG_ 1470 ESP_Laengsbeschleunigung_Offset 254;
BA_ "GenSigSwitchedByIgnition" SG_ 1470 ESP_Laengsbeschleunigung_Offset 0;
BA_ "Fehlerwert" SG_ 1470 ESP_Laengsbeschleunigung_Offset 255;
BA_ "GenSigSendType" SG_ 1470 ESP_Lenkwinkel_Offset 0;
BA_ "GenSigStartValue" SG_ 1470 ESP_Lenkwinkel_Offset 510;
BA_ "GenSigSwitchedByIgnition" SG_ 1470 ESP_Lenkwinkel_Offset 0;
BA_ "Fehlerwert" SG_ 1470 ESP_Lenkwinkel_Offset 511;
BA_ "GenSigSendType" SG_ 1470 ESP_Querbeschleunigung_Offset 0;
BA_ "GenSigStartValue" SG_ 1470 ESP_Querbeschleunigung_Offset 62;
BA_ "GenSigSwitchedByIgnition" SG_ 1470 ESP_Querbeschleunigung_Offset 0;
BA_ "Fehlerwert" SG_ 1470 ESP_Querbeschleunigung_Offset 63;
BA_ "GenSigSendType" SG_ 1470 ESP_Status_Bremsentemp_Anz 0;
BA_ "GenSigSwitchedByIgnition" SG_ 1470 ESP_Status_Bremsentemp_Anz 0;
BA_ "Fehlerwert" SG_ 1470 ESP_Status_Bremsentemp_Anz 7;
BA_REL_ "GenSigTimeoutTime" BU_SG_REL_ BedienDisp_vo SG_ 1714 DGN_Verlernzaehler 5000;
BA_REL_ "GenSigTimeoutTime" BU_SG_REL_ BedienDisp_vo SG_ 1714 KBI_Kilometerstand 5000;
BA_REL_ "GenSigTimeoutTime" BU_SG_REL_ BedienDisp_vo SG_ 1714 UH_Jahr 5000;
BA_REL_ "GenSigTimeoutTime" BU_SG_REL_ BedienDisp_vo SG_ 1714 UH_Monat 5000;
BA_REL_ "GenSigTimeoutTime" BU_SG_REL_ BedienDisp_vo SG_ 1714 UH_Tag 5000;
BA_REL_ "GenSigTimeoutTime" BU_SG_REL_ BedienDisp_vo SG_ 1714 UH_Stunde 5000;
BA_REL_ "GenSigTimeoutTime" BU_SG_REL_ BedienDisp_vo SG_ 1714 UH_Minute 5000;
BA_REL_ "GenSigTimeoutTime" BU_SG_REL_ BedienDisp_vo SG_ 1714 UH_Sekunde 5000;
BA_REL_ "GenSigTimeoutTime" BU_SG_REL_ BedienDisp_vo SG_ 1714 Uhrzeit_01_alt 5000;
BA_REL_ "GenSigTimeoutTime" BU_SG_REL_ BedienDisp_vo SG_ 1520 DI_KL_58xd 2000;
BA_REL_ "GenSigTimeoutTime" BU_SG_REL_ BedienDisp_vo SG_ 1520 DI_KL_58xs 2000;
BA_REL_ "GenSigTimeoutTime" BU_SG_REL_ BedienDisp_vo SG_ 1520 DI_KL_58xt 2000;
BA_REL_ "GenSigTimeoutTime" BU_SG_REL_ BedienDisp_vo SG_ 1603 KBI_Einheit_Temp 5000;
BA_REL_ "GenSigTimeoutTime" BU_SG_REL_ BedienSG_hi SG_ 1714 DGN_Verlernzaehler 5000;
BA_REL_ "GenSigTimeoutTime" BU_SG_REL_ BedienSG_hi SG_ 1714 KBI_Kilometerstand 5000;
BA_REL_ "GenSigTimeoutTime" BU_SG_REL_ BedienSG_hi SG_ 1714 UH_Jahr 5000;
BA_REL_ "GenSigTimeoutTime" BU_SG_REL_ BedienSG_hi SG_ 1714 UH_Monat 5000;
BA_REL_ "GenSigTimeoutTime" BU_SG_REL_ BedienSG_hi SG_ 1714 UH_Tag 5000;
BA_REL_ "GenSigTimeoutTime" BU_SG_REL_ BedienSG_hi SG_ 1714 UH_Stunde 5000;
BA_REL_ "GenSigTimeoutTime" BU_SG_REL_ BedienSG_hi SG_ 1714 UH_Minute 5000;
BA_REL_ "GenSigTimeoutTime" BU_SG_REL_ BedienSG_hi SG_ 1714 UH_Sekunde 5000;
BA_REL_ "GenSigTimeoutTime" BU_SG_REL_ BedienSG_hi SG_ 1520 DI_KL_58xd 2000;
BA_REL_ "GenSigTimeoutTime" BU_SG_REL_ BedienSG_hi SG_ 1520 DI_KL_58xs 2000;
BA_REL_ "GenSigTimeoutTime" BU_SG_REL_ BedienSG_hi SG_ 1520 DI_Display_Nachtdesign 2000;
BA_REL_ "GenSigTimeoutTime" BU_SG_REL_ BedienSG_hi SG_ 1520 DI_KL_58xt 2000;
BA_REL_ "GenSigTimeoutTime" BU_SG_REL_ BedienSG_hi SG_ 1520 DI_Fotosensor 2000;
BA_REL_ "GenSigTimeoutTime" BU_SG_REL_ BedienSG_hi SG_ 1603 KBI_Einheit_Datum 5000;
BA_REL_ "GenSigTimeoutTime" BU_SG_REL_ BedienSG_hi SG_ 1603 KBI_Einheit_Druck 5000;
BA_REL_ "GenSigTimeoutTime" BU_SG_REL_ BedienSG_hi SG_ 1603 KBI_Einheit_Streckenanz 5000;
BA_REL_ "GenSigTimeoutTime" BU_SG_REL_ BedienSG_hi SG_ 1603 KBI_Einheit_Temp 5000;
BA_REL_ "GenSigTimeoutTime" BU_SG_REL_ BedienSG_hi SG_ 1603 KBI_Einheit_Uhrzeit 5000;
BA_REL_ "GenSigTimeoutTime" BU_SG_REL_ BedienSG_hi SG_ 1603 KBI_Einheit_Verbrauch 5000;
BA_REL_ "GenSigTimeoutTime" BU_SG_REL_ BedienSG_hi SG_ 1603 KBI_Einheit_Volumen 5000;
BA_REL_ "GenSigTimeoutTime" BU_SG_REL_ BedienSG_hi SG_ 1603 KBI_Einheit_Sprache 5000;
BA_REL_ "GenSigTimeoutTime" BU_SG_REL_ BedienSG_hi SG_ 253 ESP_v_Signal 1000;
BA_REL_ "GenSigTimeoutTime" BU_SG_REL_ DDA SG_ 1714 DGN_Verlernzaehler 5000;
BA_REL_ "GenSigTimeoutTime" BU_SG_REL_ DDA SG_ 1714 KBI_Kilometerstand 5000;
BA_REL_ "GenSigTimeoutTime" BU_SG_REL_ DDA SG_ 1714 UH_Jahr 5000;
BA_REL_ "GenSigTimeoutTime" BU_SG_REL_ DDA SG_ 1714 UH_Monat 5000;
BA_REL_ "GenSigTimeoutTime" BU_SG_REL_ DDA SG_ 1714 UH_Tag 5000;
BA_REL_ "GenSigTimeoutTime" BU_SG_REL_ DDA SG_ 1714 UH_Stunde 5000;
BA_REL_ "GenSigTimeoutTime" BU_SG_REL_ DDA SG_ 1714 UH_Minute 5000;
BA_REL_ "GenSigTimeoutTime" BU_SG_REL_ DDA SG_ 1714 UH_Sekunde 5000;
BA_REL_ "GenSigTimeoutTime" BU_SG_REL_ DDA SG_ 418 HMS_Systemstatus 5000;
BA_REL_ "GenSigTimeoutTime" BU_SG_REL_ DDA SG_ 253 ESP_v_Signal 1000;
BA_REL_ "GenSigTimeoutTime" BU_SG_REL_ GurtMikrofon SG_ 1714 DGN_Verlernzaehler 5000;
BA_REL_ "GenSigTimeoutTime" BU_SG_REL_ GurtMikrofon SG_ 1714 KBI_Kilometerstand 5000;
BA_REL_ "GenSigTimeoutTime" BU_SG_REL_ GurtMikrofon SG_ 1714 UH_Jahr 5000;
BA_REL_ "GenSigTimeoutTime" BU_SG_REL_ GurtMikrofon SG_ 1714 UH_Monat 5000;
BA_REL_ "GenSigTimeoutTime" BU_SG_REL_ GurtMikrofon SG_ 1714 UH_Tag 5000;
BA_REL_ "GenSigTimeoutTime" BU_SG_REL_ GurtMikrofon SG_ 1714 UH_Stunde 5000;
BA_REL_ "GenSigTimeoutTime" BU_SG_REL_ GurtMikrofon SG_ 1714 UH_Minute 5000;
BA_REL_ "GenSigTimeoutTime" BU_SG_REL_ GurtMikrofon SG_ 1714 UH_Sekunde 5000;
BA_REL_ "GenSigTimeoutTime" BU_SG_REL_ OTA_FC SG_ 1714 DGN_Verlernzaehler 5000;
BA_REL_ "GenSigTimeoutTime" BU_SG_REL_ OTA_FC SG_ 1714 KBI_Kilometerstand 5000;
BA_REL_ "GenSigTimeoutTime" BU_SG_REL_ OTA_FC SG_ 1714 UH_Jahr 5000;
BA_REL_ "GenSigTimeoutTime" BU_SG_REL_ OTA_FC SG_ 1714 UH_Monat 5000;
BA_REL_ "GenSigTimeoutTime" BU_SG_REL_ OTA_FC SG_ 1714 UH_Tag 5000;
BA_REL_ "GenSigTimeoutTime" BU_SG_REL_ OTA_FC SG_ 1714 UH_Stunde 5000;
BA_REL_ "GenSigTimeoutTime" BU_SG_REL_ OTA_FC SG_ 1714 UH_Minute 5000;
BA_REL_ "GenSigTimeoutTime" BU_SG_REL_ OTA_FC SG_ 1714 UH_Sekunde 5000;
BA_REL_ "GenSigTimeoutTime" BU_SG_REL_ OTA_FC SG_ 1714 Kombi_02_alt 5000;
BA_REL_ "GenSigTimeoutTime" BU_SG_REL_ OTA_FC SG_ 1714 Uhrzeit_01_alt 5000;
BA_REL_ "GenSigTimeoutTime" BU_SG_REL_ OTA_FC SG_ 2527679980 bCall_active 5000;
BA_REL_ "GenSigTimeoutTime" BU_SG_REL_ OTA_FC SG_ 1603 KBI_Einheit_Datum 5000;
BA_REL_ "GenSigTimeoutTime" BU_SG_REL_ OTA_FC SG_ 1603 KBI_Einheit_Druck 5000;
BA_REL_ "GenSigTimeoutTime" BU_SG_REL_ OTA_FC SG_ 1603 KBI_Einheit_Streckenanz 5000;
BA_REL_ "GenSigTimeoutTime" BU_SG_REL_ OTA_FC SG_ 1603 KBI_MFA_v_Einheit_02 5000;
BA_REL_ "GenSigTimeoutTime" BU_SG_REL_ OTA_FC SG_ 1603 KBI_Einheit_Temp 5000;
BA_REL_ "GenSigTimeoutTime" BU_SG_REL_ OTA_FC SG_ 1603 KBI_Einheit_Uhrzeit 5000;
BA_REL_ "GenSigTimeoutTime" BU_SG_REL_ OTA_FC SG_ 1603 KBI_Einheit_Verbrauch 5000;
BA_REL_ "GenSigTimeoutTime" BU_SG_REL_ OTA_FC SG_ 1603 KBI_Einheit_Volumen 5000;
BA_REL_ "GenSigTimeoutTime" BU_SG_REL_ OTA_FC SG_ 1603 KBI_Einheit_Verbrauch_elektr 5000;
BA_REL_ "GenSigTimeoutTime" BU_SG_REL_ OTA_FC SG_ 1603 KBI_Einheit_Sprache 5000;
BA_REL_ "GenSigTimeoutTime" BU_SG_REL_ OTA_FC SG_ 1603 KBI_Einheit_Masse 5000;
BA_REL_ "GenSigTimeoutTime" BU_SG_REL_ OTA_FC SG_ 260 EPB_Schalterposition 5000;
BA_REL_ "GenSigTimeoutTime" BU_SG_REL_ OTA_FC SG_ 260 EPB_Status_02 5000;
BA_REL_ "GenSigTimeoutTime" BU_SG_REL_ OTA_FC SG_ 259 ESP_VL_FR 1000;
BA_REL_ "GenSigTimeoutTime" BU_SG_REL_ OTA_FC SG_ 259 ESP_VR_FR 1000;
BA_REL_ "GenSigTimeoutTime" BU_SG_REL_ OTA_FC SG_ 259 ESP_HL_FR 1000;
BA_REL_ "GenSigTimeoutTime" BU_SG_REL_ OTA_FC SG_ 259 ESP_HR_FR 1000;
BA_REL_ "GenSigTimeoutTime" BU_SG_REL_ OTA_FC SG_ 259 ESP_VL_Radgeschw 1000;
BA_REL_ "GenSigTimeoutTime" BU_SG_REL_ OTA_FC SG_ 259 ESP_VR_Radgeschw 1000;
BA_REL_ "GenSigTimeoutTime" BU_SG_REL_ OTA_FC SG_ 259 ESP_HL_Radgeschw 1000;
BA_REL_ "GenSigTimeoutTime" BU_SG_REL_ OTA_FC SG_ 259 ESP_HR_Radgeschw 1000;
BA_REL_ "GenSigTimeoutTime" BU_SG_REL_ OTA_FC SG_ 262 ESP_Bremsdruck 500;
BA_REL_ "GenSigTimeoutTime" BU_SG_REL_ OTA_FC SG_ 278 ESP_VL_Fahrtrichtung 500;
BA_REL_ "GenSigTimeoutTime" BU_SG_REL_ OTA_FC SG_ 278 ESP_VR_Fahrtrichtung 500;
BA_REL_ "GenSigTimeoutTime" BU_SG_REL_ OTA_FC SG_ 278 ESP_HL_Fahrtrichtung 500;
BA_REL_ "GenSigTimeoutTime" BU_SG_REL_ OTA_FC SG_ 278 ESP_HR_Fahrtrichtung 500;
BA_REL_ "GenSigTimeoutTime" BU_SG_REL_ OTA_FC SG_ 253 ESP_Vorsteuerung 1000;
BA_REL_ "GenSigTimeoutTime" BU_SG_REL_ OTA_FC SG_ 253 ESP_v_Signal 1000;
BA_REL_ "GenSigTimeoutTime" BU_SG_REL_ OTA_FC SG_ 253 ASR_Tastung_passiv 1000;
BA_REL_ "GenSigTimeoutTime" BU_SG_REL_ OTA_FC SG_ 253 ESP_Tastung_passiv 1000;
BA_REL_ "GenSigTimeoutTime" BU_SG_REL_ OTA_FC SG_ 253 ESP_Systemstatus 1000;
BA_REL_ "GenSigTimeoutTime" BU_SG_REL_ OTA_FC SG_ 253 ABS_Bremsung 1000;
BA_REL_ "GenSigTimeoutTime" BU_SG_REL_ OTA_FC SG_ 253 MSR_Anf 1000;
BA_REL_ "GenSigTimeoutTime" BU_SG_REL_ OTA_FC SG_ 253 EBV_Eingriff 1000;
BA_REL_ "GenSigTimeoutTime" BU_SG_REL_ OTA_FC SG_ 253 EDS_Eingriff 1000;
BA_REL_ "GenSigTimeoutTime" BU_SG_REL_ OTA_FC SG_ 253 ESP_Eingriff 1000;
BA_REL_ "GenSigTimeoutTime" BU_SG_REL_ OTA_FC SG_ 239 ESP_VL_Bremsmoment 500;
BA_REL_ "GenSigTimeoutTime" BU_SG_REL_ OTA_FC SG_ 239 ESP_VR_Bremsmoment 500;
BA_REL_ "GenSigTimeoutTime" BU_SG_REL_ OTA_FC SG_ 239 ESP_HL_Bremsmoment 500;
BA_REL_ "GenSigTimeoutTime" BU_SG_REL_ OTA_FC SG_ 239 ESP_HR_Bremsmoment 500;
BA_REL_ "GenSigTimeoutTime" BU_SG_REL_ OTA_FC SG_ 239 ESP_FZR_uebersteuern 500;
BA_REL_ "GenSigTimeoutTime" BU_SG_REL_ OTA_FC SG_ 239 ESP_FZR_untersteuern 500;
BA_REL_ "GenSigTimeoutTime" BU_SG_REL_ ZR_High SG_ 1714 DGN_Verlernzaehler 5000;
BA_REL_ "GenSigTimeoutTime" BU_SG_REL_ ZR_High SG_ 1714 KBI_Kilometerstand 5000;
BA_REL_ "GenSigTimeoutTime" BU_SG_REL_ ZR_High SG_ 1714 UH_Jahr 5000;
BA_REL_ "GenSigTimeoutTime" BU_SG_REL_ ZR_High SG_ 1714 UH_Monat 5000;
BA_REL_ "GenSigTimeoutTime" BU_SG_REL_ ZR_High SG_ 1714 UH_Tag 5000;
BA_REL_ "GenSigTimeoutTime" BU_SG_REL_ ZR_High SG_ 1714 UH_Stunde 5000;
BA_REL_ "GenSigTimeoutTime" BU_SG_REL_ ZR_High SG_ 1714 UH_Minute 5000;
BA_REL_ "GenSigTimeoutTime" BU_SG_REL_ ZR_High SG_ 1714 UH_Sekunde 5000;
BA_REL_ "GenSigTimeoutTime" BU_SG_REL_ ZR_High SG_ 1520 DI_KL_58xd 2000;
BA_REL_ "GenSigTimeoutTime" BU_SG_REL_ ZR_High SG_ 1520 DI_KL_58xs 2000;
BA_REL_ "GenSigTimeoutTime" BU_SG_REL_ ZR_High SG_ 1520 DI_Display_Nachtdesign 2000;
BA_REL_ "GenSigTimeoutTime" BU_SG_REL_ ZR_High SG_ 420 EA_eCall_Anf 5000;
BA_REL_ "GenSigTimeoutTime" BU_SG_REL_ ZR_High SG_ 420 EA_Funktionsstatus 5000;
BA_REL_ "GenSigTimeoutTime" BU_SG_REL_ ZR_High SG_ 496 EA_Texte 500;
BA_REL_ "GenSigTimeoutTime" BU_SG_REL_ ZR_High SG_ 496 EA_Infotainment_Anf 500;
BA_REL_ "GenSigTimeoutTime" BU_SG_REL_ ZR_High SG_ 496 EA_Tueren_Anf 500;
BA_REL_ "GenSigTimeoutTime" BU_SG_REL_ ZR_High SG_ 496 EA_Innenraumlicht_Anf 500;
BA_REL_ "GenSigTimeoutTime" BU_SG_REL_ ZR_High SG_ 496 zFAS_Warnblinken 500;
BA_REL_ "GenSigTimeoutTime" BU_SG_REL_ ZR_High SG_ 2527679980 eCall_Statuslicht_Farbe2 5000;
BA_REL_ "GenSigTimeoutTime" BU_SG_REL_ ZR_High SG_ 2527679980 eCall_Statuslicht_Farbe1 5000;
BA_REL_ "GenSigTimeoutTime" BU_SG_REL_ ZR_High SG_ 2527679980 bCall_active 5000;
BA_REL_ "GenSigTimeoutTime" BU_SG_REL_ ZR_High SG_ 2527679980 eCall_Funktionsstatus 5000;
BA_REL_ "GenSigTimeoutTime" BU_SG_REL_ ZR_High SG_ 2527679980 eCall_Funktionsstatus_02 5000;
BA_REL_ "GenSigTimeoutTime" BU_SG_REL_ ZR_High SG_ 996 EFF_Verbrauch_STH 5000;
BA_REL_ "GenSigTimeoutTime" BU_SG_REL_ ZR_High SG_ 996 MKE_Texte 5000;
BA_REL_ "GenSigTimeoutTime" BU_SG_REL_ ZR_High SG_ 996 MKE_FAS 5000;
BA_REL_ "GenSigTimeoutTime" BU_SG_REL_ ZR_High SG_ 996 MKE_Stufe 5000;
BA_REL_ "GenSigTimeoutTime" BU_SG_REL_ ZR_High SG_ 996 MKE_FAS_Fkt_Status 5000;
BA_REL_ "GenSigTimeoutTime" BU_SG_REL_ ZR_High SG_ 1603 KBI_Einheit_Datum 5000;
BA_REL_ "GenSigTimeoutTime" BU_SG_REL_ ZR_High SG_ 1603 KBI_Einheit_Druck 5000;
BA_REL_ "GenSigTimeoutTime" BU_SG_REL_ ZR_High SG_ 1603 KBI_Einheit_Streckenanz 5000;
BA_REL_ "GenSigTimeoutTime" BU_SG_REL_ ZR_High SG_ 1603 KBI_MFA_v_Einheit_02 5000;
BA_REL_ "GenSigTimeoutTime" BU_SG_REL_ ZR_High SG_ 1603 KBI_Einheit_Temp 5000;
BA_REL_ "GenSigTimeoutTime" BU_SG_REL_ ZR_High SG_ 1603 KBI_Einheit_Uhrzeit 5000;
BA_REL_ "GenSigTimeoutTime" BU_SG_REL_ ZR_High SG_ 1603 KBI_Einheit_Verbrauch 5000;
BA_REL_ "GenSigTimeoutTime" BU_SG_REL_ ZR_High SG_ 1603 KBI_Einheit_Volumen 5000;
BA_REL_ "GenSigTimeoutTime" BU_SG_REL_ ZR_High SG_ 1603 KBI_Einheit_Sprache 5000;
BA_REL_ "GenSigTimeoutTime" BU_SG_REL_ ZR_High SG_ 1622 ELV_Verriegelt 5000;
BA_REL_ "GenSigTimeoutTime" BU_SG_REL_ ZR_High SG_ 1622 ELV_Entriegelt 5000;
BA_REL_ "GenSigTimeoutTime" BU_SG_REL_ ZR_High SG_ 1622 ELV_LED_Rot 5000;
BA_REL_ "GenSigTimeoutTime" BU_SG_REL_ ZR_High SG_ 1622 ELV_Txt_Lkg_Bewegen 5000;
BA_REL_ "GenSigTimeoutTime" BU_SG_REL_ ZR_High SG_ 1622 ELV_Txt_Werkstatt 5000;
BA_REL_ "GenSigTimeoutTime" BU_SG_REL_ ZR_High SG_ 1622 ELV_Txt_Defekt 5000;
BA_REL_ "GenSigTimeoutTime" BU_SG_REL_ ZR_High SG_ 260 EPB_Status_02 5000;
BA_REL_ "GenSigTimeoutTime" BU_SG_REL_ ZR_High SG_ 781 EPB_Funktionslampe 2000;
BA_REL_ "GenSigTimeoutTime" BU_SG_REL_ ZR_High SG_ 781 EPB_Texte 2000;
BA_REL_ "GenSigTimeoutTime" BU_SG_REL_ ZR_High SG_ 781 EPB_Autoholdlampe 2000;
BA_REL_ "GenSigTimeoutTime" BU_SG_REL_ ZR_High SG_ 781 EPB_Fehlermeldungen 2000;
BA_REL_ "GenSigTimeoutTime" BU_SG_REL_ ZR_High SG_ 259 ESP_VL_Radgeschw 1000;
BA_REL_ "GenSigTimeoutTime" BU_SG_REL_ ZR_High SG_ 259 ESP_VR_Radgeschw 1000;
BA_REL_ "GenSigTimeoutTime" BU_SG_REL_ ZR_High SG_ 259 ESP_HL_Radgeschw 1000;
BA_REL_ "GenSigTimeoutTime" BU_SG_REL_ ZR_High SG_ 259 ESP_HR_Radgeschw 1000;
BA_REL_ "GenSigTimeoutTime" BU_SG_REL_ ZR_High SG_ 262 ESP_QBit_Bremsdruck 500;
BA_REL_ "GenSigTimeoutTime" BU_SG_REL_ ZR_High SG_ 262 ESP_Bremsdruck 500;
BA_REL_ "GenSigTimeoutTime" BU_SG_REL_ ZR_High SG_ 262 ESP_Lenkeingriff_ADS 500;
BA_REL_ "GenSigTimeoutTime" BU_SG_REL_ ZR_High SG_ 262 ESP_Status_Anfahrhilfe 500;
BA_REL_ "GenSigTimeoutTime" BU_SG_REL_ ZR_High SG_ 262 ESP_HDC_aktiv 500;
BA_REL_ "GenSigTimeoutTime" BU_SG_REL_ ZR_High SG_ 262 ESP_Eingr_HL 500;
BA_REL_ "GenSigTimeoutTime" BU_SG_REL_ ZR_High SG_ 262 ESP_Eingr_HR 500;
BA_REL_ "GenSigTimeoutTime" BU_SG_REL_ ZR_High SG_ 262 ESP_Eingr_VL 500;
BA_REL_ "GenSigTimeoutTime" BU_SG_REL_ ZR_High SG_ 262 ESP_Eingr_VR 500;
BA_REL_ "GenSigTimeoutTime" BU_SG_REL_ ZR_High SG_ 262 ESP_Autohold_aktiv 500;
BA_REL_ "GenSigTimeoutTime" BU_SG_REL_ ZR_High SG_ 914 ESP_Rollenmodus_Deaktivieren 5000;
BA_REL_ "GenSigTimeoutTime" BU_SG_REL_ ZR_High SG_ 278 ESP_QBit_Wegimpuls_VL 500;
BA_REL_ "GenSigTimeoutTime" BU_SG_REL_ ZR_High SG_ 278 ESP_QBit_Wegimpuls_VR 500;
BA_REL_ "GenSigTimeoutTime" BU_SG_REL_ ZR_High SG_ 278 ESP_QBit_Wegimpuls_HL 500;
BA_REL_ "GenSigTimeoutTime" BU_SG_REL_ ZR_High SG_ 278 ESP_QBit_Wegimpuls_HR 500;
BA_REL_ "GenSigTimeoutTime" BU_SG_REL_ ZR_High SG_ 278 ESP_Wegimpuls_VL 500;
BA_REL_ "GenSigTimeoutTime" BU_SG_REL_ ZR_High SG_ 278 ESP_Wegimpuls_VR 500;
BA_REL_ "GenSigTimeoutTime" BU_SG_REL_ ZR_High SG_ 278 ESP_Wegimpuls_HL 500;
BA_REL_ "GenSigTimeoutTime" BU_SG_REL_ ZR_High SG_ 278 ESP_Wegimpuls_HR 500;
BA_REL_ "GenSigTimeoutTime" BU_SG_REL_ ZR_High SG_ 278 ESP_VL_Fahrtrichtung 500;
BA_REL_ "GenSigTimeoutTime" BU_SG_REL_ ZR_High SG_ 278 ESP_VR_Fahrtrichtung 500;
BA_REL_ "GenSigTimeoutTime" BU_SG_REL_ ZR_High SG_ 278 ESP_HL_Fahrtrichtung 500;
BA_REL_ "GenSigTimeoutTime" BU_SG_REL_ ZR_High SG_ 278 ESP_HR_Fahrtrichtung 500;
BA_REL_ "GenSigTimeoutTime" BU_SG_REL_ ZR_High SG_ 418 HMS_Systemstatus 5000;
BA_REL_ "GenSigTimeoutTime" BU_SG_REL_ ZR_High SG_ 1629 ESP_Zaehnezahl 1600;
BA_REL_ "GenSigTimeoutTime" BU_SG_REL_ ZR_High SG_ 1629 ESP_Wiederstart_Anz_01 1600;
BA_REL_ "GenSigTimeoutTime" BU_SG_REL_ ZR_High SG_ 1629 ESP_Wiederstart_Anz_04 1600;
BA_REL_ "GenSigTimeoutTime" BU_SG_REL_ ZR_High SG_ 1629 ESP_Stoppverbot_Anz_01 1600;
BA_REL_ "GenSigTimeoutTime" BU_SG_REL_ ZR_High SG_ 1629 ESP_Stoppverbot_Anz_05 1600;
BA_REL_ "GenSigTimeoutTime" BU_SG_REL_ ZR_High SG_ 1629 ESP_Stoppverbot_Anz_06 1600;
BA_REL_ "GenSigTimeoutTime" BU_SG_REL_ ZR_High SG_ 1629 ESP_Dachrelingsensor 1600;
BA_REL_ "GenSigTimeoutTime" BU_SG_REL_ ZR_High SG_ 1629 BR_QBit_Reifenumfang 1600;
BA_REL_ "GenSigTimeoutTime" BU_SG_REL_ ZR_High SG_ 1629 BR_Reifenumfang 1600;
BA_REL_ "GenSigTimeoutTime" BU_SG_REL_ ZR_High SG_ 253 ESP_Diagnose 1000;
BA_REL_ "GenSigTimeoutTime" BU_SG_REL_ ZR_High SG_ 253 OBD_Schlechtweg 1000;
BA_REL_ "GenSigTimeoutTime" BU_SG_REL_ ZR_High SG_ 253 OBD_QBit_Schlechtweg 1000;
BA_REL_ "GenSigTimeoutTime" BU_SG_REL_ ZR_High SG_ 253 ESP_v_Signal 1000;
BA_REL_ "GenSigTimeoutTime" BU_SG_REL_ ZR_High SG_ 253 ESP_Tastung_passiv 1000;
BA_REL_ "GenSigTimeoutTime" BU_SG_REL_ ZR_High SG_ 253 ESP_QBit_v_Signal 1000;
BA_REL_ "GenSigTimeoutTime" BU_SG_REL_ ZR_High SG_ 253 ABS_Bremsung 1000;
BA_REL_ "GenSigTimeoutTime" BU_SG_REL_ ZR_High SG_ 253 ASR_Anf 1000;
BA_REL_ "GenSigTimeoutTime" BU_SG_REL_ ZR_High SG_ 253 MSR_Anf 1000;
BA_REL_ "GenSigTimeoutTime" BU_SG_REL_ ZR_High SG_ 253 ESP_Eingriff 1000;
BA_REL_ "GenSigTimeoutTime" BU_SG_REL_ ZR_High SG_ 253 ESP_ASP 1000;
BA_REL_ "GenSigTimeoutTime" BU_SG_REL_ ZR_High SG_ 239 ESP_FZR_uebersteuern 500;
BA_REL_ "GenSigTimeoutTime" BU_SG_REL_ ZR_High SG_ 239 ESP_FZR_untersteuern 500;
BA_REL_ "GenSigTimeoutTime" BU_SG_REL_ ZR_High SG_ 1470 ESP_Status_Bremsentemp_Anz 3200;
BA_REL_ "GenSigTimeoutTime" BU_SG_REL_ ZR_High SG_ 1470 ESP_Querbeschleunigung_Offset 3200;
BA_REL_ "GenSigTimeoutTime" BU_SG_REL_ ZR_High SG_ 1470 ESP_Laengsbeschleunigung_Offset 3200;
BA_REL_ "GenSigTimeoutTime" BU_SG_REL_ ZR_LIMU SG_ 1714 DGN_Verlernzaehler 5000;
BA_REL_ "GenSigTimeoutTime" BU_SG_REL_ ZR_LIMU SG_ 1714 KBI_Kilometerstand 5000;
BA_REL_ "GenSigTimeoutTime" BU_SG_REL_ ZR_LIMU SG_ 1714 UH_Jahr 5000;
BA_REL_ "GenSigTimeoutTime" BU_SG_REL_ ZR_LIMU SG_ 1714 UH_Monat 5000;
BA_REL_ "GenSigTimeoutTime" BU_SG_REL_ ZR_LIMU SG_ 1714 UH_Tag 5000;
BA_REL_ "GenSigTimeoutTime" BU_SG_REL_ ZR_LIMU SG_ 1714 UH_Stunde 5000;
BA_REL_ "GenSigTimeoutTime" BU_SG_REL_ ZR_LIMU SG_ 1714 UH_Minute 5000;
BA_REL_ "GenSigTimeoutTime" BU_SG_REL_ ZR_LIMU SG_ 1714 UH_Sekunde 5000;
BA_REL_ "GenSigTimeoutTime" BU_SG_REL_ ZR_LIMU SG_ 1714 Kombi_02_alt 5000;
BA_REL_ "GenSigTimeoutTime" BU_SG_REL_ ZR_LIMU SG_ 1714 Uhrzeit_01_alt 5000;
BA_REL_ "GenSigTimeoutTime" BU_SG_REL_ ZR_LIMU SG_ 1520 DI_KL_58xd 2000;
BA_REL_ "GenSigTimeoutTime" BU_SG_REL_ ZR_LIMU SG_ 1520 DI_KL_58xs 2000;
BA_REL_ "GenSigTimeoutTime" BU_SG_REL_ ZR_LIMU SG_ 1520 DI_Display_Nachtdesign 2000;
BA_REL_ "GenSigTimeoutTime" BU_SG_REL_ ZR_LIMU SG_ 1520 DI_KL_58xt 2000;
BA_REL_ "GenSigTimeoutTime" BU_SG_REL_ ZR_LIMU SG_ 1520 DI_Fotosensor 2000;
BA_REL_ "GenSigTimeoutTime" BU_SG_REL_ ZR_LIMU SG_ 1520 BCM1_Stellgroesse_Kl_58s 2000;
BA_REL_ "GenSigTimeoutTime" BU_SG_REL_ ZR_LIMU SG_ 496 EA_Infotainment_Anf 500;
BA_REL_ "GenSigTimeoutTime" BU_SG_REL_ ZR_LIMU SG_ 260 EPB_Status_02 5000;
BA_REL_ "GenSigTimeoutTime" BU_SG_REL_ ZR_LIMU SG_ 259 ESP_VL_Radgeschw 1000;
BA_REL_ "GenSigTimeoutTime" BU_SG_REL_ ZR_LIMU SG_ 259 ESP_VR_Radgeschw 1000;
BA_REL_ "GenSigTimeoutTime" BU_SG_REL_ ZR_LIMU SG_ 259 ESP_HL_Radgeschw 1000;
BA_REL_ "GenSigTimeoutTime" BU_SG_REL_ ZR_LIMU SG_ 259 ESP_HR_Radgeschw 1000;
BA_REL_ "GenSigTimeoutTime" BU_SG_REL_ ZR_LIMU SG_ 262 ESP_QBit_Bremsdruck 500;
BA_REL_ "GenSigTimeoutTime" BU_SG_REL_ ZR_LIMU SG_ 262 ESP_Bremsdruck 500;
BA_REL_ "GenSigTimeoutTime" BU_SG_REL_ ZR_LIMU SG_ 262 ESP_Eingr_HL 500;
BA_REL_ "GenSigTimeoutTime" BU_SG_REL_ ZR_LIMU SG_ 262 ESP_Eingr_HR 500;
BA_REL_ "GenSigTimeoutTime" BU_SG_REL_ ZR_LIMU SG_ 262 ESP_Eingr_VL 500;
BA_REL_ "GenSigTimeoutTime" BU_SG_REL_ ZR_LIMU SG_ 262 ESP_Eingr_VR 500;
BA_REL_ "GenSigTimeoutTime" BU_SG_REL_ ZR_LIMU SG_ 914 ESP_Rollenmodus_Deaktivieren 5000;
BA_REL_ "GenSigTimeoutTime" BU_SG_REL_ ZR_LIMU SG_ 278 ESP_QBit_Wegimpuls_VL 500;
BA_REL_ "GenSigTimeoutTime" BU_SG_REL_ ZR_LIMU SG_ 278 ESP_QBit_Wegimpuls_VR 500;
BA_REL_ "GenSigTimeoutTime" BU_SG_REL_ ZR_LIMU SG_ 278 ESP_QBit_Wegimpuls_HL 500;
BA_REL_ "GenSigTimeoutTime" BU_SG_REL_ ZR_LIMU SG_ 278 ESP_QBit_Wegimpuls_HR 500;
BA_REL_ "GenSigTimeoutTime" BU_SG_REL_ ZR_LIMU SG_ 278 ESP_Wegimpuls_VL 500;
BA_REL_ "GenSigTimeoutTime" BU_SG_REL_ ZR_LIMU SG_ 278 ESP_Wegimpuls_VR 500;
BA_REL_ "GenSigTimeoutTime" BU_SG_REL_ ZR_LIMU SG_ 278 ESP_Wegimpuls_HL 500;
BA_REL_ "GenSigTimeoutTime" BU_SG_REL_ ZR_LIMU SG_ 278 ESP_Wegimpuls_HR 500;
BA_REL_ "GenSigTimeoutTime" BU_SG_REL_ ZR_LIMU SG_ 278 ESP_VL_Fahrtrichtung 500;
BA_REL_ "GenSigTimeoutTime" BU_SG_REL_ ZR_LIMU SG_ 278 ESP_VR_Fahrtrichtung 500;
BA_REL_ "GenSigTimeoutTime" BU_SG_REL_ ZR_LIMU SG_ 278 ESP_HL_Fahrtrichtung 500;
BA_REL_ "GenSigTimeoutTime" BU_SG_REL_ ZR_LIMU SG_ 278 ESP_HR_Fahrtrichtung 500;
BA_REL_ "GenSigTimeoutTime" BU_SG_REL_ ZR_LIMU SG_ 1629 ESP_Zaehnezahl 1600;
BA_REL_ "GenSigTimeoutTime" BU_SG_REL_ ZR_LIMU SG_ 253 ESP_v_Signal 1000;
BA_REL_ "GenSigTimeoutTime" BU_SG_REL_ ZR_LIMU SG_ 253 ESP_Tastung_passiv 1000;
BA_REL_ "GenSigTimeoutTime" BU_SG_REL_ ZR_LIMU SG_ 253 ESP_QBit_v_Signal 1000;
BA_REL_ "GenSigTimeoutTime" BU_SG_REL_ ZR_LIMU SG_ 253 ABS_Bremsung 1000;
BA_REL_ "GenSigTimeoutTime" BU_SG_REL_ ZR_LIMU SG_ 239 ESP_FZR_uebersteuern 500;
BA_REL_ "GenSigTimeoutTime" BU_SG_REL_ ZR_LIMU SG_ 239 ESP_FZR_untersteuern 500;
BA_REL_ "GenSigTimeoutTime" BU_SG_REL_ ZR_LIMU SG_ 1470 ESP_Status_Bremsentemp_Anz 3200;
BA_REL_ "GenSigTimeoutTime" BU_SG_REL_ ZR_MIB_TOP_ab_Gen3 SG_ 1714 DGN_Verlernzaehler 5000;
BA_REL_ "GenSigTimeoutTime" BU_SG_REL_ ZR_MIB_TOP_ab_Gen3 SG_ 1714 KBI_Kilometerstand 5000;
BA_REL_ "GenSigTimeoutTime" BU_SG_REL_ ZR_MIB_TOP_ab_Gen3 SG_ 1714 UH_Jahr 5000;
BA_REL_ "GenSigTimeoutTime" BU_SG_REL_ ZR_MIB_TOP_ab_Gen3 SG_ 1714 UH_Monat 5000;
BA_REL_ "GenSigTimeoutTime" BU_SG_REL_ ZR_MIB_TOP_ab_Gen3 SG_ 1714 UH_Tag 5000;
BA_REL_ "GenSigTimeoutTime" BU_SG_REL_ ZR_MIB_TOP_ab_Gen3 SG_ 1714 UH_Stunde 5000;
BA_REL_ "GenSigTimeoutTime" BU_SG_REL_ ZR_MIB_TOP_ab_Gen3 SG_ 1714 UH_Minute 5000;
BA_REL_ "GenSigTimeoutTime" BU_SG_REL_ ZR_MIB_TOP_ab_Gen3 SG_ 1714 UH_Sekunde 5000;
BA_REL_ "GenSigTimeoutTime" BU_SG_REL_ ZR_MIB_TOP_ab_Gen3 SG_ 1714 Kombi_02_alt 5000;
BA_REL_ "GenSigTimeoutTime" BU_SG_REL_ ZR_MIB_TOP_ab_Gen3 SG_ 1714 Uhrzeit_01_alt 5000;
BA_REL_ "GenSigTimeoutTime" BU_SG_REL_ ZR_MIB_TOP_ab_Gen3 SG_ 1520 DI_KL_58xd 2000;
BA_REL_ "GenSigTimeoutTime" BU_SG_REL_ ZR_MIB_TOP_ab_Gen3 SG_ 1520 DI_KL_58xs 2000;
BA_REL_ "GenSigTimeoutTime" BU_SG_REL_ ZR_MIB_TOP_ab_Gen3 SG_ 1520 DI_Display_Nachtdesign 2000;
BA_REL_ "GenSigTimeoutTime" BU_SG_REL_ ZR_MIB_TOP_ab_Gen3 SG_ 496 EA_Infotainment_Anf 500;
BA_REL_ "GenSigTimeoutTime" BU_SG_REL_ ZR_MIB_TOP_ab_Gen3 SG_ 189 EBKV_Stangenweg 1000;
BA_REL_ "GenSigTimeoutTime" BU_SG_REL_ ZR_MIB_TOP_ab_Gen3 SG_ 115 EM1_IstMoment 500;
BA_REL_ "GenSigTimeoutTime" BU_SG_REL_ ZR_MIB_TOP_ab_Gen3 SG_ 115 EM1_IstDrehzahl 500;
BA_REL_ "GenSigTimeoutTime" BU_SG_REL_ ZR_MIB_TOP_ab_Gen3 SG_ 260 EPB_Status_02 5000;
BA_REL_ "GenSigTimeoutTime" BU_SG_REL_ ZR_MIB_TOP_ab_Gen3 SG_ 259 ESP_VL_Radgeschw 1000;
BA_REL_ "GenSigTimeoutTime" BU_SG_REL_ ZR_MIB_TOP_ab_Gen3 SG_ 259 ESP_VR_Radgeschw 1000;
BA_REL_ "GenSigTimeoutTime" BU_SG_REL_ ZR_MIB_TOP_ab_Gen3 SG_ 259 ESP_HL_Radgeschw 1000;
BA_REL_ "GenSigTimeoutTime" BU_SG_REL_ ZR_MIB_TOP_ab_Gen3 SG_ 259 ESP_HR_Radgeschw 1000;
BA_REL_ "GenSigTimeoutTime" BU_SG_REL_ ZR_MIB_TOP_ab_Gen3 SG_ 262 ESP_QBit_Bremsdruck 500;
BA_REL_ "GenSigTimeoutTime" BU_SG_REL_ ZR_MIB_TOP_ab_Gen3 SG_ 262 ESP_Bremsdruck 500;
BA_REL_ "GenSigTimeoutTime" BU_SG_REL_ ZR_MIB_TOP_ab_Gen3 SG_ 262 ESP_Eingr_HL 500;
BA_REL_ "GenSigTimeoutTime" BU_SG_REL_ ZR_MIB_TOP_ab_Gen3 SG_ 262 ESP_Eingr_HR 500;
BA_REL_ "GenSigTimeoutTime" BU_SG_REL_ ZR_MIB_TOP_ab_Gen3 SG_ 262 ESP_Eingr_VL 500;
BA_REL_ "GenSigTimeoutTime" BU_SG_REL_ ZR_MIB_TOP_ab_Gen3 SG_ 262 ESP_Eingr_VR 500;
BA_REL_ "GenSigTimeoutTime" BU_SG_REL_ ZR_MIB_TOP_ab_Gen3 SG_ 914 ESP_Rollenmodus_Deaktivieren 5000;
BA_REL_ "GenSigTimeoutTime" BU_SG_REL_ ZR_MIB_TOP_ab_Gen3 SG_ 278 ESP_QBit_Wegimpuls_VL 500;
BA_REL_ "GenSigTimeoutTime" BU_SG_REL_ ZR_MIB_TOP_ab_Gen3 SG_ 278 ESP_QBit_Wegimpuls_VR 500;
BA_REL_ "GenSigTimeoutTime" BU_SG_REL_ ZR_MIB_TOP_ab_Gen3 SG_ 278 ESP_QBit_Wegimpuls_HL 500;
BA_REL_ "GenSigTimeoutTime" BU_SG_REL_ ZR_MIB_TOP_ab_Gen3 SG_ 278 ESP_QBit_Wegimpuls_HR 500;
BA_REL_ "GenSigTimeoutTime" BU_SG_REL_ ZR_MIB_TOP_ab_Gen3 SG_ 278 ESP_Wegimpuls_VL 500;
BA_REL_ "GenSigTimeoutTime" BU_SG_REL_ ZR_MIB_TOP_ab_Gen3 SG_ 278 ESP_Wegimpuls_VR 500;
BA_REL_ "GenSigTimeoutTime" BU_SG_REL_ ZR_MIB_TOP_ab_Gen3 SG_ 278 ESP_Wegimpuls_HL 500;
BA_REL_ "GenSigTimeoutTime" BU_SG_REL_ ZR_MIB_TOP_ab_Gen3 SG_ 278 ESP_Wegimpuls_HR 500;
BA_REL_ "GenSigTimeoutTime" BU_SG_REL_ ZR_MIB_TOP_ab_Gen3 SG_ 278 ESP_VL_Fahrtrichtung 500;
BA_REL_ "GenSigTimeoutTime" BU_SG_REL_ ZR_MIB_TOP_ab_Gen3 SG_ 278 ESP_VR_Fahrtrichtung 500;
BA_REL_ "GenSigTimeoutTime" BU_SG_REL_ ZR_MIB_TOP_ab_Gen3 SG_ 278 ESP_HL_Fahrtrichtung 500;
BA_REL_ "GenSigTimeoutTime" BU_SG_REL_ ZR_MIB_TOP_ab_Gen3 SG_ 278 ESP_HR_Fahrtrichtung 500;
BA_REL_ "GenSigTimeoutTime" BU_SG_REL_ ZR_MIB_TOP_ab_Gen3 SG_ 1629 ESP_Zaehnezahl 1600;
BA_REL_ "GenSigTimeoutTime" BU_SG_REL_ ZR_MIB_TOP_ab_Gen3 SG_ 253 ESP_v_Signal 1000;
BA_REL_ "GenSigTimeoutTime" BU_SG_REL_ ZR_MIB_TOP_ab_Gen3 SG_ 253 ESP_Tastung_passiv 1000;
BA_REL_ "GenSigTimeoutTime" BU_SG_REL_ ZR_MIB_TOP_ab_Gen3 SG_ 253 ESP_QBit_v_Signal 1000;
BA_REL_ "GenSigTimeoutTime" BU_SG_REL_ ZR_MIB_TOP_ab_Gen3 SG_ 253 ABS_Bremsung 1000;
BA_REL_ "GenSigTimeoutTime" BU_SG_REL_ ZR_MIB_TOP_ab_Gen3 SG_ 253 ASR_Anf 1000;
BA_REL_ "GenSigTimeoutTime" BU_SG_REL_ ZR_MIB_TOP_ab_Gen3 SG_ 239 ESP_VL_Bremsmoment 500;
BA_REL_ "GenSigTimeoutTime" BU_SG_REL_ ZR_MIB_TOP_ab_Gen3 SG_ 239 ESP_VR_Bremsmoment 500;
BA_REL_ "GenSigTimeoutTime" BU_SG_REL_ ZR_MIB_TOP_ab_Gen3 SG_ 239 ESP_HL_Bremsmoment 500;
BA_REL_ "GenSigTimeoutTime" BU_SG_REL_ ZR_MIB_TOP_ab_Gen3 SG_ 239 ESP_HR_Bremsmoment 500;
BA_REL_ "GenSigTimeoutTime" BU_SG_REL_ ZR_MIB_TOP_ab_Gen3 SG_ 239 ESP_FZR_uebersteuern 500;
BA_REL_ "GenSigTimeoutTime" BU_SG_REL_ ZR_MIB_TOP_ab_Gen3 SG_ 239 ESP_FZR_untersteuern 500;
BA_REL_ "GenSigTimeoutTime" BU_SG_REL_ ZR_MIB_TOP_ab_Gen3 SG_ 1470 ESP_Status_Bremsentemp_Anz 3200;
BA_REL_ "GenSigTimeoutTime" BU_SG_REL_ ZR_Standard SG_ 1714 DGN_Verlernzaehler 5000;
BA_REL_ "GenSigTimeoutTime" BU_SG_REL_ ZR_Standard SG_ 1714 KBI_Kilometerstand 5000;
BA_REL_ "GenSigTimeoutTime" BU_SG_REL_ ZR_Standard SG_ 1714 UH_Jahr 5000;
BA_REL_ "GenSigTimeoutTime" BU_SG_REL_ ZR_Standard SG_ 1714 UH_Monat 5000;
BA_REL_ "GenSigTimeoutTime" BU_SG_REL_ ZR_Standard SG_ 1714 UH_Tag 5000;
BA_REL_ "GenSigTimeoutTime" BU_SG_REL_ ZR_Standard SG_ 1714 UH_Stunde 5000;
BA_REL_ "GenSigTimeoutTime" BU_SG_REL_ ZR_Standard SG_ 1714 UH_Minute 5000;
BA_REL_ "GenSigTimeoutTime" BU_SG_REL_ ZR_Standard SG_ 1714 UH_Sekunde 5000;
BA_REL_ "GenSigTimeoutTime" BU_SG_REL_ ZR_Standard SG_ 1520 DI_KL_58xd 2000;
BA_REL_ "GenSigTimeoutTime" BU_SG_REL_ ZR_Standard SG_ 1520 DI_KL_58xs 2000;
BA_REL_ "GenSigTimeoutTime" BU_SG_REL_ ZR_Standard SG_ 1520 DI_Display_Nachtdesign 2000;
BA_REL_ "GenSigTimeoutTime" BU_SG_REL_ ZR_Standard SG_ 496 EA_Infotainment_Anf 500;
BA_REL_ "GenSigTimeoutTime" BU_SG_REL_ ZR_Standard SG_ 1603 KBI_Einheit_Datum 5000;
BA_REL_ "GenSigTimeoutTime" BU_SG_REL_ ZR_Standard SG_ 1603 KBI_Einheit_Druck 5000;
BA_REL_ "GenSigTimeoutTime" BU_SG_REL_ ZR_Standard SG_ 1603 KBI_Einheit_Streckenanz 5000;
BA_REL_ "GenSigTimeoutTime" BU_SG_REL_ ZR_Standard SG_ 1603 KBI_MFA_v_Einheit_02 5000;
BA_REL_ "GenSigTimeoutTime" BU_SG_REL_ ZR_Standard SG_ 1603 KBI_Einheit_Temp 5000;
BA_REL_ "GenSigTimeoutTime" BU_SG_REL_ ZR_Standard SG_ 1603 KBI_Einheit_Uhrzeit 5000;
BA_REL_ "GenSigTimeoutTime" BU_SG_REL_ ZR_Standard SG_ 1603 KBI_Einheit_Verbrauch 5000;
BA_REL_ "GenSigTimeoutTime" BU_SG_REL_ ZR_Standard SG_ 1603 KBI_Einheit_Volumen 5000;
BA_REL_ "GenSigTimeoutTime" BU_SG_REL_ ZR_Standard SG_ 1603 KBI_Einheit_Sprache 5000;
BA_REL_ "GenSigTimeoutTime" BU_SG_REL_ ZR_Standard SG_ 260 EPB_Status_02 5000;
BA_REL_ "GenSigTimeoutTime" BU_SG_REL_ ZR_Standard SG_ 262 ESP_QBit_Bremsdruck 500;
BA_REL_ "GenSigTimeoutTime" BU_SG_REL_ ZR_Standard SG_ 262 ESP_Bremsdruck 500;
BA_REL_ "GenSigTimeoutTime" BU_SG_REL_ ZR_Standard SG_ 278 ESP_QBit_Wegimpuls_VL 500;
BA_REL_ "GenSigTimeoutTime" BU_SG_REL_ ZR_Standard SG_ 278 ESP_QBit_Wegimpuls_VR 500;
BA_REL_ "GenSigTimeoutTime" BU_SG_REL_ ZR_Standard SG_ 278 ESP_QBit_Wegimpuls_HL 500;
BA_REL_ "GenSigTimeoutTime" BU_SG_REL_ ZR_Standard SG_ 278 ESP_QBit_Wegimpuls_HR 500;
BA_REL_ "GenSigTimeoutTime" BU_SG_REL_ ZR_Standard SG_ 278 ESP_Wegimpuls_VL 500;
BA_REL_ "GenSigTimeoutTime" BU_SG_REL_ ZR_Standard SG_ 278 ESP_Wegimpuls_VR 500;
BA_REL_ "GenSigTimeoutTime" BU_SG_REL_ ZR_Standard SG_ 278 ESP_Wegimpuls_HL 500;
BA_REL_ "GenSigTimeoutTime" BU_SG_REL_ ZR_Standard SG_ 278 ESP_Wegimpuls_HR 500;
BA_REL_ "GenSigTimeoutTime" BU_SG_REL_ ZR_Standard SG_ 278 ESP_VL_Fahrtrichtung 500;
BA_REL_ "GenSigTimeoutTime" BU_SG_REL_ ZR_Standard SG_ 278 ESP_VR_Fahrtrichtung 500;
BA_REL_ "GenSigTimeoutTime" BU_SG_REL_ ZR_Standard SG_ 278 ESP_HL_Fahrtrichtung 500;
BA_REL_ "GenSigTimeoutTime" BU_SG_REL_ ZR_Standard SG_ 278 ESP_HR_Fahrtrichtung 500;
BA_REL_ "GenSigTimeoutTime" BU_SG_REL_ ZR_Standard SG_ 1629 ESP_Zaehnezahl 1600;
BA_REL_ "GenSigTimeoutTime" BU_SG_REL_ ZR_Standard SG_ 253 ESP_v_Signal 1000;
BA_REL_ "GenSigTimeoutTime" BU_SG_REL_ ZR_Standard SG_ 253 ESP_QBit_v_Signal 1000;
VAL_ 2617219614 DEV_ZR_Pwm_Debug_1 0 "nicht_angefordert" 1 "angefordert" ;
VAL_ 2617219614 DEV_ZR_Pwm_Debug_2 0 "nicht_angefordert" 1 "angefordert" ;
VAL_ 2617219614 DEV_ZR_Pwm_Debug_3 0 "nicht_angefordert" 1 "angefordert" ;
VAL_ 2617219614 DEV_ZR_Pwm_Debug_4 0 "nicht_angefordert" 1 "angefordert" ;
VAL_ 2617219605 ZR_KL_30F 254 "Init" 255 "Fehler" ;
VAL_ 2617219605 ZR_TempSens 254 "Init" 255 "Fehler" ;
VAL_ 2617219605 Reset_Counter 254 "Init" 255 "Fehler" ;
VAL_ 2617219605 MMI_State 0 "MMI_OFF" 1 "MMI_IOC" 2 "MMI_STDBY" 3 "MMI_ON" 4 "MMI_STDBY_PWR_SAVE" 5 "MMI_STDBY_RESTR" 6 "MMI_ON_DIAG" 7 "MMI_ON_TEL" 8 "MMI_ON_SWDL" 9 "MMI_ON_CUST_SWDL" 10 "MMI_STDBY_PWR_SAVE_1" 11 "MMI_STDBY_PWR_SAVE_2" 12 "MMI_STANDBY_CUST_SWDL" 13 "MMI_ONLINE_IOC" 14 "MMI_ONLINE" 15 "MMI_PHONE_IOC" 16 "MMI_PHONE" 17 "MMI_RTC" 18 "MMI_DCI" ;
VAL_ 2617219605 Tel_aktiv 0 "inaktiv" 1 "aktiv" ;
VAL_ 2617219605 Routeg_aktiv 0 "inaktiv" 1 "aktiv" ;
VAL_ 2617219605 ZR_LastOn 7 "Init" ;
VAL_ 2617219605 SI_MOST_Status 0 "MOST_sleep_(Licht_AUS)" 1 "MOST_aktiv_(Kommunikation_moeglich)" ;
VAL_ 2617219605 ZR_State_DU_1 0 "Disp_Off" 1 "Disp_On" 2 "LowPow" ;
VAL_ 2617219605 Tel_SIM_aktiv 0 "inaktiv" 1 "aktiv" ;
VAL_ 1714 DGN_Verlernzaehler 255 "ungültiger Zählerstand oder kein gültiger Fahrzyklus" ;
VAL_ 1714 KBI_Kilometerstand 1048574 "Init" 1048575 "Fehler" ;
VAL_ 1714 UH_Monat 0 "Init" 14 "Relatives_Datum" 15 "Fehler" ;
VAL_ 1714 UH_Tag 0 "Init" ;
VAL_ 1714 Kombi_02_alt 0 "aktuell" 1 "veraltet" ;
VAL_ 1714 Uhrzeit_01_alt 0 "aktuell" 1 "veraltet" ;
VAL_ 1520 DI_KL_58xd 254 "Init" 255 "Fehler" ;
VAL_ 1520 DI_KL_58xs 126 "Init" 127 "Fehler" ;
VAL_ 1520 DI_KL_58xt 126 "Init" 127 "Fehler" ;
VAL_ 1520 BCM1_Stellgroesse_Kl_58s 125 "Nicht_verbaut" 126 "Init" 127 "Fehler" ;
VAL_ 420 EA_Parken_beibehalten_HMS 0 "Parken_nicht_beibehalten" 1 "Parken_beibehalten" 2 "Init" 3 "Fehler" ;
VAL_ 420 EA_Warnruckprofil 0 "keine_Ruckanforderung" 1 "Profil_1" 2 "Profil_2" 3 "Profil_3" 4 "Profil_4" 5 "Profil_5" 6 "Profil_6" 7 "Profil_7" ;
VAL_ 420 EA_eCall_Anf 0 "Keine_Anforderung" 1 "Ausloesen_eCall" ;
VAL_ 420 EA_Funktionsstatus 0 "EA_INIT" 1 "EA_OFF" 2 "EA_STANDBY" 3 "EA_PHASE0_AKTIV" 4 "EA_PHASE1_AKTIV" 5 "EA_PHASE2_AKTIV" 6 "EA_PHASE3_AKTIV" 7 "EA_REVERSIBLER_FEHLER" 8 "EA_IRREVERSIBLER_FEHLER" ;
VAL_ 420 EA_Gurtstraffer_Anf 0 "Keine_Anforderung" 1 "Haptik_1" 2 "Haptik_2" 3 "Haptik_3" ;
VAL_ 420 EA_Anforderung_HMS 0 "keine_Anforderung" 1 "halten" 2 "parken" 3 "halten_Standby" 4 "anfahren" 5 "Loesen_ueber_Rampe" 6 "Parken_mit_P" ;
VAL_ 420 EA_Sollbeschleunigung 2046 "Neutralwert" 2047 "Fehler" ;
VAL_ 496 EA_Texte 0 "keine_Anzeige" 1 "Nothalteassistent_fehlende_Fahreraktivitaet" 2 "Nothalteassistent_aktiv_Fahrzeugfuehrung_uebernehmen" 3 "Nothalteassistent_automatischer_Nothalt_wird_durchgefuehrt" 4 "Nothalteassistent_automatischer_Nothalt_durchgefuehrt" 5 "Nothalteassistent_Verbindung_zum_Notruf_wird_aufgebaut" 6 "Nothalteassistent_deaktiviert" 7 "Nothalteassistent_Eingriff_abgebrochen" 8 "Nothalteassistent_fehlende_Fahreraktivitaet_2" 9 "Sekundenschlaf_erkannt" 10 "LaneAssist_Lenkung_uebernehmen" 11 "ACA_Fahrzeugfuehrung_uebernehmen" 12 "EA_Fahr_Standstreifenwechsel" 14 "Nothalteassistent_nicht_verfuegbar_reversibel" 15 "Nothalteassistent_Stoerung_irreversibel" ;
VAL_ 496 ACF_Lampe_Hands_Off 0 "keine_Anzeige" 1 "Hands_Off_erkannt" ;
VAL_ 496 EA_Infotainment_Anf 0 "Init" 1 "Keine_Absenkung" 2 "Absenkung" 3 "Mute" ;
VAL_ 496 EA_Tueren_Anf 0 "Keine_Anforderung" 1 "Tueren_entriegeln" ;
VAL_ 496 EA_Innenraumlicht_Anf 0 "Innenraumbeleuchtung_ausschalten" 1 "Innenraumbeleuchtung_einschalten" ;
VAL_ 496 zFAS_Warnblinken 0 "Aus" 1 "Statisch" 2 "Taster" 3 "Statisch_ohne_WBT" ;
VAL_ 496 STP_Primaeranz 0 "keine_Anzeige" 1 "Verfuegbar" 2 "Aktiv" 3 "Uebernahme" 4 "Aktiv_Warnung" 5 "Nicht_Verfuegbar" ;
VAL_ 496 EA_Bremslichtblinken 0 "kein_Blinken" 1 "Anforderung_Bremslichtblinken" ;
VAL_ 496 EA_Blinken 0 "Kein_Blinken" 1 "Wechselblinken_links" 2 "Wechselblinken_rechts" 3 "Warnblinken" 4 "Warnblinken_Taster" ;
VAL_ 496 EA_Status_HMI 0 "Keine_Anzeige" 1 "Aktiv_quer_laengs" 2 "Aktiv_laengs" ;
VAL_ 189 EBKV_AktBr_aktiv 0 "Fahrer_aktiv" 1 "eBKV_aktiv" ;
VAL_ 189 EBKV_extBr_Status 0 "Init" 1 "verfuegbar" 2 "nicht_verfuegbar" 3 "aktiv" 4 "Aktiv_mit_Einschraenkung" ;
VAL_ 189 EBKV_HZ_Bohrung_geschlossen 0 "offen" 1 "geschlossen" ;
VAL_ 189 EBKV_Status_02 0 "EBKV_nicht_initialisiert" 1 "EBKV_Fehler_Zustand_aus" 2 "EBKV_Diagnose" 3 "EBKV_nicht_belegt" 4 "EBKV_Standalone" 5 "EBKV_degradiert" 6 "EBKV_Nachlauf_degradiert" 7 "EBKV_bereit" 8 "EBKV_Ausfall_Rekukomponente" 9 "EBKV_Shutdown" 10 "EBKV_nicht_belegt" 11 "EBKV_nicht_belegt" 12 "EBKV_nicht_belegt" 13 "EBKV_nicht_belegt" 14 "EBKV_nicht_belegt" 15 "EBKV_nicht_belegt" ;
VAL_ 189 SEKU_Bremslicht 0 "aus" 1 "an" ;
VAL_ 189 SEKU_Status 0 "SEKU_inaktiv" 1 "SEKU_bereit" 2 "SEKU_aktiv" 3 "SEKU_nicht_verfuegbar" ;
VAL_ 189 SEKU_Anforderung_GE 0 "keine_Anforderung" 1 "P_einlegen" ;
VAL_ 189 EBKV_Stangenweg 4094 "Init" 4095 "Fehler" ;
VAL_ 189 EBKV_AktSp_Status 0 "Off" 1 "Referenzfahrt" 2 "Control" 3 "LoadCritical" ;
VAL_ 189 EBKV_AktSp_Volumenreserve 254 "Init" 255 "Fehler" ;
VAL_ 189 EBKV_Kraftblending_Reserve 254 "Init" 255 "Fehler" ;
VAL_ 2527679980 eCall_Statuslicht_Farbe2 0 "Aus" 1 "Blinken_1" 2 "Blinken_2" 3 "An" ;
VAL_ 2527679980 eCall_Statuslicht_Farbe1 0 "Aus" 1 "Blinken_1" 2 "Blinken_2" 3 "An" ;
VAL_ 2527679980 bCall_active 0 "bcall_inactive" 1 "bcall_active" ;
VAL_ 2527679980 eCall_Funktionsstatus 0 "kein_Fehler" 1 "Fkt_eingeschraenkt" 2 "Fkt_eingeschraenkt_service" 3 "Fkt_nicht_verfuegbar" 4 "Fkt_Service" 5 "Fkt_deaktiviert" 6 "Fkt_aktiviert" 7 "init" ;
VAL_ 2527679980 eCall_Subscription 0 "Init" 1 "unsubscribed" 2 "subscribed" ;
VAL_ 2527679980 eCall_Funktionsstatus_02 0 "kein_Fehler" 1 "Manueller_Notruf_aktiv" 2 "Automatischer_Notruf_aktiv" 7 "Init" ;
VAL_ 2527679980 eCall_Mute_Anf 0 "kein_mute" 1 "mute" ;
VAL_ 996 EFF_Verbraucher_Balken 510 "Init" 511 "Fehler" ;
VAL_ 996 EFF_Verbraucher_Pos_1 0 "keine_Anzeige" 1 "Klimaautomatik" 2 "Standheizung" 3 "Heckscheibe" 4 "Sitzheizung_links" 5 "Sitzheizung_rechts" 6 "Sitzlueftung_links" 7 "Sitzlueftung_rechts" 8 "Nackenheizung_links" 9 "Nackenheizung_rechts" 10 "Nebellicht_vorne" 11 "Nebelschlussleuchte" 12 "Frontscheibenheizung" 13 "Lenkradheizung" 14 "Spiegelheizung" 15 "Sitzheizung_hinten" 16 "Sitzlueftung_hinten" ;
VAL_ 996 EFF_Verbraucher_Pos_2 0 "keine_Anzeige" 1 "Klimaautomatik" 2 "Standheizung" 3 "Heckscheibe" 4 "Sitzheizung_links" 5 "Sitzheizung_rechts" 6 "Sitzlueftung_links" 7 "Sitzlueftung_rechts" 8 "Nackenheizung_links" 9 "Nackenheizung_rechts" 10 "Nebellicht_vorne" 11 "Nebelschlussleuchte" 12 "Frontscheibenheizung" 13 "Lenkradheizung" 14 "Spiegelheizung" 15 "Sitzheizung_hinten" 16 "Sitzlueftung_hinten" ;
VAL_ 996 EFF_Verbraucher_Pos_3 0 "keine_Anzeige" 1 "Klimaautomatik" 2 "Standheizung" 3 "Heckscheibe" 4 "Sitzheizung_links" 5 "Sitzheizung_rechts" 6 "Sitzlueftung_links" 7 "Sitzlueftung_rechts" 8 "Nackenheizung_links" 9 "Nackenheizung_rechts" 10 "Nebellicht_vorne" 11 "Nebelschlussleuchte" 12 "Frontscheibenheizung" 13 "Lenkradheizung" 14 "Spiegelheizung" 15 "Sitzheizung_hinten" 16 "Sitzlueftung_hinten" ;
VAL_ 996 EFF_Einsparhinweis 0 "Init" 1 "Erhoehter_Luftwiderst_Fenster" 2 "Erhoehter_Luftwiderst_Schiebedach" 3 "Erhoehter_Luftwiderst_Fenst_Schiebed" 4 "Nutzung_Motorbremse" 5 "Gaspedal_bei_Motorstart" 6 "Schaltanzeige_beachten" 7 "StartStop_nutzen" 8 "StartStop_einschalten" 9 "Ineff_Betrieb_Klima_Fenster" 10 "Ineff_Betrieb_Klima_Schiebedach" 11 "Ineff_Betrieb_Klima_Fenst_Schiebed" 12 "Fahrstufe_D_verwenden" 13 "Gaspedal_im_Stand" ;
VAL_ 996 EFF_Verbrauch_STH 127 "Fehler" ;
VAL_ 996 MKE_Texte 0 "keine_Anzeige" 1 "Warnstufe_1" 2 "Warnstufe_2" ;
VAL_ 996 MKE_FAS 0 "keine_Anzeige" 1 "Warnstufe_1" 2 "Warnstufe_2" ;
VAL_ 996 MKE_Stufe 0 "deaktiviert" 1 "nicht_verfügbar" 2 "Stufe_1" 3 "Stufe_2" 4 "Stufe_3" 5 "Stufe_4" 6 "reserviert" 7 "reserviert" ;
VAL_ 996 MKE_FAS_Fkt_Status 0 "Init" 1 "Funktion_Ist_Ein" 2 "Funktion_Ist_Aus" 3 "Fehler" ;
VAL_ 996 MKE_Fehlercode 0 "Init" 1 "gueltig" 2 "eingeschraenkt_gueltig" 3 "ungueltig" 4 "nicht_verbaut" ;
VAL_ 1603 KBI_Einheit_Datum 0 "Tag/Monat/Jahr" 1 "Monat/Tag/Jahr" 2 "Jahr/Monat/Tag" 3 "reserviert" ;
VAL_ 1603 KBI_Einheit_Druck 0 "Druckangabe in bar" 1 "Druckangabe in psi" 2 "Druckangabe in kPa" 3 "tbd." ;
VAL_ 1603 KBI_Einheit_Streckenanz 0 "Kilometer" 1 "Meilen" ;
VAL_ 1603 KBI_MFA_v_Einheit_02 0 "kmh" 1 "mph" ;
VAL_ 1603 KBI_Einheit_Temp 0 "Grad Celsius °C" 1 "Grad Fahrenheit °F" ;
VAL_ 1603 KBI_Einheit_Uhrzeit 0 "24h" 1 " 12h AM/PM" ;
VAL_ 1603 KBI_Einheit_Verbrauch 0 "mpg UK" 1 "mpg USA" 2 "Liter/100km" 3 "km/Liter" ;
VAL_ 1603 KBI_Einheit_Volumen 0 "Liter" 1 "Gallonen UK" 2 "Gallonen USA" 3 "reserviert" ;
VAL_ 1603 KBI_Einheit_Verbrauch_elektr 0 "kWh_pro_100km" 1 "km_pro_kWh" 2 "kWh_pro_100mls" 3 "mls_pro_kWh" 4 "MPGe" ;
VAL_ 1603 KBI_Einheit_Verbrauch_Gas 0 "kg_per_100km" 1 "km_per_kg" 2 "m3_per_100km" 3 "km_per_m3" 4 "miles_per_lbs" 5 "miles_per_yard3" 6 "miles_per_kg" 7 "miles_per_m3" 8 "miles_per_gallon_equivalent_US" ;
VAL_ 1603 KBI_Einheit_Masse 0 "kg" 1 "lbs" 2 "reserviert" ;
VAL_ 1622 ELV_Anf_Klemme_S 0 "Aus" 1 "Ein" ;
VAL_ 1622 ELV_Anf_Klemme_15 0 "Aus" 1 "Ein" ;
VAL_ 1622 ELV_Anf_Klemme_50 0 "Aus" 1 "Ein" ;
VAL_ 1622 ELV_01_Sendestatus 0 "ELV_sendet_mit_1000ms" 1 "ELV_sendet_mit_50ms" ;
VAL_ 1622 ELV_Verriegelt 0 "nicht_verriegelt" 1 "verriegelt" ;
VAL_ 1622 ELV_Entriegelt 0 "ELV_nicht_entriegelt" 1 "ELV_entriegelt" ;
VAL_ 1622 ELV_ZAT_betaetigt 0 "nicht_betaetigt" 1 "betaetigt" ;
VAL_ 1622 ELV_Lebenszustand 0 "Lebenszustand_0" 1 "Lebenszustand_4" ;
VAL_ 1622 ELV_Anlernmodus 0 "Normalbetrieb" 1 "Anlernmodus" ;
VAL_ 1622 ELV_Klemmenfreigabe 0 "keine_Freigabe" 1 "Freigabe" ;
VAL_ 1622 ELV_Abbruch_Anf_Klemmenfreigabe 0 "kein_Abbruch" 1 "Abbruch" ;
VAL_ 1622 ELV_LED_Rot 0 "Aus" 1 "Ein" ;
VAL_ 1622 ELV_LED_Gelb 0 "Aus" 1 "Ein" ;
VAL_ 1622 ELV_Txt_Panikabschaltung 0 "Aus" 1 "Ein" ;
VAL_ 1622 ELV_Txt_Lkg_Bewegen 0 "Aus" 1 "Ein" ;
VAL_ 1622 ELV_Txt_Werkstatt 0 "Aus" 1 "Ein" ;
VAL_ 1622 ELV_Txt_Defekt 0 "Aus" 1 "Ein" ;
VAL_ 1622 ELV_Txt_P_Gang 0 "Aus" 1 "Ein" ;
VAL_ 1622 ELV_Txt_PN_Gang 0 "Aus" 1 "Ein" ;
VAL_ 1622 ELV_Txt_Kupplung 0 "Aus" 1 "Ein" ;
VAL_ 1622 ELV_Txt_Bremse 0 "Aus" 1 "Ein" ;
VAL_ 1622 ELV_P_verriegelt 0 "nicht_verriegelt" 1 "verriegelt" ;
VAL_ 115 EM1_IstMoment 4094 "Init" 4095 "Fehler" ;
VAL_ 115 EM1_IstDrehzahl_alt 32766 "Init" 32767 "Fehler" ;
VAL_ 115 EM1_IstDrehzahl 32766 "Init" 32767 "Fehler" ;
VAL_ 115 EM1_MaxZul_Drehzahl 254 "Init" 255 "Fehler" ;
VAL_ 260 EPB_QBit_Pedalweg_Kuppl 0 "gültiger Wert" 1 "Ersatz-, Init- oder Fehlerwert" ;
VAL_ 260 EPB_Freig_Verzoeg_Anf 0 "nicht freigegeben" 1 "freigegeben" ;
VAL_ 260 EPB_Pedalweg_Kuppl 0 "Init" 255 "Fehler" ;
VAL_ 260 EPB_DAA_Randbed_erf 0 "Randbed_nicht_erfuellt" 1 "Randbed_erfuellt" ;
VAL_ 260 EPB_Fehlerstatus_02 0 "kein_Fehler" 1 "Fehler_ausserhalb_apply_release" 2 "Fehler_einseitig_apply_release" 3 "Fehler_beidseitig_apply_release" ;
VAL_ 260 EPB_Schalterposition 0 "keine Fahreranforderung" 1 "Fahreranforderung Öffnen" 2 "Fahreranforderung Schließen" 3 "Fehler" ;
VAL_ 260 EPB_QBit_Schalterpos 0 "gültiger Wert (volle Funktion)" 1 " Ersatz-, Init- oder Fehlerwert (Schalter ausser Funktion)" ;
VAL_ 260 EPB_Spannkraft 30 "Init" 31 "Fehler" ;
VAL_ 260 EPB_Status_02 0 "offen" 1 "geschlossen_Parken" 2 "teilgespannt_Halten" 3 "im_Lauf_oeffnen" 4 "im_Lauf_schliessen" 5 "tbd" 6 "Init" 7 "unbekannt" ;
VAL_ 781 EPB_Fehlerlampe_Gelb 0 "Aus" 1 "Ein" ;
VAL_ 781 EPB_Fehlerlampe_BKL 0 "BKL aus" 1 "BKL an" ;
VAL_ 781 EPB_Funktionslampe 0 "Aus" 1 "Ein" ;
VAL_ 781 EPB_Texte 0 "keine_Anzeige" 1 "Neigungswinkel_zu_gross" 2 "Parkbremse_von_Hand_oeffnen" 3 "HU_Modus_oder_EPB_in_Diagnose" 4 "Bremspedal_betaetigen" 5 "tbd" 6 "tbd" 7 "Stoerung_Anfahrassistent" 8 "Motor_starten" 9 "Feststellbremse_nicht_automatisch_geschlossen" 10 "Parkbremse_loesen_nicht_moeglich_Ladekabel_gesteckt" 11 "Notbremsung_ueber_EPB_Taster" 12 "Parkbremse_angezogen" 13 "Parkbremse_loesen_nicht_moeglich_ParkPilot_aktiv" ;
VAL_ 781 EPB_Akustik 0 "Warnton aus" 1 "Warnton an" ;
VAL_ 781 EPB_Autoholdlampe 0 "Lampe aus (Autohold inaktiv)" 1 "Lampe ein (Autohold aktiv)" ;
VAL_ 781 EPB_Bremsbelag_Warn 0 "Bremsbelag_ok" 1 "Bremsbelag_unter_Minimum" ;
VAL_ 781 EPB_Fehlermeldungen 0 "keine_Anzeige" 1 "Systemstoerung_Kl15an" 2 "Systemstoerung_Kl15aus" 3 "Parkbremse_betaetigen" 4 "Systemstoerung_Hanghaltefaehigkeit" 5 "Funktionseinschraenkung_Kl15an" 6 "Funktionseinschraenkung_Kl15aus" 7 "HU_Modus_aktiv" 8 "Transportmodus" 9 "Produktionsmodus" 10 "FktEinschr_Taster_defekt" ;
VAL_ 259 ESP_VL_FR 0 "Vorwaerts" 1 "Rueckwaerts" ;
VAL_ 259 ESP_VR_FR 0 "Vorwaerts" 1 "Rueckwaerts" ;
VAL_ 259 ESP_HL_FR 0 "Vorwaerts" 1 "Rueckwaerts" ;
VAL_ 259 ESP_HR_FR 0 "Vorwaerts" 1 "Rueckwaerts" ;
VAL_ 259 ESP_VL_Radgeschw 4093 "Unterspannung" 4094 "Init" 4095 "Fehler" ;
VAL_ 259 ESP_VR_Radgeschw 4093 "Unterspannung" 4094 "Init" 4095 "Fehler" ;
VAL_ 259 ESP_HL_Radgeschw 4093 "Unterspannung" 4094 "Init" 4095 "Fehler" ;
VAL_ 259 ESP_HR_Radgeschw 4093 "Unterspannung" 4094 "Init" 4095 "Fehler" ;
VAL_ 262 ESP_QBit_Bremsdruck 0 "gueltiger_Wert" 1 "Ersatz_Init_oder_Fehlerwert" ;
VAL_ 262 ESP_QBit_Fahrer_bremst 0 "gueltiger_Wert" 1 "Ersatz_Init_oder_Fehlerwert" ;
VAL_ 262 ESP_Schwelle_Unterdruck 0 "kein_Signal" 1 "Unterdruck_kleiner_gleich_450_mbar" 2 "Unterdruck_groesser_450_mbar" 3 "Fehler_Unterdrucksensor" ;
VAL_ 262 ESP_Bremsdruck 1023 "Fehler" ;
VAL_ 262 ESP_Fahrer_bremst 0 "Bremsdruckschwelle_nicht_ueberschritten" 1 "Bremsdruckschwelle_ueberschritten" ;
VAL_ 262 ESP_Lenkeingriff_ADS 0 "kein_Lenkeingriff" 1 "stabilisierender_Lenkeingriff" ;
VAL_ 262 ECD_Fehler 0 "ECD_iO" 1 "ECD_Fehler" ;
VAL_ 262 ECD_nicht_verfuegbar 0 "ECD_Funktion_verfuegbar" 1 "ECD_Funktion_nicht_verfuegbar" ;
VAL_ 262 ESP_Status_Bremsentemp 0 "Bremse_nicht_ueberhitzt" 1 "Bremse_ueberhitzt" ;
VAL_ 262 ESP_Autohold_Standby 0 "Autohold_nicht_im_Standby" 1 "Autohold_im_Standby" ;
VAL_ 262 ESP_HDC_Standby 0 "HDC_Funktion_nicht_im_Standby" 1 "HDC_Funktion_im_Standby" ;
VAL_ 262 ESP_HBA_aktiv 0 "HBA_nicht_aktiv" 1 "HBA_aktiv" ;
VAL_ 262 ESP_Prefill_ausgeloest 0 "nicht_ausgeloest" 1 "Prefill_ausgeloest" ;
VAL_ 262 ESP_Rueckwaertsfahrt_erkannt 0 "keine_Rueckwaetsfahrt" 1 "Rueckwaertsfahrt_sicher_erkannt" ;
VAL_ 262 ESP_Status_Anfahrhilfe 0 "Aus" 1 "Ein" ;
VAL_ 262 ESP_HDC_aktiv 0 "inaktiv" 1 "aktiv" ;
VAL_ 262 ESP_StartStopp_Info 0 "Motorlauf_nicht_notwendig_(Stoppfreigabe)" 1 "Motoranlauf_nicht_zwingend_notwendig_(Stoppverbot,keine_Startanforderung)" 2 "Motoranlauf_zwingend_notwendig_(Startanforderung)" 3 "Systemfehler" ;
VAL_ 262 ESP_Eingr_HL 0 "kein_Eingriff" 1 "ESP_Eingriff_HL" ;
VAL_ 262 ESP_Eingr_HR 0 "kein_Eingriff" 1 "ESP_Eingriff_HR" ;
VAL_ 262 ESP_Eingr_VL 0 "kein_Eingriff" 1 "ESP_Eingriff_VL" ;
VAL_ 262 ESP_Eingr_VR 0 "kein_Eingriff" 1 "ESP_Eingriff_VR" ;
VAL_ 262 ESP_BKV_Unterdruck 0 "nicht_verbaut_oder_nicht_kodiert" 254 "Init" 255 "Fehler" ;
VAL_ 262 ESP_Autohold_aktiv 0 "Autohold_inaktiv" 1 "Autohold_aktiv" ;
VAL_ 262 ESP_FStatus_Anfahrhilfe 0 "kein_Fehler" 1 "Fehler" ;
VAL_ 262 ESP_Verz_EPB_aktiv 0 "nicht_aktiviert" 1 "aktiviert" ;
VAL_ 262 ESC_Bremslicht 0 "Aus" 1 "Ein" ;
VAL_ 262 ESP_Verzoeg_EPB_verf 0 "nicht_verfuegbar" 1 "System_verfuegbar" ;
VAL_ 262 ESP_Status_Bremsdruck 0 "Bremse_drucklos" 1 "mit_Bremsdruck" ;
VAL_ 262 ESP_Anforderung_EPB 0 "keine_Anforderung" 1 "Anforderung_Oeffnen" 2 "Anforderung_Schliessen" 3 "reserviert" ;
VAL_ 914 ESP_Allrad_Antrieb 0 "Front" 1 "Allrad" ;
VAL_ 914 ESP_Codierung_ADS 0 "Init" 1 "ESP_nicht_ADS_codiert" 2 "ADS_codiert" 3 "tbd" ;
VAL_ 914 ESP_RTA_HL 254 "Abgleich_nocht_nicht_genuegend_konvergent" 255 "Fehler" ;
VAL_ 914 ESP_RTA_HR 254 "Abgleich_nocht_nicht_genuegend_konvergent" 255 "Fehler" ;
VAL_ 914 ESP_RTA_VR 254 "Abgleich_nocht_nicht_genuegend_konvergent" 255 "Fehler" ;
VAL_ 914 OBD_Fehler_Radsensor_HL 0 "kein Fehler / Init / nicht verbaut" 1 "KS- (Kurzschluss nach minus)" 2 "KS+ (Kurzschluss nach plus)" 3 "OC (Leitungsunterbrechung)" 4 "OOR+ (Signal zu gross)" 5 "OOR- (Signal zu klein)" 6 "RC+ (Signal unplausibel zu gross)" 7 "RC- (Signal unplausibel zu klein)" 8 "KS+/OC (Kurzschluss nach plus/Unterbrechung)" 9 "KS-/OC  (Kurzschluss nach minus/Unterbrechung)" 10 "KS-/KS+  (Kurzschluss nach minus/plus)" 11 "KS-/KS+/OC (Kurzschluss nach minus/plus/Unterbrechung)" 12 "frei" 13 "frei" 14 "frei" 15 "frei" ;
VAL_ 914 OBD_Fehler_Radsensor_HR 0 "kein Fehler / Init / nicht verbaut" 1 "KS- (Kurzschluss nach minus)" 2 "KS+ (Kurzschluss nach plus)" 3 "OC (Leitungsunterbrechung)" 4 "OOR+ (Signal zu gross)" 5 "OOR- (Signal zu klein)" 6 "RC+ (Signal unplausibel zu gross)" 7 "RC- (Signal unplausibel zu klein)" 8 "KS+/OC (Kurzschluss nach plus/Unterbrechung)" 9 "KS-/OC  (Kurzschluss nach minus/Unterbrechung)" 10 "KS-/KS+  (Kurzschluss nach minus/plus)" 11 "KS-/KS+/OC (Kurzschluss nach minus/plus/Unterbrechung)" 12 "frei" 13 "frei" 14 "frei" 15 "frei" ;
VAL_ 914 OBD_Fehler_Radsensor_VL 0 "kein Fehler / Init / nicht verbaut" 1 "KS- (Kurzschluss nach minus)" 2 "KS+ (Kurzschluss nach plus)" 3 "OC (Leitungsunterbrechung)" 4 "OOR+ (Signal zu gross)" 5 "OOR- (Signal zu klein)" 6 "RC+ (Signal unplausibel zu gross)" 7 "RC- (Signal unplausibel zu klein)" 8 "KS+/OC (Kurzschluss nach plus/Unterbrechung)" 9 "KS-/OC  (Kurzschluss nach minus/Unterbrechung)" 10 "KS-/KS+  (Kurzschluss nach minus/plus)" 11 "KS-/KS+/OC (Kurzschluss nach minus/plus/Unterbrechung)" 12 "frei" 13 "frei" 14 "frei" 15 "frei" ;
VAL_ 914 OBD_Fehler_Radsensor_VR 0 "kein Fehler / Init / nicht verbaut" 1 "KS- (Kurzschluss nach minus)" 2 "KS+ (Kurzschluss nach plus)" 3 "OC (Leitungsunterbrechung)" 4 "OOR+ (Signal zu gross)" 5 "OOR- (Signal zu klein)" 6 "RC+ (Signal unplausibel zu gross)" 7 "RC- (Signal unplausibel zu klein)" 8 "KS+/OC (Kurzschluss nach plus/Unterbrechung)" 9 "KS-/OC  (Kurzschluss nach minus/Unterbrechung)" 10 "KS-/KS+  (Kurzschluss nach minus/plus)" 11 "KS-/KS+/OC (Kurzschluss nach minus/plus/Unterbrechung)" 12 "frei" 13 "frei" 14 "frei" 15 "frei" ;
VAL_ 914 ESP_Qualifizierung_Antriebsart 0 "alte_Bedeutung_Bit_ESP_Allrad_Antrieb" 1 "neue_Bedeutung_Bit_ESP_Allrad_Antrieb" ;
VAL_ 914 ESP_Offroad_Modus 0 "kein_ESP_Offroadmodus" 1 "ESP_Offroadmodus" ;
VAL_ 914 ESP_MKB_ausloesbar 0 "Multikollisionsbremsung_nicht_freigeschaltet" 1 "Multikollisionsbremsung_freigeschaltet" ;
VAL_ 914 ESP_Stat_FallBack_eBKV 0 "Rueckfallebene_nicht_vorhanden" 1 "Rueckfallebene_vorhanden" ;
VAL_ 914 ESC_cAQP_Trigger 0 "AQP_Trigger_nicht_aktiv" 1 "AQP_Trigger_aktiv" ;
VAL_ 914 ESP_OBD_Status 0 "MIL_aus" 1 "MIL_ein" ;
VAL_ 914 ESP_Rollenmodus_Deaktivieren 0 "keine_Aenderung" 1 "Abbruch" ;
VAL_ 914 ESP_nachtr_Stopp_Anf 0 "nicht_angefordert" 1 "angefordert" ;
VAL_ 278 ESP_QBit_Wegimpuls_VL 0 "gueltiger_Wert" 1 "Ersatz_Init_oder_Fehlerwert" ;
VAL_ 278 ESP_QBit_Wegimpuls_VR 0 "gueltiger_Wert" 1 "Ersatz_Init_oder_Fehlerwert" ;
VAL_ 278 ESP_QBit_Wegimpuls_HL 0 "gueltiger_Wert" 1 "Ersatz_Init_oder_Fehlerwert" ;
VAL_ 278 ESP_QBit_Wegimpuls_HR 0 "gueltiger_Wert" 1 "Ersatz_Init_oder_Fehlerwert" ;
VAL_ 278 ESP_Wegimpuls_VL 1021 "Init" 1022 "Unterspannung" 1023 "Fehler" ;
VAL_ 278 ESP_Wegimpuls_VR 1021 "Init" 1022 "Unterspannung" 1023 "Fehler" ;
VAL_ 278 ESP_Wegimpuls_HL 1021 "Init" 1022 "Unterspannung" 1023 "Fehler" ;
VAL_ 278 ESP_Wegimpuls_HR 1021 "Init" 1022 "Unterspannung" 1023 "Fehler" ;
VAL_ 278 ESP_VL_Fahrtrichtung 0 "Vorwaerts" 1 "Rueckwaerts" 2 "Init" 3 "ungueltig_oder_nicht_verbaut" ;
VAL_ 278 ESP_VR_Fahrtrichtung 0 "Vorwaerts" 1 "Rueckwaerts" 2 "Init" 3 "ungueltig_oder_nicht_verbaut" ;
VAL_ 278 ESP_HL_Fahrtrichtung 0 "Vorwaerts" 1 "Rueckwaerts" 2 "Init" 3 "ungueltig_oder_nicht_verbaut" ;
VAL_ 278 ESP_HR_Fahrtrichtung 0 "Vorwaerts" 1 "Rueckwaerts" 2 "Init" 3 "ungueltig_oder_nicht_verbaut" ;
VAL_ 418 HMS_P_beibehalten_GE 0 "P_nicht_beibehalten" 1 "P_beibehalten" 2 "Init" 3 "Fehler" ;
VAL_ 418 HMS_Konsistenz_GE 0 "kein_Fehler_erkannt" 1 "Fehler_erkannt" ;
VAL_ 418 HMS_Konsistenz_IPA 0 "kein_Fehler_erkannt" 1 "Fehler_erkannt" ;
VAL_ 418 HMS_Konsistenz_STA 0 "kein_Fehler_erkannt" 1 "Fehler_erkannt" ;
VAL_ 418 HMS_Konsistenz_MO 0 "kein_Fehler_erkannt" 1 "Fehler_erkannt" ;
VAL_ 418 HMS_halten_nicht_verfuegbar 0 "verfuegbar" 1 "nicht_verfuegbar" ;
VAL_ 418 NL_PRIM_STP_01_Status 0 "Notlauf_inaktiv" 1 "Notlauf_bereit" 2 "Notlauf_aktiv" 3 "Notlauf_nicht_verfuegbar" 4 "Notlauf_aktivierbar" ;
VAL_ 418 VMM_Warnblinken 0 "Aus" 1 "An" ;
VAL_ 418 VZM_Status 0 "Initialisierung" 1 "Verfuegbar" 2 "Verfuegbar_mit_eingeschraenkter_Performance" 3 "Nicht_Verfuegbar" 4 "Fehler" ;
VAL_ 418 HMS_Notstopp_Status 0 "Off_Init" 1 "Inaktiv" 2 "Ready" 3 "Aktiv" 4 "Pending" 7 "nicht_Verfuegbar" ;
VAL_ 418 HMS_parken_nicht_verfuegbar 0 "verfuegbar" 1 "nicht_verfuegbar" ;
VAL_ 418 HMS_Anforderung_GE 0 "keine_Anforderung" 1 "P_einlegen" ;
VAL_ 418 HMS_Systemstatus 0 "keine_Funktion_aktiv" 1 "Halten_aktiv" 2 "Parken_angefordert" 3 "Parken_aktiv" 4 "Parken_beibehalten_aktiv" 5 "Anfahren_aktiv" 6 "Loeseanforderung_aktiv" 7 "Loeseanforderung_durch_Fahrer" 8 "Abrutschen_erkannt" 9 "Halten_Standby_aktiv" 10 "Anfahren_Standby_aktiv" 14 "Init" 15 "Fehler" ;
VAL_ 418 HMS_Stillstand 0 "kein_Stillstand" 1 "Stillstand_frueh" 2 "Stillstand" 6 "Init" 7 "Fehler" ;
VAL_ 418 HMS_aktives_System 0 "kein_System__Init_Fehler" 1 "Fahreranforderung_aktiv" 2 "HMS_intern_aktiv" 3 "ACC_aktiv" 4 "Autohold_aktiv" 5 "HHC_aktiv" 6 "HVLM_aktiv" 7 "Getriebe_aktiv" 8 "EBKV_aktiv" 9 "ParkAssist_aktiv" 10 "ARA_aktiv" 12 "autonomous_Hold_aktiv" 13 "STA_aktiv" 14 "Motor_aktiv" 15 "EA_aktiv" 16 "VLK_aktiv" ;
VAL_ 418 HMS_Konsistenz_HVLM 0 "kein_Fehler_erkannt" 1 "Fehler_erkannt" ;
VAL_ 418 HMS_Konsistenz_ACC 0 "kein_Fehler_erkannt" 1 "Fehler_erkannt" ;
VAL_ 418 HMS_Fehlerstatus 0 "kein_Fehler" 1 "Halten_nicht_moeglich" 2 "Sonderbetriebsmodus_aktiv" 3 "Systemeinschraenkung" 4 "Systemstoerung" ;
VAL_ 418 ESP_Index_Haltemoment 0 "Bremsmoment" 1 "Antriebsmoment" ;
VAL_ 418 ESP_Haltemoment 1022 "Init" 1023 "Fehler" ;
VAL_ 1629 BR_Systemart 0 "ABS" 1 "ABS_ASR" 2 "ESP" 3 "ESP_mit_integrierter_EPB" ;
VAL_ 1629 ESP_SpannungsAnf_02 0 "keine_Anforderung" 1 "Anforderung_Stufe1" 2 "Anforderung_Stufe2" 3 "Anforderung_Stufe3" ;
VAL_ 1629 ESP_Charisma_FahrPr 0 "keine_Funktion" 1 "Programm_1" 2 "Programm_2" 3 "Programm_3" 4 "Programm_4" 5 "Programm_5" 6 "Programm_6" 7 "Programm_7" 8 "Programm_8" 9 "Programm_9" 10 "Programm_10" 11 "Programm_11" 12 "Programm_12" 13 "Programm_13" 14 "Programm_14" 15 "Programm_15" ;
VAL_ 1629 ESP_Charisma_Status 0 "Init" 1 "verfuegbar" 2 "nicht_verfuegbar" 3 "asynchron_durch_Fahrerwunsch" ;
VAL_ 1629 ESP_Wiederstart_Anz_01 0 "keine_Anzeige" 1 "Rueckwaertsrollen" ;
VAL_ 1629 ESP_Wiederstart_Anz_02 0 "keine_Anzeige" 1 "Autohold_Rutschen" ;
VAL_ 1629 ESP_Wiederstart_Anz_03 0 "keine_Anzeige" 1 "Offroad_HDC" ;
VAL_ 1629 ESP_Wiederstart_Anz_04 0 "keine_Anzeige" 1 "ESC_Off" ;
VAL_ 1629 ESP_Stoppverbot_Anz_01 0 "keine_Anzeige" 1 "Notbremsung_aktiv" ;
VAL_ 1629 ESP_Stoppverbot_Anz_02 0 "keine_Anzeige" 1 "Autohold_AVH_Rutschen" ;
VAL_ 1629 ESP_Stoppverbot_Anz_03 0 "keine_Anzeige" 1 "Rueckwaertsrollen" ;
VAL_ 1629 ESP_Stoppverbot_Anz_04 0 "keine_Anzeige" 1 "ESP_Pumpenlauf" ;
VAL_ 1629 ESP_Stoppverbot_Anz_05 0 "keine_Anzeige" 1 "ESP_OFF" ;
VAL_ 1629 ESP_Stoppverbot_Anz_06 0 "keine_Anzeige" 1 "Offroad_HDC" ;
VAL_ 1629 ESP_Stoppverbot_Anz_07 0 "keine_Anzeige" 1 "ESP_Haltefunktion_nicht_verfuegbar" ;
VAL_ 1629 ESP_Stoppverbot_Anz_Std 0 "keine_Anzeige" 1 "Standard_Stoppvetogrund" ;
VAL_ 1629 ESP_Dachrelingsensor 0 "Sensor_nicht_verbaut" 1 "Quertraeger_montiert" 2 "Quertraeger_nicht_montiert" 3 "Fehler" ;
VAL_ 1629 ESP_Stoppverbot_Anz_08 0 "keine_Anzeige" 1 "Neigungsbegrenzung" ;
VAL_ 1629 HDC_Charisma_FahrPr 0 "keine_Funktion" 1 "Programm_1" 2 "Programm_2" 3 "Programm_3" 4 "Programm_4" 5 "Programm_5" 6 "Programm_6" 7 "Programm_7" 8 "Programm_8" 9 "Programm_9" 10 "Programm_10" 11 "Programm_11" 12 "Programm_12" 13 "Programm_13" 14 "Programm_14" 15 "Programm_15" ;
VAL_ 1629 HDC_Charisma_Status 0 "Init" 1 "verfuegbar" 2 "nicht_verfuegbar" 3 "asynchron_durch_Fahrerwunsch" ;
VAL_ 1629 BR_QBit_Reifenumfang 0 "gueltiger_Wert" 1 "Ersatz_Init_oder_Fehlerwert" ;
VAL_ 253 BR_Eingriffsmoment 1022 "Init" 1023 "Fehler" ;
VAL_ 253 MSR_verfuegbar 0 "verfuegbar" 1 "nicht_verfuegbar" ;
VAL_ 253 ESP_Diagnose 0 "ESP_nicht_in_Diagnose" 1 "ESP_in_Diagnose" ;
VAL_ 253 ESC_v_Signal_Qualifier_High_Low 0 "Gueteschwelle_kleiner_1kmh" 1 "Gueteschwelle_kleiner_3kmh" 2 "Gueteschwelle_kleiner_5kmh" 3 "Gueteschwelle_kleiner_10kmh" 4 "Gueteschwelle_kleiner_20kmh" 5 "Gueteschwelle_groessergleich_20kmh" 6 "Init" 7 "Fehler" ;
VAL_ 253 ESP_Vorsteuerung 0 "keine_Vorsteuerung_aktiv" 1 "Vorsteuerung_aktiv" ;
VAL_ 253 OBD_Schlechtweg 0 "kein_Schlechtweg_erkannt" 1 "Schlechtweg_erkannt" ;
VAL_ 253 OBD_QBit_Schlechtweg 0 "gueltiger_Wert" 1 "Ersatz_Init_oder_Fehlerwert" ;
VAL_ 253 ESP_v_Signal 65533 "Unterspannung" 65534 "Init" 65535 "Fehler" ;
VAL_ 253 ASR_Tastung_passiv 0 "ASR_aktiviert" 1 "ASR_passiv_getastet_oder_Schwellen_geaendert" ;
VAL_ 253 ESP_Tastung_passiv 0 "ESP_aktiviert" 1 "ESP_passiv_getastet_oder_Schwellen_geaendert" ;
VAL_ 253 ESP_Systemstatus 0 "iO" 1 "Fehler" ;
VAL_ 253 ASR_Schalteingriff 0 "keine_Anforderung" 1 "ASR_Schaltkennfeld" 2 "Rueckschaltung" 3 "Schaltverbot" ;
VAL_ 253 ESP_QBit_v_Signal 0 "gueltiger_Wert" 1 "Ersatz_Init_oder_Fehlerwert" ;
VAL_ 253 ABS_Bremsung 0 "keine_ABS_Regelung" 1 "ABS_Regelung_aktiv" ;
VAL_ 253 ASR_Anf 0 "keine_Anforderung" 1 "ASR_Anforderung" ;
VAL_ 253 MSR_Anf 0 "keine Anfoderung" 1 "MSR-Anforderung" ;
VAL_ 253 EBV_Eingriff 0 "kein_EBV_Eingriff" 1 "EBV_Eingriff" ;
VAL_ 253 EDS_Eingriff 0 "kein_EDS_Eingriff" 1 "EDS_Eingriff" ;
VAL_ 253 ESP_Eingriff 0 "kein_ESP_Eingriff" 1 "ESP_Eingriff_aktiv" ;
VAL_ 253 ESP_ASP 0 "inaktiv" 1 "aktiv" ;
VAL_ 253 ESC_Neutralschaltung 0 "keine_Anforderung" 1 "Neutralschaltung_angefordert" ;
VAL_ 239 ESP_QBit_VL_Bremsmoment 0 "gueltiger_Wert" 1 "Ersatz_Init_oder_Fehlerwert" ;
VAL_ 239 ESP_QBit_VR_Bremsmoment 0 "gueltiger_Wert" 1 "Ersatz_Init_oder_Fehlerwert" ;
VAL_ 239 ESP_QBit_HL_Bremsmoment 0 "gueltiger_Wert" 1 "Ersatz_Init_oder_Fehlerwert" ;
VAL_ 239 ESP_QBit_HR_Bremsmoment 0 "gueltiger_Wert" 1 "Ersatz_Init_oder_Fehlerwert" ;
VAL_ 239 ESP_VL_Bremsmoment 254 "Init" 255 "Fehler" ;
VAL_ 239 ESP_VR_Bremsmoment 254 "Init" 255 "Fehler" ;
VAL_ 239 ESP_HL_Bremsmoment 254 "Init" 255 "Fehler" ;
VAL_ 239 ESP_HR_Bremsmoment 254 "Init" 255 "Fehler" ;
VAL_ 239 ESP_FZR_uebersteuern 254 "Init" 255 "Fehler" ;
VAL_ 239 ESP_FZR_untersteuern 254 "Init" 255 "Fehler" ;
VAL_ 1470 ESP_Gierrate_Offset_2 2046 "Init" 2047 "Fehler" ;
VAL_ 1470 ESP_Lenkwinkel_Offset 510 "Init" 511 "Fehler" ;
VAL_ 1470 BR_QBit_Reifenumfang_sekundaer 0 "gueltiger_Wert" 1 "Ersatz_Init_oder_Fehlerwert" ;
VAL_ 1470 ESP_Status_Bremsentemp_Anz 0 "Init" 1 "kalt" 2 "warm" 3 "heiss" 4 "ueberhitzt" 5 "nass" 7 "Fehler" ;
VAL_ 1470 ESP_Querbeschleunigung_Offset 62 "Init" 63 "Fehler" ;
VAL_ 1470 ESP_Laengsbeschleunigung_Offset 254 "Init" 255 "Fehler" ;
